VERSION ""

NS_ :

BS_:

BU_: ICC_ICE DVR EPC BBCM PCL PLG EAMP CMSM SBOX AVAS FLZCU RXCU_HCU CGW TBOX BNCM CWC FRZCU

BO_ 1238 ICC_TMS_32: 32 ICC_ICE
 SG_ ICC_CFSSwitch : 17|2@0+ (1,0) [0|3] "" Vector__XXX
 SG_ ICC_CFSLevelSet : 20|3@0+ (1,0) [0|7] "" Vector__XXX
 SG_ ICC_CFSPosSet : 23|2@0+ (1,0) [0|3] "" Vector__XXX
 SG_ ICC_PM25Switch : 25|2@0+ (1,0) [0|3] "" Vector__XXX
 SG_ ICC_AQSSwitch : 27|2@0+ (1,0) [0|3] "" Vector__XXX
 SG_ ICC_SecSetTemp_C : 36|5@0+ (0.5,15.5) [15.5|30.5] "℃" Vector__XXX
 SG_ ICC_SecFaceKeySts : 39|2@0+ (1,0) [0|3] "" Vector__XXX
 SG_ ICC_SecFootKeySts : 41|2@0+ (1,0) [0|3] "" Vector__XXX
 SG_ ICC_SecBlowSpeedLevelKeySts : 45|4@0+ (1,0) [0|15] "" Vector__XXX
 SG_ ICC_SecAutoSwitch : 47|2@0+ (1,0) [0|3] "" Vector__XXX
 SG_ ICC_SecCLMSwitch : 49|2@0+ (1,0) [0|3] "" Vector__XXX
 SG_ ICC_ThrSetTemp_C : 54|5@0+ (0.5,15.5) [15.5|30.5] "℃" Vector__XXX
 SG_ ICC_ThrFaceKeySts : 57|2@0+ (1,0) [0|3] "" Vector__XXX
 SG_ ICC_ThrFootKeySts : 59|2@0+ (1,0) [0|3] "" Vector__XXX
 SG_ ICC_ThrBlowSpeedLevelKeySts : 63|4@0+ (1,0) [0|15] "" Vector__XXX
 SG_ ICC_ThrAutoSwitch : 81|2@0+ (1,0) [0|3] "" Vector__XXX
 SG_ ICC_ThrCLMSwitch : 83|2@0+ (1,0) [0|3] "" Vector__XXX
 SG_ ICC_ThrACRequestKeySts : 85|2@0+ (1,0) [0|3] "" Vector__XXX
 SG_ ICC_DFMSwitch : 87|2@0+ (1,0) [0|3] "" Vector__XXX

BO_ 1289 ICC_34: 32 ICC_ICE
 SG_ ICC_TirePressureDisplayUnit : 23|2@0+ (1,0) [0|3] ""  TBOX
 SG_ ICC_TireTemperatureDisplayUnit : 21|2@0+ (1,0) [0|3] ""  TBOX
 SG_ ICC_ToggleUnits : 19|2@0+ (1,0) [0|3] ""  TBOX
 SG_ ICC_BtConFlag : 28|3@0+ (1,0) [0|7] ""  SBOX,TBOX
 SG_ ICC_GPSSwitchSet : 25|2@0+ (1,0) [0|3] ""  TBOX

BO_ 1167 ICC_35: 32 ICC_ICE
 SG_ ICC_KeyDriveModememory : 17|2@0+ (1,0) [0|3] ""  FLZCU,RXCU_HCU
 SG_ ICC_DriveModeSet : 22|5@0+ (1,0) [0|31] ""  FLZCU,RXCU_HCU
 SG_ ICC_DRIFTModeSetReq : 25|2@0+ (1,0) [0|3] ""  FLZCU,RXCU_HCU
 SG_ ICC_EXPERTEIPBESPSet : 27|2@0+ (1,0) [0|3] ""  FLZCU,RXCU_HCU
 SG_ ICC_EXPERTEcoSet : 29|2@0+ (1,0) [0|3] ""  FLZCU,RXCU_HCU
 SG_ ICC_EXPERTNormSet : 31|2@0+ (1,0) [0|3] ""  FLZCU,RXCU_HCU
 SG_ ICC_EXPERTSportSet : 33|2@0+ (1,0) [0|3] ""  FLZCU,RXCU_HCU
 SG_ ICC_CrossaxisSet : 35|2@0+ (1,0) [0|3] ""  FLZCU,RXCU_HCU
 SG_ ICC_EXPERTRWDSet : 37|2@0+ (1,0) [0|3] ""  FLZCU,RXCU_HCU
 SG_ ICC_EXPERTAWDSet : 39|2@0+ (1,0) [0|3] ""  FLZCU,RXCU_HCU
 SG_ ICC_EXPERTAutoSet : 41|2@0+ (1,0) [0|3] ""  FLZCU,RXCU_HCU
 SG_ ICC_CLIMBSet : 43|2@0+ (1,0) [0|3] ""  FLZCU,RXCU_HCU
 SG_ ICC_DriveModeExitSet : 45|2@0+ (1,0) [0|3] ""  FLZCU,RXCU_HCU
 SG_ ICC_CCOSwtReq : 49|2@0+ (1,0) [0|3] "" Vector__XXX
 SG_ ICC_TABSwtReq : 51|2@0+ (1,0) [0|3] "" Vector__XXX
 SG_ ICC_Confidencelevel : 62|7@0+ (1,-1) [0|100] "%"  FLZCU,RXCU_HCU
 SG_ ICC_V2L_IntlDisChg : 81|2@0+ (1,0) [0|3] ""  FLZCU,RXCU_HCU
 SG_ ICC_ExhibitionModeSwitch : 83|2@0+ (1,0) [0|3] ""  FLZCU,RXCU_HCU
 SG_ ICC_TrailerMode : 85|2@0+ (1,0) [0|3] ""  FLZCU,RXCU_HCU
 SG_ ICC_V2L_DisChgMem : 87|2@0+ (1,0) [0|3] ""  FLZCU,RXCU_HCU
 SG_ ICC_DrivePowerDispSet : 89|2@0+ (1,0) [0|3] ""  FLZCU,RXCU_HCU
 SG_ ICC_WLTC_to_CLTC_Mode : 91|2@0+ (1,0) [0|3] ""  FLZCU,RXCU_HCU
 SG_ ICC_StopChrgnSwitch : 93|2@0+ (1,0) [0|3] ""  FLZCU,RXCU_HCU
 SG_ ICC_StopChrgnMode : 95|2@0+ (1,0) [0|3] ""  FLZCU,RXCU_HCU
 SG_ ICC_RegenerateLevelCtrl : 98|3@0+ (1,0) [0|7] ""  FLZCU,RXCU_HCU
 SG_ ICC_SinglePedalMem : 100|2@0+ (1,0) [0|3] ""  FLZCU,RXCU_HCU
 SG_ ICC_FuelDetnSwt : 102|2@0+ (1,0) [0|3] ""  FLZCU,RXCU_HCU
 SG_ ICC_FuelDetnState : 105|2@0+ (1,0) [0|3] ""  FLZCU,RXCU_HCU
 SG_ ICC_FuelDetnOpDefeated : 107|2@0+ (1,0) [0|3] ""  FLZCU,RXCU_HCU
 SG_ ICC_HVDownRepairMode : 109|2@0+ (1,0) [0|3] ""  FLZCU,RXCU_HCU
 SG_ ICC_UTURNSnowSet : 111|2@0+ (1,0) [0|3] ""  FLZCU,RXCU_HCU
 SG_ ICC_UTURNSandSet : 113|2@0+ (1,0) [0|3] ""  FLZCU,RXCU_HCU
 SG_ ICC_UTURNMudSet : 115|2@0+ (1,0) [0|3] ""  FLZCU,RXCU_HCU
 SG_ ICC_UTURNGrassSet : 117|2@0+ (1,0) [0|3] ""  FLZCU,RXCU_HCU
 SG_ ICC_RestoreDefaults_48Fh : 119|2@0+ (1,0) [0|3] "" Vector__XXX
 SG_ ICC_LTCDispSet2 : 124|2@0+ (1,0) [0|3] ""  FLZCU,RXCU_HCU
 SG_ ICC_SetSocManage : 127|3@0+ (1,0) [0|7] ""  FLZCU,RXCU_HCU

BO_ 1326 ICC_BD_36: 8 ICC_ICE
 SG_ ICC_DWDOnOff_Req : 17|2@0+ (1,0) [0|3] "" Vector__XXX
 SG_ ICC_ContainerLightSet : 19|2@0+ (1,0) [0|3] ""  FLZCU

BO_ 1331 ICC_IC_37: 32 ICC_ICE
 SG_ ICC_RLSeatEasyEntryExitSet : 17|2@0+ (1,0) [0|3] ""  BBCM,PCL
 SG_ ICC_RRSeatEasyEntryExitSet : 19|2@0+ (1,0) [0|3] ""  BBCM,PCL
 SG_ ICC_RLMemoryRecoveryCmd : 21|2@0+ (1,0) [0|3] ""  BBCM,PCL
 SG_ ICC_RRMemoryRecoveryCmd : 23|2@0+ (1,0) [0|3] ""  BBCM,PCL
 SG_ ICC_RLSitPosnlocation : 25|2@0+ (1,0) [0|3] ""  BBCM,PCL
 SG_ ICC_RRSitPosnlocation : 27|2@0+ (1,0) [0|3] ""  BBCM,PCL
 SG_ ICC_CMSMDisplaySwitch : 29|2@0+ (1,0) [0|3] ""  CMSM
 SG_ ICC_CMSMDisplayAdjustmode : 31|2@0+ (1,0) [0|3] ""  CMSM
 SG_ ICC_CMSMSetstandardSwitch : 33|2@0+ (1,0) [0|3] ""  CMSM
 SG_ ICC_LeftPedalControl : 35|2@0+ (1,0) [0|3] ""  EPC
 SG_ ICC_RightPedalControl : 37|2@0+ (1,0) [0|3] ""  EPC
 SG_ ICC_EPCEnable : 39|2@0+ (1,0) [0|3] ""  EPC
 SG_ ICC_AMPKTVvoiceVolumeSet : 45|6@0+ (1,0) [0|63] ""  EAMP
 SG_ ICC_AMPA2BENCSoundReq : 47|2@0+ (1,0) [0|3] ""  EAMP
 SG_ ICC_AMPENCVolumeSet : 53|6@0+ (1,0) [0|63] ""  EAMP
 SG_ ICC_AMPA2BChimeSoundReq : 55|2@0+ (1,0) [0|3] ""  EAMP
 SG_ Set_AMPSoundFocus_2 : 63|4@0+ (1,0) [0|15] ""  EAMP
 SG_ ICC_AMPA2BKTVvoiceSoundReq : 58|3@0+ (1,0) [0|7] ""  EAMP
 SG_ ICC_MedStatusSet : 81|2@0+ (1,0) [0|3] ""  FLZCU
 SG_ Set_AMPLoudness : 83|2@0+ (1,0) [0|3] "" Vector__XXX
 SG_ ICC_MedAreaSet : 87|4@0+ (1,0) [0|15] ""  BBCM,PCL,FLZCU
 SG_ ICC_LeftElectricPedalsSet : 89|2@0+ (1,0) [0|3] ""  EPC
 SG_ ICC_RightElectricPedalsSet : 91|2@0+ (1,0) [0|3] ""  EPC
 SG_ ICC_NapAreaSet2 : 95|3@0+ (1,0) [0|7] ""  BBCM,PCL,FLZCU
 SG_ ICC_DisplayAdjustrAngReq : 103|8@0+ (1,0) [0|255] "°"  CMSM
 SG_ Set_AMPKeyVolume : 119|6@0+ (1,0) [0|63] ""  EAMP
 SG_ ICC_CMSMTouchSts : 123|2@0+ (1,0) [0|3] ""  CMSM
 SG_ Set_AMPExSoundmode : 113|3@0+ (1,0) [0|7] "" Vector__XXX
 SG_ Set_AMPA2BENCSound : 126|3@0+ (1,0) [0|7] "" Vector__XXX

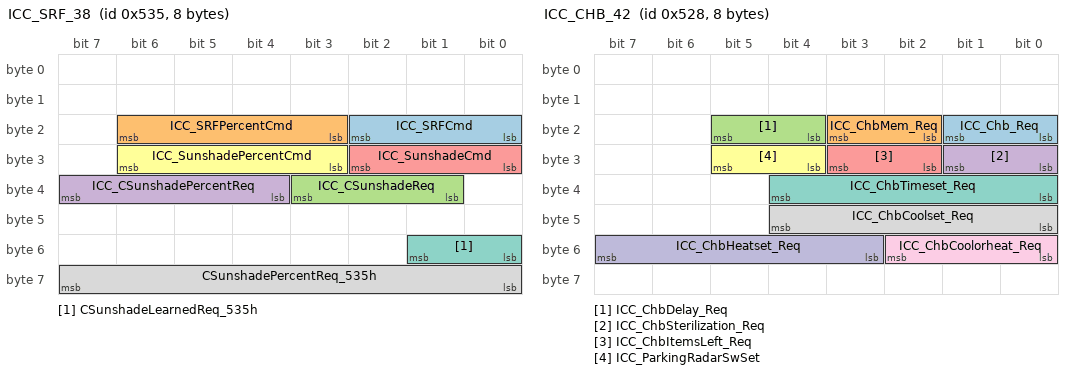
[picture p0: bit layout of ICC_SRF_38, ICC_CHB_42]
BO_ 1333 ICC_SRF_38: 8 ICC_ICE
 SG_ ICC_SRFCmd : 18|3@0+ (1,0) [0|7] ""  FLZCU
 SG_ ICC_SRFPercentCmd : 22|4@0+ (1,0) [0|15] ""  FLZCU
 SG_ ICC_CSunshadeReq : 35|3@0+ (1,0) [0|7] ""  FLZCU
 SG_ ICC_CSunshadePercentReq : 39|4@0+ (1,0) [0|15] ""  FLZCU
 SG_ ICC_SunshadeCmd : 26|3@0+ (1,0) [0|7] ""  FLZCU
 SG_ ICC_SunshadePercentCmd : 30|4@0+ (1,0) [0|15] ""  FLZCU
 SG_ CSunshadeLearnedReq_535h : 49|2@0+ (1,0) [0|3] "" Vector__XXX
 SG_ CSunshadePercentReq_535h : 63|8@0+ (1,0) [0|255] "%" Vector__XXX

BO_ 1335 ICC_CH_39: 32 ICC_ICE
 SG_ ICC_SET_EPS_SteerReturnRmdSts : 17|2@0+ (1,0) [0|3] ""  CGW
 SG_ ICC_SET_MFSShake : 19|2@0+ (1,0) [0|3] ""  CGW
 SG_ ICC_DMS_1_DistractionLevel : 22|3@0+ (1,0) [0|7] ""  CGW
 SG_ ICC_SET_EPS_AsociWithDrvModSts : 25|2@0+ (1,0) [0|3] ""  CGW
 SG_ ICC_OverLoadWarnShieldSet : 27|2@0+ (1,0) [0|3] ""  CGW
 SG_ ICC_BSWReq : 29|2@0+ (1,0) [0|3] ""  CGW
 SG_ ICC_horizontalReq : 31|2@0+ (1,0) [0|3] ""  CGW
 SG_ ICC_RolloverSetCmd : 33|2@0+ (1,0) [0|3] ""  CGW
 SG_ ICC_TrekThroughReq_537h : 35|2@0+ (1,0) [0|3] ""  CGW
 SG_ ICC_InflateReq_537h : 37|2@0+ (1,0) [0|3] ""  CGW
 SG_ ICC_UndergroundModeReq_537h : 39|2@0+ (1,0) [0|3] ""  CGW

BO_ 1337 ICC_TMS_40: 16 ICC_ICE
 SG_ ICC_SET_BT_ReduceWindSpeed : 17|2@0+ (1,0) [0|3] ""  CGW
 SG_ ICC_SET_IPM_FirstBlowing : 19|2@0+ (1,0) [0|3] ""  CGW
 SG_ ICC_SET_IPM_BlowerDelay : 21|2@0+ (1,0) [0|3] ""  CGW
 SG_ ICC_SET_CirculationInTunnels : 23|2@0+ (1,0) [0|3] ""  CGW
 SG_ ICC_UVCLuminanceReq : 25|2@0+ (1,0) [0|3] ""  CGW
 SG_ ICC_UVCControlReq : 27|2@0+ (1,0) [0|3] ""  CGW
 SG_ ICC_CrossCountryCoolingReq : 29|2@0+ (1,0) [0|3] ""  CGW
 SG_ ICC_KeepWarmReq : 31|2@0+ (1,0) [0|3] ""  CGW
 SG_ ICC_keepwarmSetTemperatureReq : 39|8@0+ (1,0) [0|255] ""  CGW
 SG_ ICC_ParkingAirConditioning : 41|2@0+ (1,0) [0|3] ""  CGW
 SG_ ICC_CoolantFill_Req : 43|2@0+ (1,0) [0|3] ""  CGW
 SG_ ICC_FraganceLightoffReq : 45|2@0+ (1,0) [0|3] ""  CGW
 SG_ ICC_FraganceMemoffReq : 47|2@0+ (1,0) [0|3] ""  CGW
 SG_ ICC_CFSCycleLevel : 53|3@0+ (1,0) [0|7] ""  CGW
 SG_ ICC_TimingLevel : 50|3@0+ (1,0) [0|7] ""  CGW
 SG_ ICC_ModeAdjustDisplaySts : 63|4@0+ (1,0) [0|15] ""  CGW
 SG_ ICC_AirPurgeReminderReq : 55|2@0+ (1,0) [0|3] ""  CGW
 SG_ ICC_BiochemicalFuncReq : 59|2@0+ (1,0) [0|3] ""  CGW
 SG_ ICC_TimedVentilationReq : 57|2@0+ (1,0) [0|3] ""  CGW
 SG_ ICC_PetmodeSetTemperature_L_C : 87|5@0+ (0.5,15.5) [15.5|30.5] "℃"  CGW
 SG_ ICC_PetModeSetTemperature_R_C : 82|5@0+ (0.5,15.5) [15.5|30.5] "℃"  CGW
 SG_ ICC_PetModeSetCLMOn : 93|2@0+ (1,0) [0|3] ""  CGW
 SG_ ICC_PetModeSetAutoKeySts : 91|2@0+ (1,0) [0|3] ""  CGW
 SG_ ICC_PetModeSetCirculationSts : 89|2@0+ (1,0) [0|3] ""  CGW
 SG_ ICC_ISSFctCmd_539h : 97|2@0+ (1,0) [0|3] ""  CGW

BO_ 1318 ICC_TDL_41: 8 ICC_ICE
 SG_ ICC_SET_TDL_Rhythm_Switch : 1|2@0+ (1,0) [0|3] ""  FLZCU
 SG_ ICC_SET_TDL_Switch : 3|2@0+ (1,0) [0|3] ""  FLZCU
 SG_ ICC_SET_TDL_ColourModeAdj : 6|3@0+ (1,0) [0|7] ""  FLZCU
 SG_ ICC_VoiceWake : 13|3@0+ (1,0) [0|7] ""  FLZCU
 SG_ ICC_TDLAssociatedDriverModeSw : 15|2@0+ (1,0) [0|3] ""  FLZCU
 SG_ ICC_TDL_RhythmReq : 10|3@0+ (1,0) [0|7] ""  FLZCU
 SG_ ICC_SET_ApiluminanceAdj : 19|4@0+ (1,0) [0|15] ""  FLZCU
 SG_ ICC_SET_MusicLoudness_120HZ : 23|4@0+ (1,0) [0|15] ""  FLZCU
 SG_ ICC_SET_MusicLoudness_250HZ : 27|4@0+ (1,0) [0|15] ""  FLZCU
 SG_ ICC_SET_MusicLoudness_500HZ : 31|4@0+ (1,0) [0|15] ""  FLZCU
 SG_ ICC_SET_MusicLoudness_1000HZ : 35|4@0+ (1,0) [0|15] ""  FLZCU
 SG_ ICC_SET_MusicLoudness_1500HZ : 39|4@0+ (1,0) [0|15] ""  FLZCU
 SG_ ICC_SET_MusicLoudness_2000HZ : 43|4@0+ (1,0) [0|15] ""  FLZCU
 SG_ ICC_SET_MusicLoudness_6000HZ : 47|4@0+ (1,0) [0|15] ""  FLZCU
 SG_ ICC_TDL_FlowLightSw : 51|2@0+ (1,0) [0|3] ""  FLZCU
 SG_ ICC_TDL_FlowLightModeAdj : 54|3@0+ (1,0) [0|7] ""  FLZCU
 SG_ ICC_SET_256ColourAdj : 48|9@0+ (1,0) [0|256] ""  FLZCU

BO_ 1320 ICC_CHB_42: 8 ICC_ICE
 SG_ ICC_Chb_Req : 17|2@0+ (1,0) [0|3] "" Vector__XXX
 SG_ ICC_ChbMem_Req : 19|2@0+ (1,0) [0|3] "" Vector__XXX
 SG_ ICC_ChbDelay_Req : 21|2@0+ (1,0) [0|3] "" Vector__XXX
 SG_ ICC_ChbSterilization_Req : 25|2@0+ (1,0) [0|3] "" Vector__XXX
 SG_ ICC_ChbItemsLeft_Req : 27|2@0+ (1,0) [0|3] "" Vector__XXX
 SG_ ICC_ParkingRadarSwSet : 29|2@0+ (1,0) [0|3] "" Vector__XXX
 SG_ ICC_ChbTimeset_Req : 36|5@0+ (1,0) [0|31] "h" Vector__XXX
 SG_ ICC_ChbCoolset_Req : 44|5@0+ (1,0) [0|31] "" Vector__XXX
 SG_ ICC_ChbCoolorheat_Req : 50|3@0+ (1,0) [0|7] "" Vector__XXX
 SG_ ICC_ChbHeatset_Req : 55|5@0+ (1,0) [0|31] "" Vector__XXX

BO_ 1360 ICC_LC_42: 64 ICC_ICE
 SG_ ICC_LISD_DisplaySwitch : 1|2@0+ (1,0) [0|3] ""  FLZCU
 SG_ ICC_LISD_ParkingShowCMD : 3|2@0+ (1,0) [0|3] ""  FLZCU
 SG_ ICC_RISD_DisplaySwitch : 7|2@0+ (1,0) [0|3] ""  FLZCU
 SG_ ICC_RISD_ParkingShowCMD : 9|2@0+ (1,0) [0|3] ""  FLZCU
 SG_ ICC_LogoParkingReq : 13|2@0+ (1,0) [0|3] ""  FLZCU
 SG_ ICC_LogoChargingReq : 15|2@0+ (1,0) [0|3] ""  FLZCU
 SG_ ICC_DRLSw : 17|2@0+ (1,0) [0|3] ""  FLZCU
 SG_ ICC_LISD_ParkingShowMod : 27|4@0+ (1,0) [0|15] ""  FLZCU
 SG_ ICC_RISD_ParkingShowMod : 31|4@0+ (1,0) [0|15] ""  FLZCU
 SG_ ICC_PenetrationLampSetF : 37|2@0+ (1,0) [0|3] ""  FLZCU
 SG_ ICC_MusicLampShowSW : 35|2@0+ (1,0) [0|3] ""  FLZCU
 SG_ ICC_LogoColorReq : 33|9@0+ (1,0) [0|511] ""  FLZCU
 SG_ ICC_XDriveMode : 40|5@0+ (1,0) [0|31] ""  FLZCU,RXCU_HCU
 SG_ ICC_DowWaringSw : 57|2@0+ (1,0) [0|3] ""  FLZCU
 SG_ ICC_CarSearhSetSwitchSts : 59|2@0+ (1,0) [0|3] ""  FLZCU

BO_ 1362 ICC_LISD_43: 64 ICC_ICE
 SG_ ICC_LISD_FrameCounter : 1|2@0+ (1,0) [0|3] "" Vector__XXX
 SG_ ICC_LISD_RollingCounter : 3|2@0+ (1,0) [0|3] "" Vector__XXX
 SG_ ICC_LISD_Pixel1_OnOff : 8|1@0+ (1,0) [0|1] "" Vector__XXX
 SG_ ICC_LISD_Pixel2_OnOff : 9|1@0+ (1,0) [0|1] "" Vector__XXX
 SG_ ICC_LISD_Pixel3_OnOff : 10|1@0+ (1,0) [0|1] "" Vector__XXX
 SG_ ICC_LISD_Pixel4_OnOff : 11|1@0+ (1,0) [0|1] "" Vector__XXX
 SG_ ICC_LISD_Pixel5_OnOff : 12|1@0+ (1,0) [0|1] "" Vector__XXX
 SG_ ICC_LISD_Pixel6_OnOff : 13|1@0+ (1,0) [0|1] "" Vector__XXX
 SG_ ICC_LISD_Pixel7_OnOff : 14|1@0+ (1,0) [0|1] "" Vector__XXX
 SG_ ICC_LISD_Pixel8_OnOff : 15|1@0+ (1,0) [0|1] "" Vector__XXX
 SG_ ICC_LISD_Pixel9_OnOff : 16|1@0+ (1,0) [0|1] "" Vector__XXX
 SG_ ICC_LISD_Pixel10_OnOff : 17|1@0+ (1,0) [0|1] "" Vector__XXX
 SG_ ICC_LISD_Pixel11_OnOff : 18|1@0+ (1,0) [0|1] "" Vector__XXX
 SG_ ICC_LISD_Pixel12_OnOff : 19|1@0+ (1,0) [0|1] "" Vector__XXX
 SG_ ICC_LISD_Pixel13_OnOff : 20|1@0+ (1,0) [0|1] "" Vector__XXX
 SG_ ICC_LISD_Pixel14_OnOff : 21|1@0+ (1,0) [0|1] "" Vector__XXX
 SG_ ICC_LISD_Pixel15_OnOff : 22|1@0+ (1,0) [0|1] "" Vector__XXX
 SG_ ICC_LISD_Pixel16_OnOff : 23|1@0+ (1,0) [0|1] "" Vector__XXX
 SG_ ICC_LISD_Pixel17_OnOff : 24|1@0+ (1,0) [0|1] "" Vector__XXX
 SG_ ICC_LISD_Pixel18_OnOff : 25|1@0+ (1,0) [0|1] "" Vector__XXX
 SG_ ICC_LISD_Pixel19_OnOff : 26|1@0+ (1,0) [0|1] "" Vector__XXX
 SG_ ICC_LISD_Pixel20_OnOff : 27|1@0+ (1,0) [0|1] "" Vector__XXX
 SG_ ICC_LISD_Pixel21_OnOff : 28|1@0+ (1,0) [0|1] "" Vector__XXX
 SG_ ICC_LISD_Pixel22_OnOff : 29|1@0+ (1,0) [0|1] "" Vector__XXX
 SG_ ICC_LISD_Pixel23_OnOff : 30|1@0+ (1,0) [0|1] "" Vector__XXX
 SG_ ICC_LISD_Pixel24_OnOff : 31|1@0+ (1,0) [0|1] "" Vector__XXX
 SG_ ICC_LISD_Pixel25_OnOff : 32|1@0+ (1,0) [0|1] "" Vector__XXX
 SG_ ICC_LISD_Pixel26_OnOff : 33|1@0+ (1,0) [0|1] "" Vector__XXX
 SG_ ICC_LISD_Pixel27_OnOff : 34|1@0+ (1,0) [0|1] "" Vector__XXX
 SG_ ICC_LISD_Pixel28_OnOff : 35|1@0+ (1,0) [0|1] "" Vector__XXX
 SG_ ICC_LISD_Pixel29_OnOff : 36|1@0+ (1,0) [0|1] "" Vector__XXX
 SG_ ICC_LISD_Pixel30_OnOff : 37|1@0+ (1,0) [0|1] "" Vector__XXX
 SG_ ICC_LISD_Pixel31_OnOff : 38|1@0+ (1,0) [0|1] "" Vector__XXX
 SG_ ICC_LISD_Pixel32_OnOff : 39|1@0+ (1,0) [0|1] "" Vector__XXX
 SG_ ICC_LISD_Pixel33_OnOff : 40|1@0+ (1,0) [0|1] "" Vector__XXX
 SG_ ICC_LISD_Pixel34_OnOff : 41|1@0+ (1,0) [0|1] "" Vector__XXX
 SG_ ICC_LISD_Pixel35_OnOff : 42|1@0+ (1,0) [0|1] "" Vector__XXX
 SG_ ICC_LISD_Pixel36_OnOff : 43|1@0+ (1,0) [0|1] "" Vector__XXX
 SG_ ICC_LISD_Pixel37_OnOff : 44|1@0+ (1,0) [0|1] "" Vector__XXX
 SG_ ICC_LISD_Pixel38_OnOff : 45|1@0+ (1,0) [0|1] "" Vector__XXX
 SG_ ICC_LISD_Pixel39_OnOff : 46|1@0+ (1,0) [0|1] "" Vector__XXX
 SG_ ICC_LISD_Pixel40_OnOff : 47|1@0+ (1,0) [0|1] "" Vector__XXX
 SG_ ICC_LISD_Pixel41_OnOff : 48|1@0+ (1,0) [0|1] "" Vector__XXX
 SG_ ICC_LISD_Pixel42_OnOff : 49|1@0+ (1,0) [0|1] "" Vector__XXX
 SG_ ICC_LISD_Pixel43_OnOff : 50|1@0+ (1,0) [0|1] "" Vector__XXX
 SG_ ICC_LISD_Pixel44_OnOff : 51|1@0+ (1,0) [0|1] "" Vector__XXX
 SG_ ICC_LISD_Pixel45_OnOff : 52|1@0+ (1,0) [0|1] "" Vector__XXX
 SG_ ICC_LISD_Pixel46_OnOff : 53|1@0+ (1,0) [0|1] "" Vector__XXX
 SG_ ICC_LISD_Pixel47_OnOff : 54|1@0+ (1,0) [0|1] "" Vector__XXX
 SG_ ICC_LISD_Pixel48_OnOff : 55|1@0+ (1,0) [0|1] "" Vector__XXX
 SG_ ICC_LISD_Pixel49_OnOff : 56|1@0+ (1,0) [0|1] "" Vector__XXX
 SG_ ICC_LISD_Pixel50_OnOff : 57|1@0+ (1,0) [0|1] "" Vector__XXX
 SG_ ICC_LISD_Pixel51_OnOff : 58|1@0+ (1,0) [0|1] "" Vector__XXX
 SG_ ICC_LISD_Pixel52_OnOff : 59|1@0+ (1,0) [0|1] "" Vector__XXX
 SG_ ICC_LISD_Pixel53_OnOff : 60|1@0+ (1,0) [0|1] "" Vector__XXX
 SG_ ICC_LISD_Pixel54_OnOff : 61|1@0+ (1,0) [0|1] "" Vector__XXX
 SG_ ICC_LISD_Pixel55_OnOff : 62|1@0+ (1,0) [0|1] "" Vector__XXX
 SG_ ICC_LISD_Pixel56_OnOff : 63|1@0+ (1,0) [0|1] "" Vector__XXX
 SG_ ICC_LISD_Pixel57_OnOff : 64|1@0+ (1,0) [0|1] "" Vector__XXX
 SG_ ICC_LISD_Pixel58_OnOff : 65|1@0+ (1,0) [0|1] "" Vector__XXX
 SG_ ICC_LISD_Pixel59_OnOff : 66|1@0+ (1,0) [0|1] "" Vector__XXX
 SG_ ICC_LISD_Pixel60_OnOff : 67|1@0+ (1,0) [0|1] "" Vector__XXX
 SG_ ICC_LISD_Pixel61_OnOff : 68|1@0+ (1,0) [0|1] "" Vector__XXX
 SG_ ICC_LISD_Pixel62_OnOff : 69|1@0+ (1,0) [0|1] "" Vector__XXX
 SG_ ICC_LISD_Pixel63_OnOff : 70|1@0+ (1,0) [0|1] "" Vector__XXX
 SG_ ICC_LISD_Pixel64_OnOff : 71|1@0+ (1,0) [0|1] "" Vector__XXX
 SG_ ICC_LISD_Pixel65_OnOff : 72|1@0+ (1,0) [0|1] "" Vector__XXX
 SG_ ICC_LISD_Pixel66_OnOff : 73|1@0+ (1,0) [0|1] "" Vector__XXX
 SG_ ICC_LISD_Pixel67_OnOff : 74|1@0+ (1,0) [0|1] "" Vector__XXX
 SG_ ICC_LISD_Pixel68_OnOff : 75|1@0+ (1,0) [0|1] "" Vector__XXX
 SG_ ICC_LISD_Pixel69_OnOff : 76|1@0+ (1,0) [0|1] "" Vector__XXX
 SG_ ICC_LISD_Pixel70_OnOff : 77|1@0+ (1,0) [0|1] "" Vector__XXX
 SG_ ICC_LISD_Pixel71_OnOff : 78|1@0+ (1,0) [0|1] "" Vector__XXX
 SG_ ICC_LISD_Pixel72_OnOff : 79|1@0+ (1,0) [0|1] "" Vector__XXX
 SG_ ICC_LISD_Pixel73_OnOff : 80|1@0+ (1,0) [0|1] "" Vector__XXX
 SG_ ICC_LISD_Pixel74_OnOff : 81|1@0+ (1,0) [0|1] "" Vector__XXX
 SG_ ICC_LISD_Pixel75_OnOff : 82|1@0+ (1,0) [0|1] "" Vector__XXX
 SG_ ICC_LISD_Pixel76_OnOff : 83|1@0+ (1,0) [0|1] "" Vector__XXX
 SG_ ICC_LISD_Pixel77_OnOff : 84|1@0+ (1,0) [0|1] "" Vector__XXX
 SG_ ICC_LISD_Pixel78_OnOff : 85|1@0+ (1,0) [0|1] "" Vector__XXX
 SG_ ICC_LISD_Pixel79_OnOff : 86|1@0+ (1,0) [0|1] "" Vector__XXX
 SG_ ICC_LISD_Pixel80_OnOff : 87|1@0+ (1,0) [0|1] "" Vector__XXX
 SG_ ICC_LISD_Pixel81_OnOff : 88|1@0+ (1,0) [0|1] "" Vector__XXX
 SG_ ICC_LISD_Pixel82_OnOff : 89|1@0+ (1,0) [0|1] "" Vector__XXX
 SG_ ICC_LISD_Pixel83_OnOff : 90|1@0+ (1,0) [0|1] "" Vector__XXX
 SG_ ICC_LISD_Pixel84_OnOff : 91|1@0+ (1,0) [0|1] "" Vector__XXX
 SG_ ICC_LISD_Pixel85_OnOff : 92|1@0+ (1,0) [0|1] "" Vector__XXX
 SG_ ICC_LISD_Pixel86_OnOff : 93|1@0+ (1,0) [0|1] "" Vector__XXX
 SG_ ICC_LISD_Pixel87_OnOff : 94|1@0+ (1,0) [0|1] "" Vector__XXX
 SG_ ICC_LISD_Pixel88_OnOff : 95|1@0+ (1,0) [0|1] "" Vector__XXX
 SG_ ICC_LISD_Pixel89_OnOff : 96|1@0+ (1,0) [0|1] "" Vector__XXX
 SG_ ICC_LISD_Pixel90_OnOff : 97|1@0+ (1,0) [0|1] "" Vector__XXX
 SG_ ICC_LISD_Pixel91_OnOff : 98|1@0+ (1,0) [0|1] "" Vector__XXX
 SG_ ICC_LISD_Pixel92_OnOff : 99|1@0+ (1,0) [0|1] "" Vector__XXX
 SG_ ICC_LISD_Pixel93_OnOff : 100|1@0+ (1,0) [0|1] "" Vector__XXX
 SG_ ICC_LISD_Pixel94_OnOff : 101|1@0+ (1,0) [0|1] "" Vector__XXX
 SG_ ICC_LISD_Pixel95_OnOff : 102|1@0+ (1,0) [0|1] "" Vector__XXX
 SG_ ICC_LISD_Pixel96_OnOff : 103|1@0+ (1,0) [0|1] "" Vector__XXX
 SG_ ICC_LISD_Pixel97_OnOff : 104|1@0+ (1,0) [0|1] "" Vector__XXX
 SG_ ICC_LISD_Pixel98_OnOff : 105|1@0+ (1,0) [0|1] "" Vector__XXX
 SG_ ICC_LISD_Pixel99_OnOff : 106|1@0+ (1,0) [0|1] "" Vector__XXX
 SG_ ICC_LISD_Pixel100_OnOff : 107|1@0+ (1,0) [0|1] "" Vector__XXX
 SG_ ICC_LISD_Pixel101_OnOff : 108|1@0+ (1,0) [0|1] "" Vector__XXX
 SG_ ICC_LISD_Pixel102_OnOff : 109|1@0+ (1,0) [0|1] "" Vector__XXX
 SG_ ICC_LISD_Pixel103_OnOff : 110|1@0+ (1,0) [0|1] "" Vector__XXX
 SG_ ICC_LISD_Pixel104_OnOff : 111|1@0+ (1,0) [0|1] "" Vector__XXX
 SG_ ICC_LISD_Pixel105_OnOff : 112|1@0+ (1,0) [0|1] "" Vector__XXX
 SG_ ICC_LISD_Pixel106_OnOff : 113|1@0+ (1,0) [0|1] "" Vector__XXX
 SG_ ICC_LISD_Pixel107_OnOff : 114|1@0+ (1,0) [0|1] "" Vector__XXX
 SG_ ICC_LISD_Pixel108_OnOff : 115|1@0+ (1,0) [0|1] "" Vector__XXX
 SG_ ICC_LISD_Pixel109_OnOff : 116|1@0+ (1,0) [0|1] "" Vector__XXX
 SG_ ICC_LISD_Pixel110_OnOff : 117|1@0+ (1,0) [0|1] "" Vector__XXX
 SG_ ICC_LISD_Pixel111_OnOff : 118|1@0+ (1,0) [0|1] "" Vector__XXX
 SG_ ICC_LISD_Pixel112_OnOff : 119|1@0+ (1,0) [0|1] "" Vector__XXX
 SG_ ICC_LISD_Pixel113_OnOff : 120|1@0+ (1,0) [0|1] "" Vector__XXX
 SG_ ICC_LISD_Pixel114_OnOff : 121|1@0+ (1,0) [0|1] "" Vector__XXX
 SG_ ICC_LISD_Pixel115_OnOff : 122|1@0+ (1,0) [0|1] "" Vector__XXX
 SG_ ICC_LISD_Pixel116_OnOff : 123|1@0+ (1,0) [0|1] "" Vector__XXX
 SG_ ICC_LISD_Pixel117_OnOff : 124|1@0+ (1,0) [0|1] "" Vector__XXX
 SG_ ICC_LISD_Pixel118_OnOff : 125|1@0+ (1,0) [0|1] "" Vector__XXX
 SG_ ICC_LISD_Pixel119_OnOff : 126|1@0+ (1,0) [0|1] "" Vector__XXX
 SG_ ICC_LISD_Pixel120_OnOff : 127|1@0+ (1,0) [0|1] "" Vector__XXX
 SG_ ICC_LISD_Pixel121_OnOff : 128|1@0+ (1,0) [0|1] "" Vector__XXX
 SG_ ICC_LISD_Pixel122_OnOff : 129|1@0+ (1,0) [0|1] "" Vector__XXX
 SG_ ICC_LISD_Pixel123_OnOff : 130|1@0+ (1,0) [0|1] "" Vector__XXX
 SG_ ICC_LISD_Pixel124_OnOff : 131|1@0+ (1,0) [0|1] "" Vector__XXX
 SG_ ICC_LISD_Pixel125_OnOff : 132|1@0+ (1,0) [0|1] "" Vector__XXX
 SG_ ICC_LISD_Pixel126_OnOff : 133|1@0+ (1,0) [0|1] "" Vector__XXX
 SG_ ICC_LISD_Pixel127_OnOff : 134|1@0+ (1,0) [0|1] "" Vector__XXX
 SG_ ICC_LISD_Pixel128_OnOff : 135|1@0+ (1,0) [0|1] "" Vector__XXX
 SG_ ICC_LISD_Pixel129_OnOff : 136|1@0+ (1,0) [0|1] "" Vector__XXX
 SG_ ICC_LISD_Pixel130_OnOff : 137|1@0+ (1,0) [0|1] "" Vector__XXX
 SG_ ICC_LISD_Pixel131_OnOff : 138|1@0+ (1,0) [0|1] "" Vector__XXX
 SG_ ICC_LISD_Pixel132_OnOff : 139|1@0+ (1,0) [0|1] "" Vector__XXX
 SG_ ICC_LISD_Pixel133_OnOff : 140|1@0+ (1,0) [0|1] "" Vector__XXX
 SG_ ICC_LISD_Pixel134_OnOff : 141|1@0+ (1,0) [0|1] "" Vector__XXX
 SG_ ICC_LISD_Pixel135_OnOff : 142|1@0+ (1,0) [0|1] "" Vector__XXX
 SG_ ICC_LISD_Pixel136_OnOff : 143|1@0+ (1,0) [0|1] "" Vector__XXX
 SG_ ICC_LISD_Pixel137_OnOff : 144|1@0+ (1,0) [0|1] "" Vector__XXX
 SG_ ICC_LISD_Pixel138_OnOff : 145|1@0+ (1,0) [0|1] "" Vector__XXX
 SG_ ICC_LISD_Pixel139_OnOff : 146|1@0+ (1,0) [0|1] "" Vector__XXX
 SG_ ICC_LISD_Pixel140_OnOff : 147|1@0+ (1,0) [0|1] "" Vector__XXX
 SG_ ICC_LISD_Pixel141_OnOff : 148|1@0+ (1,0) [0|1] "" Vector__XXX
 SG_ ICC_LISD_Pixel142_OnOff : 149|1@0+ (1,0) [0|1] "" Vector__XXX
 SG_ ICC_LISD_Pixel143_OnOff : 150|1@0+ (1,0) [0|1] "" Vector__XXX
 SG_ ICC_LISD_Pixel144_OnOff : 151|1@0+ (1,0) [0|1] "" Vector__XXX
 SG_ ICC_LISD_Pixel145_OnOff : 152|1@0+ (1,0) [0|1] "" Vector__XXX
 SG_ ICC_LISD_Pixel146_OnOff : 153|1@0+ (1,0) [0|1] "" Vector__XXX
 SG_ ICC_LISD_Pixel147_OnOff : 154|1@0+ (1,0) [0|1] "" Vector__XXX
 SG_ ICC_LISD_Pixel148_OnOff : 155|1@0+ (1,0) [0|1] "" Vector__XXX
 SG_ ICC_LISD_Pixel149_OnOff : 156|1@0+ (1,0) [0|1] "" Vector__XXX
 SG_ ICC_LISD_Pixel150_OnOff : 157|1@0+ (1,0) [0|1] "" Vector__XXX
 SG_ ICC_LISD_Pixel151_OnOff : 158|1@0+ (1,0) [0|1] "" Vector__XXX
 SG_ ICC_LISD_Pixel152_OnOff : 159|1@0+ (1,0) [0|1] "" Vector__XXX
 SG_ ICC_LISD_Pixel153_OnOff : 160|1@0+ (1,0) [0|1] "" Vector__XXX
 SG_ ICC_LISD_Pixel154_OnOff : 161|1@0+ (1,0) [0|1] "" Vector__XXX
 SG_ ICC_LISD_Pixel155_OnOff : 162|1@0+ (1,0) [0|1] "" Vector__XXX
 SG_ ICC_LISD_Pixel156_OnOff : 163|1@0+ (1,0) [0|1] "" Vector__XXX
 SG_ ICC_LISD_Pixel157_OnOff : 164|1@0+ (1,0) [0|1] "" Vector__XXX
 SG_ ICC_LISD_Pixel158_OnOff : 165|1@0+ (1,0) [0|1] "" Vector__XXX
 SG_ ICC_LISD_Pixel159_OnOff : 166|1@0+ (1,0) [0|1] "" Vector__XXX
 SG_ ICC_LISD_Pixel160_OnOff : 167|1@0+ (1,0) [0|1] "" Vector__XXX
 SG_ ICC_LISD_Pixel161_OnOff : 168|1@0+ (1,0) [0|1] "" Vector__XXX
 SG_ ICC_LISD_Pixel162_OnOff : 169|1@0+ (1,0) [0|1] "" Vector__XXX
 SG_ ICC_LISD_Pixel163_OnOff : 170|1@0+ (1,0) [0|1] "" Vector__XXX
 SG_ ICC_LISD_Pixel164_OnOff : 171|1@0+ (1,0) [0|1] "" Vector__XXX
 SG_ ICC_LISD_Pixel165_OnOff : 172|1@0+ (1,0) [0|1] "" Vector__XXX
 SG_ ICC_LISD_Pixel166_OnOff : 173|1@0+ (1,0) [0|1] "" Vector__XXX
 SG_ ICC_LISD_Pixel167_OnOff : 174|1@0+ (1,0) [0|1] "" Vector__XXX
 SG_ ICC_LISD_Pixel168_OnOff : 175|1@0+ (1,0) [0|1] "" Vector__XXX
 SG_ ICC_LISD_Pixel169_OnOff : 176|1@0+ (1,0) [0|1] "" Vector__XXX
 SG_ ICC_LISD_Pixel170_OnOff : 177|1@0+ (1,0) [0|1] "" Vector__XXX
 SG_ ICC_LISD_Pixel171_OnOff : 178|1@0+ (1,0) [0|1] "" Vector__XXX
 SG_ ICC_LISD_Pixel172_OnOff : 179|1@0+ (1,0) [0|1] "" Vector__XXX
 SG_ ICC_LISD_Pixel173_OnOff : 180|1@0+ (1,0) [0|1] "" Vector__XXX
 SG_ ICC_LISD_Pixel174_OnOff : 181|1@0+ (1,0) [0|1] "" Vector__XXX
 SG_ ICC_LISD_Pixel175_OnOff : 182|1@0+ (1,0) [0|1] "" Vector__XXX
 SG_ ICC_LISD_Pixel176_OnOff : 183|1@0+ (1,0) [0|1] "" Vector__XXX
 SG_ ICC_LISD_Pixel177_OnOff : 184|1@0+ (1,0) [0|1] "" Vector__XXX
 SG_ ICC_LISD_Pixel178_OnOff : 185|1@0+ (1,0) [0|1] "" Vector__XXX
 SG_ ICC_LISD_Pixel179_OnOff : 186|1@0+ (1,0) [0|1] "" Vector__XXX
 SG_ ICC_LISD_Pixel180_OnOff : 187|1@0+ (1,0) [0|1] "" Vector__XXX
 SG_ ICC_LISD_Pixel181_OnOff : 188|1@0+ (1,0) [0|1] "" Vector__XXX
 SG_ ICC_LISD_Pixel182_OnOff : 189|1@0+ (1,0) [0|1] "" Vector__XXX
 SG_ ICC_LISD_Pixel183_OnOff : 190|1@0+ (1,0) [0|1] "" Vector__XXX
 SG_ ICC_LISD_Pixel184_OnOff : 191|1@0+ (1,0) [0|1] "" Vector__XXX
 SG_ ICC_LISD_Pixel185_OnOff : 192|1@0+ (1,0) [0|1] "" Vector__XXX
 SG_ ICC_LISD_Pixel186_OnOff : 193|1@0+ (1,0) [0|1] "" Vector__XXX
 SG_ ICC_LISD_Pixel187_OnOff : 194|1@0+ (1,0) [0|1] "" Vector__XXX
 SG_ ICC_LISD_Pixel188_OnOff : 195|1@0+ (1,0) [0|1] "" Vector__XXX
 SG_ ICC_LISD_Pixel189_OnOff : 196|1@0+ (1,0) [0|1] "" Vector__XXX
 SG_ ICC_LISD_Pixel190_OnOff : 197|1@0+ (1,0) [0|1] "" Vector__XXX
 SG_ ICC_LISD_Pixel191_OnOff : 198|1@0+ (1,0) [0|1] "" Vector__XXX
 SG_ ICC_LISD_Pixel192_OnOff : 199|1@0+ (1,0) [0|1] "" Vector__XXX
 SG_ ICC_LISD_Pixel193_OnOff : 200|1@0+ (1,0) [0|1] "" Vector__XXX
 SG_ ICC_LISD_Pixel194_OnOff : 201|1@0+ (1,0) [0|1] "" Vector__XXX
 SG_ ICC_LISD_Pixel195_OnOff : 202|1@0+ (1,0) [0|1] "" Vector__XXX
 SG_ ICC_LISD_Pixel196_OnOff : 203|1@0+ (1,0) [0|1] "" Vector__XXX
 SG_ ICC_LISD_Pixel197_OnOff : 204|1@0+ (1,0) [0|1] "" Vector__XXX
 SG_ ICC_LISD_Pixel198_OnOff : 205|1@0+ (1,0) [0|1] "" Vector__XXX
 SG_ ICC_LISD_Pixel199_OnOff : 206|1@0+ (1,0) [0|1] "" Vector__XXX
 SG_ ICC_LISD_Pixel200_OnOff : 207|1@0+ (1,0) [0|1] "" Vector__XXX
 SG_ ICC_LISD_Pixel201_OnOff : 208|1@0+ (1,0) [0|1] "" Vector__XXX
 SG_ ICC_LISD_Pixel202_OnOff : 209|1@0+ (1,0) [0|1] "" Vector__XXX
 SG_ ICC_LISD_Pixel203_OnOff : 210|1@0+ (1,0) [0|1] "" Vector__XXX
 SG_ ICC_LISD_Pixel204_OnOff : 211|1@0+ (1,0) [0|1] "" Vector__XXX
 SG_ ICC_LISD_Pixel205_OnOff : 212|1@0+ (1,0) [0|1] "" Vector__XXX
 SG_ ICC_LISD_Pixel206_OnOff : 213|1@0+ (1,0) [0|1] "" Vector__XXX
 SG_ ICC_LISD_Pixel207_OnOff : 214|1@0+ (1,0) [0|1] "" Vector__XXX
 SG_ ICC_LISD_Pixel208_OnOff : 215|1@0+ (1,0) [0|1] "" Vector__XXX
 SG_ ICC_LISD_Pixel209_OnOff : 216|1@0+ (1,0) [0|1] "" Vector__XXX
 SG_ ICC_LISD_Pixel210_OnOff : 217|1@0+ (1,0) [0|1] "" Vector__XXX
 SG_ ICC_LISD_Pixel211_OnOff : 218|1@0+ (1,0) [0|1] "" Vector__XXX
 SG_ ICC_LISD_Pixel212_OnOff : 219|1@0+ (1,0) [0|1] "" Vector__XXX
 SG_ ICC_LISD_Pixel213_OnOff : 220|1@0+ (1,0) [0|1] "" Vector__XXX
 SG_ ICC_LISD_Pixel214_OnOff : 221|1@0+ (1,0) [0|1] "" Vector__XXX
 SG_ ICC_LISD_Pixel215_OnOff : 222|1@0+ (1,0) [0|1] "" Vector__XXX
 SG_ ICC_LISD_Pixel216_OnOff : 223|1@0+ (1,0) [0|1] "" Vector__XXX
 SG_ ICC_LISD_Pixel217_OnOff : 224|1@0+ (1,0) [0|1] "" Vector__XXX
 SG_ ICC_LISD_Pixel218_OnOff : 225|1@0+ (1,0) [0|1] "" Vector__XXX
 SG_ ICC_LISD_Pixel219_OnOff : 226|1@0+ (1,0) [0|1] "" Vector__XXX
 SG_ ICC_LISD_Pixel220_OnOff : 227|1@0+ (1,0) [0|1] "" Vector__XXX
 SG_ ICC_LISD_Pixel221_OnOff : 228|1@0+ (1,0) [0|1] "" Vector__XXX
 SG_ ICC_LISD_Pixel222_OnOff : 229|1@0+ (1,0) [0|1] "" Vector__XXX
 SG_ ICC_LISD_Pixel223_OnOff : 230|1@0+ (1,0) [0|1] "" Vector__XXX
 SG_ ICC_LISD_Pixel224_OnOff : 231|1@0+ (1,0) [0|1] "" Vector__XXX
 SG_ ICC_LISD_Pixel225_OnOff : 232|1@0+ (1,0) [0|1] "" Vector__XXX
 SG_ ICC_LISD_Pixel226_OnOff : 233|1@0+ (1,0) [0|1] "" Vector__XXX
 SG_ ICC_LISD_Pixel227_OnOff : 234|1@0+ (1,0) [0|1] "" Vector__XXX
 SG_ ICC_LISD_Pixel228_OnOff : 235|1@0+ (1,0) [0|1] "" Vector__XXX
 SG_ ICC_LISD_Pixel229_OnOff : 236|1@0+ (1,0) [0|1] "" Vector__XXX
 SG_ ICC_LISD_Pixel230_OnOff : 237|1@0+ (1,0) [0|1] "" Vector__XXX
 SG_ ICC_LISD_Pixel231_OnOff : 238|1@0+ (1,0) [0|1] "" Vector__XXX
 SG_ ICC_LISD_Pixel232_OnOff : 239|1@0+ (1,0) [0|1] "" Vector__XXX
 SG_ ICC_LISD_Pixel233_OnOff : 240|1@0+ (1,0) [0|1] "" Vector__XXX
 SG_ ICC_LISD_Pixel234_OnOff : 241|1@0+ (1,0) [0|1] "" Vector__XXX
 SG_ ICC_LISD_Pixel235_OnOff : 242|1@0+ (1,0) [0|1] "" Vector__XXX
 SG_ ICC_LISD_Pixel236_OnOff : 243|1@0+ (1,0) [0|1] "" Vector__XXX
 SG_ ICC_LISD_Pixel237_OnOff : 244|1@0+ (1,0) [0|1] "" Vector__XXX
 SG_ ICC_LISD_Pixel238_OnOff : 245|1@0+ (1,0) [0|1] "" Vector__XXX
 SG_ ICC_LISD_Pixel239_OnOff : 246|1@0+ (1,0) [0|1] "" Vector__XXX
 SG_ ICC_LISD_Pixel240_OnOff : 247|1@0+ (1,0) [0|1] "" Vector__XXX
 SG_ ICC_LISD_Pixel241_OnOff : 248|1@0+ (1,0) [0|1] "" Vector__XXX
 SG_ ICC_LISD_Pixel242_OnOff : 249|1@0+ (1,0) [0|1] "" Vector__XXX
 SG_ ICC_LISD_Pixel243_OnOff : 250|1@0+ (1,0) [0|1] "" Vector__XXX
 SG_ ICC_LISD_Pixel244_OnOff : 251|1@0+ (1,0) [0|1] "" Vector__XXX
 SG_ ICC_LISD_Pixel245_OnOff : 252|1@0+ (1,0) [0|1] "" Vector__XXX
 SG_ ICC_LISD_Pixel246_OnOff : 253|1@0+ (1,0) [0|1] "" Vector__XXX
 SG_ ICC_LISD_Pixel247_OnOff : 254|1@0+ (1,0) [0|1] "" Vector__XXX
 SG_ ICC_LISD_Pixel248_OnOff : 255|1@0+ (1,0) [0|1] "" Vector__XXX
 SG_ ICC_LISD_Pixel249_OnOff : 256|1@0+ (1,0) [0|1] "" Vector__XXX
 SG_ ICC_LISD_Pixel250_OnOff : 257|1@0+ (1,0) [0|1] "" Vector__XXX
 SG_ ICC_LISD_Pixel251_OnOff : 258|1@0+ (1,0) [0|1] "" Vector__XXX
 SG_ ICC_LISD_Pixel252_OnOff : 259|1@0+ (1,0) [0|1] "" Vector__XXX
 SG_ ICC_LISD_Pixel253_OnOff : 260|1@0+ (1,0) [0|1] "" Vector__XXX
 SG_ ICC_LISD_Pixel254_OnOff : 261|1@0+ (1,0) [0|1] "" Vector__XXX
 SG_ ICC_LISD_Pixel255_OnOff : 262|1@0+ (1,0) [0|1] "" Vector__XXX
 SG_ ICC_LISD_Pixel256_OnOff : 263|1@0+ (1,0) [0|1] "" Vector__XXX
 SG_ ICC_LISD_Pixel257_OnOff : 264|1@0+ (1,0) [0|1] "" Vector__XXX
 SG_ ICC_LISD_Pixel258_OnOff : 265|1@0+ (1,0) [0|1] "" Vector__XXX
 SG_ ICC_LISD_Pixel259_OnOff : 266|1@0+ (1,0) [0|1] "" Vector__XXX
 SG_ ICC_LISD_Pixel260_OnOff : 267|1@0+ (1,0) [0|1] "" Vector__XXX
 SG_ ICC_LISD_Pixel261_OnOff : 268|1@0+ (1,0) [0|1] "" Vector__XXX
 SG_ ICC_LISD_Pixel262_OnOff : 269|1@0+ (1,0) [0|1] "" Vector__XXX
 SG_ ICC_LISD_Pixel263_OnOff : 270|1@0+ (1,0) [0|1] "" Vector__XXX
 SG_ ICC_LISD_Pixel264_OnOff : 271|1@0+ (1,0) [0|1] "" Vector__XXX
 SG_ ICC_LISD_Pixel265_OnOff : 272|1@0+ (1,0) [0|1] "" Vector__XXX
 SG_ ICC_LISD_Pixel266_OnOff : 273|1@0+ (1,0) [0|1] "" Vector__XXX
 SG_ ICC_LISD_Pixel267_OnOff : 274|1@0+ (1,0) [0|1] "" Vector__XXX
 SG_ ICC_LISD_Pixel268_OnOff : 275|1@0+ (1,0) [0|1] "" Vector__XXX
 SG_ ICC_LISD_Pixel269_OnOff : 276|1@0+ (1,0) [0|1] "" Vector__XXX
 SG_ ICC_LISD_Pixel270_OnOff : 277|1@0+ (1,0) [0|1] "" Vector__XXX
 SG_ ICC_LISD_Pixel271_OnOff : 278|1@0+ (1,0) [0|1] "" Vector__XXX
 SG_ ICC_LISD_Pixel272_OnOff : 279|1@0+ (1,0) [0|1] "" Vector__XXX
 SG_ ICC_LISD_Pixel273_OnOff : 280|1@0+ (1,0) [0|1] "" Vector__XXX
 SG_ ICC_LISD_Pixel274_OnOff : 281|1@0+ (1,0) [0|1] "" Vector__XXX
 SG_ ICC_LISD_Pixel275_OnOff : 282|1@0+ (1,0) [0|1] "" Vector__XXX
 SG_ ICC_LISD_Pixel276_OnOff : 283|1@0+ (1,0) [0|1] "" Vector__XXX
 SG_ ICC_LISD_Pixel277_OnOff : 284|1@0+ (1,0) [0|1] "" Vector__XXX
 SG_ ICC_LISD_Pixel278_OnOff : 285|1@0+ (1,0) [0|1] "" Vector__XXX
 SG_ ICC_LISD_Pixel279_OnOff : 286|1@0+ (1,0) [0|1] "" Vector__XXX
 SG_ ICC_LISD_Pixel280_OnOff : 287|1@0+ (1,0) [0|1] "" Vector__XXX
 SG_ ICC_LISD_Pixel281_OnOff : 288|1@0+ (1,0) [0|1] "" Vector__XXX
 SG_ ICC_LISD_Pixel282_OnOff : 289|1@0+ (1,0) [0|1] "" Vector__XXX
 SG_ ICC_LISD_Pixel283_OnOff : 290|1@0+ (1,0) [0|1] "" Vector__XXX
 SG_ ICC_LISD_Pixel284_OnOff : 291|1@0+ (1,0) [0|1] "" Vector__XXX
 SG_ ICC_LISD_Pixel285_OnOff : 292|1@0+ (1,0) [0|1] "" Vector__XXX
 SG_ ICC_LISD_Pixel286_OnOff : 293|1@0+ (1,0) [0|1] "" Vector__XXX
 SG_ ICC_LISD_Pixel287_OnOff : 294|1@0+ (1,0) [0|1] "" Vector__XXX
 SG_ ICC_LISD_Pixel288_OnOff : 295|1@0+ (1,0) [0|1] "" Vector__XXX
 SG_ ICC_LISD_Pixel289_OnOff : 296|1@0+ (1,0) [0|1] "" Vector__XXX
 SG_ ICC_LISD_Pixel290_OnOff : 297|1@0+ (1,0) [0|1] "" Vector__XXX
 SG_ ICC_LISD_Pixel291_OnOff : 298|1@0+ (1,0) [0|1] "" Vector__XXX
 SG_ ICC_LISD_Pixel292_OnOff : 299|1@0+ (1,0) [0|1] "" Vector__XXX
 SG_ ICC_LISD_Pixel293_OnOff : 300|1@0+ (1,0) [0|1] "" Vector__XXX
 SG_ ICC_LISD_Pixel294_OnOff : 301|1@0+ (1,0) [0|1] "" Vector__XXX
 SG_ ICC_LISD_Pixel295_OnOff : 302|1@0+ (1,0) [0|1] "" Vector__XXX
 SG_ ICC_LISD_Pixel296_OnOff : 303|1@0+ (1,0) [0|1] "" Vector__XXX
 SG_ ICC_LISD_Pixel297_OnOff : 304|1@0+ (1,0) [0|1] "" Vector__XXX
 SG_ ICC_LISD_Pixel298_OnOff : 305|1@0+ (1,0) [0|1] "" Vector__XXX
 SG_ ICC_LISD_Pixel299_OnOff : 306|1@0+ (1,0) [0|1] "" Vector__XXX
 SG_ ICC_LISD_Pixel300_OnOff : 307|1@0+ (1,0) [0|1] "" Vector__XXX
 SG_ ICC_LISD_Pixel301_OnOff : 308|1@0+ (1,0) [0|1] "" Vector__XXX
 SG_ ICC_LISD_Pixel302_OnOff : 309|1@0+ (1,0) [0|1] "" Vector__XXX
 SG_ ICC_LISD_Pixel303_OnOff : 310|1@0+ (1,0) [0|1] "" Vector__XXX
 SG_ ICC_LISD_Pixel304_OnOff : 311|1@0+ (1,0) [0|1] "" Vector__XXX
 SG_ ICC_LISD_Pixel305_OnOff : 312|1@0+ (1,0) [0|1] "" Vector__XXX
 SG_ ICC_LISD_Pixel306_OnOff : 313|1@0+ (1,0) [0|1] "" Vector__XXX
 SG_ ICC_LISD_Pixel307_OnOff : 314|1@0+ (1,0) [0|1] "" Vector__XXX
 SG_ ICC_LISD_Pixel308_OnOff : 315|1@0+ (1,0) [0|1] "" Vector__XXX
 SG_ ICC_LISD_Pixel309_OnOff : 316|1@0+ (1,0) [0|1] "" Vector__XXX
 SG_ ICC_LISD_Pixel310_OnOff : 317|1@0+ (1,0) [0|1] "" Vector__XXX
 SG_ ICC_LISD_Pixel311_OnOff : 318|1@0+ (1,0) [0|1] "" Vector__XXX
 SG_ ICC_LISD_Pixel312_OnOff : 319|1@0+ (1,0) [0|1] "" Vector__XXX
 SG_ ICC_LISD_Pixel313_OnOff : 320|1@0+ (1,0) [0|1] "" Vector__XXX
 SG_ ICC_LISD_Pixel314_OnOff : 321|1@0+ (1,0) [0|1] "" Vector__XXX
 SG_ ICC_LISD_Pixel315_OnOff : 322|1@0+ (1,0) [0|1] "" Vector__XXX
 SG_ ICC_LISD_Pixel316_OnOff : 323|1@0+ (1,0) [0|1] "" Vector__XXX
 SG_ ICC_LISD_Pixel317_OnOff : 324|1@0+ (1,0) [0|1] "" Vector__XXX
 SG_ ICC_LISD_Pixel318_OnOff : 325|1@0+ (1,0) [0|1] "" Vector__XXX
 SG_ ICC_LISD_Pixel319_OnOff : 326|1@0+ (1,0) [0|1] "" Vector__XXX
 SG_ ICC_LISD_Pixel320_OnOff : 327|1@0+ (1,0) [0|1] "" Vector__XXX
 SG_ ICC_LISD_Pixel321_OnOff : 328|1@0+ (1,0) [0|1] "" Vector__XXX
 SG_ ICC_LISD_Pixel322_OnOff : 329|1@0+ (1,0) [0|1] "" Vector__XXX
 SG_ ICC_LISD_Pixel323_OnOff : 330|1@0+ (1,0) [0|1] "" Vector__XXX
 SG_ ICC_LISD_Pixel324_OnOff : 331|1@0+ (1,0) [0|1] "" Vector__XXX
 SG_ ICC_LISD_Pixel325_OnOff : 332|1@0+ (1,0) [0|1] "" Vector__XXX
 SG_ ICC_LISD_Pixel326_OnOff : 333|1@0+ (1,0) [0|1] "" Vector__XXX
 SG_ ICC_LISD_Pixel327_OnOff : 334|1@0+ (1,0) [0|1] "" Vector__XXX
 SG_ ICC_LISD_Pixel328_OnOff : 335|1@0+ (1,0) [0|1] "" Vector__XXX
 SG_ ICC_LISD_Pixel329_OnOff : 336|1@0+ (1,0) [0|1] "" Vector__XXX
 SG_ ICC_LISD_Pixel330_OnOff : 337|1@0+ (1,0) [0|1] "" Vector__XXX
 SG_ ICC_LISD_Pixel331_OnOff : 338|1@0+ (1,0) [0|1] "" Vector__XXX
 SG_ ICC_LISD_Pixel332_OnOff : 339|1@0+ (1,0) [0|1] "" Vector__XXX
 SG_ ICC_LISD_Pixel333_OnOff : 340|1@0+ (1,0) [0|1] "" Vector__XXX
 SG_ ICC_LISD_Pixel334_OnOff : 341|1@0+ (1,0) [0|1] "" Vector__XXX
 SG_ ICC_LISD_Pixel335_OnOff : 342|1@0+ (1,0) [0|1] "" Vector__XXX
 SG_ ICC_LISD_Pixel336_OnOff : 343|1@0+ (1,0) [0|1] "" Vector__XXX
 SG_ ICC_LISD_Pixel337_OnOff : 344|1@0+ (1,0) [0|1] "" Vector__XXX
 SG_ ICC_LISD_Pixel338_OnOff : 345|1@0+ (1,0) [0|1] "" Vector__XXX
 SG_ ICC_LISD_Pixel339_OnOff : 346|1@0+ (1,0) [0|1] "" Vector__XXX
 SG_ ICC_LISD_Pixel340_OnOff : 347|1@0+ (1,0) [0|1] "" Vector__XXX
 SG_ ICC_LISD_Pixel341_OnOff : 348|1@0+ (1,0) [0|1] "" Vector__XXX
 SG_ ICC_LISD_Pixel342_OnOff : 349|1@0+ (1,0) [0|1] "" Vector__XXX
 SG_ ICC_LISD_Pixel343_OnOff : 350|1@0+ (1,0) [0|1] "" Vector__XXX
 SG_ ICC_LISD_Pixel344_OnOff : 351|1@0+ (1,0) [0|1] "" Vector__XXX
 SG_ ICC_LISD_Pixel345_OnOff : 352|1@0+ (1,0) [0|1] "" Vector__XXX
 SG_ ICC_LISD_Pixel346_OnOff : 353|1@0+ (1,0) [0|1] "" Vector__XXX
 SG_ ICC_LISD_Pixel347_OnOff : 354|1@0+ (1,0) [0|1] "" Vector__XXX
 SG_ ICC_LISD_Pixel348_OnOff : 355|1@0+ (1,0) [0|1] "" Vector__XXX
 SG_ ICC_LISD_Pixel349_OnOff : 356|1@0+ (1,0) [0|1] "" Vector__XXX
 SG_ ICC_LISD_Pixel350_OnOff : 357|1@0+ (1,0) [0|1] "" Vector__XXX
 SG_ ICC_LISD_Pixel351_OnOff : 358|1@0+ (1,0) [0|1] "" Vector__XXX
 SG_ ICC_LISD_Pixel352_OnOff : 359|1@0+ (1,0) [0|1] "" Vector__XXX
 SG_ ICC_LISD_Pixel353_OnOff : 360|1@0+ (1,0) [0|1] "" Vector__XXX
 SG_ ICC_LISD_Pixel354_OnOff : 361|1@0+ (1,0) [0|1] "" Vector__XXX
 SG_ ICC_LISD_Pixel355_OnOff : 362|1@0+ (1,0) [0|1] "" Vector__XXX
 SG_ ICC_LISD_Pixel356_OnOff : 363|1@0+ (1,0) [0|1] "" Vector__XXX
 SG_ ICC_LISD_Pixel357_OnOff : 364|1@0+ (1,0) [0|1] "" Vector__XXX
 SG_ ICC_LISD_Pixel358_OnOff : 365|1@0+ (1,0) [0|1] "" Vector__XXX
 SG_ ICC_LISD_Pixel359_OnOff : 366|1@0+ (1,0) [0|1] "" Vector__XXX
 SG_ ICC_LISD_Pixel360_OnOff : 367|1@0+ (1,0) [0|1] "" Vector__XXX
 SG_ ICC_LISD_Pixel361_OnOff : 368|1@0+ (1,0) [0|1] "" Vector__XXX
 SG_ ICC_LISD_Pixel362_OnOff : 369|1@0+ (1,0) [0|1] "" Vector__XXX
 SG_ ICC_LISD_Pixel363_OnOff : 370|1@0+ (1,0) [0|1] "" Vector__XXX
 SG_ ICC_LISD_Pixel364_OnOff : 371|1@0+ (1,0) [0|1] "" Vector__XXX
 SG_ ICC_LISD_Pixel365_OnOff : 372|1@0+ (1,0) [0|1] "" Vector__XXX
 SG_ ICC_LISD_Pixel366_OnOff : 373|1@0+ (1,0) [0|1] "" Vector__XXX
 SG_ ICC_LISD_Pixel367_OnOff : 374|1@0+ (1,0) [0|1] "" Vector__XXX
 SG_ ICC_LISD_Pixel368_OnOff : 375|1@0+ (1,0) [0|1] "" Vector__XXX
 SG_ ICC_LISD_Pixel369_OnOff : 376|1@0+ (1,0) [0|1] "" Vector__XXX
 SG_ ICC_LISD_Pixel370_OnOff : 377|1@0+ (1,0) [0|1] "" Vector__XXX
 SG_ ICC_LISD_Pixel371_OnOff : 378|1@0+ (1,0) [0|1] "" Vector__XXX
 SG_ ICC_LISD_Pixel372_OnOff : 379|1@0+ (1,0) [0|1] "" Vector__XXX
 SG_ ICC_LISD_Pixel373_OnOff : 380|1@0+ (1,0) [0|1] "" Vector__XXX
 SG_ ICC_LISD_Pixel374_OnOff : 381|1@0+ (1,0) [0|1] "" Vector__XXX
 SG_ ICC_LISD_Pixel375_OnOff : 382|1@0+ (1,0) [0|1] "" Vector__XXX
 SG_ ICC_LISD_Pixel376_OnOff : 383|1@0+ (1,0) [0|1] "" Vector__XXX
 SG_ ICC_LISD_Pixel377_OnOff : 384|1@0+ (1,0) [0|1] "" Vector__XXX
 SG_ ICC_LISD_Pixel378_OnOff : 385|1@0+ (1,0) [0|1] "" Vector__XXX
 SG_ ICC_LISD_Pixel379_OnOff : 386|1@0+ (1,0) [0|1] "" Vector__XXX
 SG_ ICC_LISD_Pixel380_OnOff : 387|1@0+ (1,0) [0|1] "" Vector__XXX
 SG_ ICC_LISD_Pixel381_OnOff : 388|1@0+ (1,0) [0|1] "" Vector__XXX
 SG_ ICC_LISD_Pixel382_OnOff : 389|1@0+ (1,0) [0|1] "" Vector__XXX
 SG_ ICC_LISD_Pixel383_OnOff : 390|1@0+ (1,0) [0|1] "" Vector__XXX
 SG_ ICC_LISD_Pixel384_OnOff : 391|1@0+ (1,0) [0|1] "" Vector__XXX
 SG_ ICC_LISD_Pixel385_OnOff : 392|1@0+ (1,0) [0|1] "" Vector__XXX
 SG_ ICC_LISD_Pixel386_OnOff : 393|1@0+ (1,0) [0|1] "" Vector__XXX
 SG_ ICC_LISD_Pixel387_OnOff : 394|1@0+ (1,0) [0|1] "" Vector__XXX
 SG_ ICC_LISD_Pixel388_OnOff : 395|1@0+ (1,0) [0|1] "" Vector__XXX
 SG_ ICC_LISD_Pixel389_OnOff : 396|1@0+ (1,0) [0|1] "" Vector__XXX
 SG_ ICC_LISD_Pixel390_OnOff : 397|1@0+ (1,0) [0|1] "" Vector__XXX
 SG_ ICC_LISD_Pixel391_OnOff : 398|1@0+ (1,0) [0|1] "" Vector__XXX
 SG_ ICC_LISD_Pixel392_OnOff : 399|1@0+ (1,0) [0|1] "" Vector__XXX
 SG_ ICC_LISD_Pixel393_OnOff : 400|1@0+ (1,0) [0|1] "" Vector__XXX
 SG_ ICC_LISD_Pixel394_OnOff : 401|1@0+ (1,0) [0|1] "" Vector__XXX
 SG_ ICC_LISD_Pixel395_OnOff : 402|1@0+ (1,0) [0|1] "" Vector__XXX
 SG_ ICC_LISD_Pixel396_OnOff : 403|1@0+ (1,0) [0|1] "" Vector__XXX
 SG_ ICC_LISD_Pixel397_OnOff : 404|1@0+ (1,0) [0|1] "" Vector__XXX
 SG_ ICC_LISD_Pixel398_OnOff : 405|1@0+ (1,0) [0|1] "" Vector__XXX
 SG_ ICC_LISD_Pixel399_OnOff : 406|1@0+ (1,0) [0|1] "" Vector__XXX
 SG_ ICC_LISD_Pixel400_OnOff : 407|1@0+ (1,0) [0|1] "" Vector__XXX
 SG_ ICC_LISD_Pixel401_OnOff : 408|1@0+ (1,0) [0|1] "" Vector__XXX
 SG_ ICC_LISD_Pixel402_OnOff : 409|1@0+ (1,0) [0|1] "" Vector__XXX
 SG_ ICC_LISD_Pixel403_OnOff : 410|1@0+ (1,0) [0|1] "" Vector__XXX
 SG_ ICC_LISD_Pixel404_OnOff : 411|1@0+ (1,0) [0|1] "" Vector__XXX
 SG_ ICC_LISD_Pixel405_OnOff : 412|1@0+ (1,0) [0|1] "" Vector__XXX
 SG_ ICC_LISD_Pixel406_OnOff : 413|1@0+ (1,0) [0|1] "" Vector__XXX
 SG_ ICC_LISD_Pixel407_OnOff : 414|1@0+ (1,0) [0|1] "" Vector__XXX
 SG_ ICC_LISD_Pixel408_OnOff : 415|1@0+ (1,0) [0|1] "" Vector__XXX
 SG_ ICC_LISD_Pixel409_OnOff : 416|1@0+ (1,0) [0|1] "" Vector__XXX
 SG_ ICC_LISD_Pixel410_OnOff : 417|1@0+ (1,0) [0|1] "" Vector__XXX
 SG_ ICC_LISD_Pixel411_OnOff : 418|1@0+ (1,0) [0|1] "" Vector__XXX
 SG_ ICC_LISD_Pixel412_OnOff : 419|1@0+ (1,0) [0|1] "" Vector__XXX
 SG_ ICC_LISD_Pixel413_OnOff : 420|1@0+ (1,0) [0|1] "" Vector__XXX
 SG_ ICC_LISD_Pixel414_OnOff : 421|1@0+ (1,0) [0|1] "" Vector__XXX
 SG_ ICC_LISD_Pixel415_OnOff : 422|1@0+ (1,0) [0|1] "" Vector__XXX
 SG_ ICC_LISD_Pixel416_OnOff : 423|1@0+ (1,0) [0|1] "" Vector__XXX
 SG_ ICC_LISD_Pixel417_OnOff : 424|1@0+ (1,0) [0|1] "" Vector__XXX
 SG_ ICC_LISD_Pixel418_OnOff : 425|1@0+ (1,0) [0|1] "" Vector__XXX
 SG_ ICC_LISD_Pixel419_OnOff : 426|1@0+ (1,0) [0|1] "" Vector__XXX
 SG_ ICC_LISD_Pixel420_OnOff : 427|1@0+ (1,0) [0|1] "" Vector__XXX
 SG_ ICC_LISD_Pixel421_OnOff : 428|1@0+ (1,0) [0|1] "" Vector__XXX
 SG_ ICC_LISD_Pixel422_OnOff : 429|1@0+ (1,0) [0|1] "" Vector__XXX
 SG_ ICC_LISD_Pixel423_OnOff : 430|1@0+ (1,0) [0|1] "" Vector__XXX
 SG_ ICC_LISD_Pixel424_OnOff : 431|1@0+ (1,0) [0|1] "" Vector__XXX
 SG_ ICC_LISD_Pixel425_OnOff : 432|1@0+ (1,0) [0|1] "" Vector__XXX
 SG_ ICC_LISD_Pixel426_OnOff : 433|1@0+ (1,0) [0|1] "" Vector__XXX
 SG_ ICC_LISD_Pixel427_OnOff : 434|1@0+ (1,0) [0|1] "" Vector__XXX
 SG_ ICC_LISD_Pixel428_OnOff : 435|1@0+ (1,0) [0|1] "" Vector__XXX
 SG_ ICC_LISD_Pixel429_OnOff : 436|1@0+ (1,0) [0|1] "" Vector__XXX
 SG_ ICC_LISD_Pixel430_OnOff : 437|1@0+ (1,0) [0|1] "" Vector__XXX
 SG_ ICC_LISD_Pixel431_OnOff : 438|1@0+ (1,0) [0|1] "" Vector__XXX
 SG_ ICC_LISD_Pixel432_OnOff : 439|1@0+ (1,0) [0|1] "" Vector__XXX
 SG_ ICC_LISD_Pixel433_OnOff : 440|1@0+ (1,0) [0|1] "" Vector__XXX
 SG_ ICC_LISD_Pixel434_OnOff : 441|1@0+ (1,0) [0|1] "" Vector__XXX
 SG_ ICC_LISD_Pixel435_OnOff : 442|1@0+ (1,0) [0|1] "" Vector__XXX
 SG_ ICC_LISD_Pixel436_OnOff : 443|1@0+ (1,0) [0|1] "" Vector__XXX
 SG_ ICC_LISD_Pixel437_OnOff : 444|1@0+ (1,0) [0|1] "" Vector__XXX
 SG_ ICC_LISD_Pixel438_OnOff : 445|1@0+ (1,0) [0|1] "" Vector__XXX
 SG_ ICC_LISD_Pixel439_OnOff : 446|1@0+ (1,0) [0|1] "" Vector__XXX
 SG_ ICC_LISD_Pixel440_OnOff : 447|1@0+ (1,0) [0|1] "" Vector__XXX
 SG_ ICC_LISD_Pixel441_OnOff : 448|1@0+ (1,0) [0|1] "" Vector__XXX
 SG_ ICC_LISD_Pixel442_OnOff : 449|1@0+ (1,0) [0|1] "" Vector__XXX
 SG_ ICC_LISD_Pixel443_OnOff : 450|1@0+ (1,0) [0|1] "" Vector__XXX
 SG_ ICC_LISD_Pixel444_OnOff : 451|1@0+ (1,0) [0|1] "" Vector__XXX
 SG_ ICC_LISD_Pixel445_OnOff : 452|1@0+ (1,0) [0|1] "" Vector__XXX
 SG_ ICC_LISD_Pixel446_OnOff : 453|1@0+ (1,0) [0|1] "" Vector__XXX
 SG_ ICC_LISD_Pixel447_OnOff : 454|1@0+ (1,0) [0|1] "" Vector__XXX
 SG_ ICC_LISD_Pixel448_OnOff : 455|1@0+ (1,0) [0|1] "" Vector__XXX
 SG_ ICC_LISD_Pixel449_OnOff : 456|1@0+ (1,0) [0|1] "" Vector__XXX
 SG_ ICC_LISD_Pixel450_OnOff : 457|1@0+ (1,0) [0|1] "" Vector__XXX
 SG_ ICC_LISD_Pixel451_OnOff : 458|1@0+ (1,0) [0|1] "" Vector__XXX
 SG_ ICC_LISD_Pixel452_OnOff : 459|1@0+ (1,0) [0|1] "" Vector__XXX
 SG_ ICC_LISD_Pixel453_OnOff : 460|1@0+ (1,0) [0|1] "" Vector__XXX
 SG_ ICC_LISD_Pixel454_OnOff : 461|1@0+ (1,0) [0|1] "" Vector__XXX
 SG_ ICC_LISD_Pixel455_OnOff : 462|1@0+ (1,0) [0|1] "" Vector__XXX
 SG_ ICC_LISD_Pixel456_OnOff : 463|1@0+ (1,0) [0|1] "" Vector__XXX
 SG_ ICC_LISD_Pixel457_OnOff : 464|1@0+ (1,0) [0|1] "" Vector__XXX
 SG_ ICC_LISD_Pixel458_OnOff : 465|1@0+ (1,0) [0|1] "" Vector__XXX
 SG_ ICC_LISD_Pixel459_OnOff : 466|1@0+ (1,0) [0|1] "" Vector__XXX
 SG_ ICC_LISD_Pixel460_OnOff : 467|1@0+ (1,0) [0|1] "" Vector__XXX
 SG_ ICC_LISD_Pixel461_OnOff : 468|1@0+ (1,0) [0|1] "" Vector__XXX
 SG_ ICC_LISD_Pixel462_OnOff : 469|1@0+ (1,0) [0|1] "" Vector__XXX
 SG_ ICC_LISD_Pixel463_OnOff : 470|1@0+ (1,0) [0|1] "" Vector__XXX
 SG_ ICC_LISD_Pixel464_OnOff : 471|1@0+ (1,0) [0|1] "" Vector__XXX
 SG_ ICC_LISD_Pixel465_OnOff : 472|1@0+ (1,0) [0|1] "" Vector__XXX
 SG_ ICC_LISD_Pixel466_OnOff : 473|1@0+ (1,0) [0|1] "" Vector__XXX
 SG_ ICC_LISD_Pixel467_OnOff : 474|1@0+ (1,0) [0|1] "" Vector__XXX
 SG_ ICC_LISD_Pixel468_OnOff : 475|1@0+ (1,0) [0|1] "" Vector__XXX
 SG_ ICC_LISD_Pixel469_OnOff : 476|1@0+ (1,0) [0|1] "" Vector__XXX
 SG_ ICC_LISD_Pixel470_OnOff : 477|1@0+ (1,0) [0|1] "" Vector__XXX
 SG_ ICC_LISD_Pixel471_OnOff : 478|1@0+ (1,0) [0|1] "" Vector__XXX
 SG_ ICC_LISD_Pixel472_OnOff : 479|1@0+ (1,0) [0|1] "" Vector__XXX
 SG_ ICC_LISD_Pixel473_OnOff : 480|1@0+ (1,0) [0|1] "" Vector__XXX
 SG_ ICC_LISD_Pixel474_OnOff : 481|1@0+ (1,0) [0|1] "" Vector__XXX
 SG_ ICC_LISD_Pixel475_OnOff : 482|1@0+ (1,0) [0|1] "" Vector__XXX
 SG_ ICC_LISD_Pixel476_OnOff : 483|1@0+ (1,0) [0|1] "" Vector__XXX
 SG_ ICC_LISD_Pixel477_OnOff : 484|1@0+ (1,0) [0|1] "" Vector__XXX
 SG_ ICC_LISD_Pixel478_OnOff : 485|1@0+ (1,0) [0|1] "" Vector__XXX
 SG_ ICC_LISD_Pixel479_OnOff : 486|1@0+ (1,0) [0|1] "" Vector__XXX
 SG_ ICC_LISD_Pixel480_OnOff : 487|1@0+ (1,0) [0|1] "" Vector__XXX
 SG_ ICC_LISD_Pixel481_OnOff : 488|1@0+ (1,0) [0|1] "" Vector__XXX
 SG_ ICC_LISD_Pixel482_OnOff : 489|1@0+ (1,0) [0|1] "" Vector__XXX
 SG_ ICC_LISD_Pixel483_OnOff : 490|1@0+ (1,0) [0|1] "" Vector__XXX
 SG_ ICC_LISD_Pixel484_OnOff : 491|1@0+ (1,0) [0|1] "" Vector__XXX
 SG_ ICC_LISD_Pixel485_OnOff : 492|1@0+ (1,0) [0|1] "" Vector__XXX
 SG_ ICC_LISD_Pixel486_OnOff : 493|1@0+ (1,0) [0|1] "" Vector__XXX
 SG_ ICC_LISD_Pixel487_OnOff : 494|1@0+ (1,0) [0|1] "" Vector__XXX
 SG_ ICC_LISD_Pixel488_OnOff : 495|1@0+ (1,0) [0|1] "" Vector__XXX
 SG_ ICC_LISD_Pixel489_OnOff : 496|1@0+ (1,0) [0|1] "" Vector__XXX
 SG_ ICC_LISD_Pixel490_OnOff : 497|1@0+ (1,0) [0|1] "" Vector__XXX
 SG_ ICC_LISD_Pixel491_OnOff : 498|1@0+ (1,0) [0|1] "" Vector__XXX
 SG_ ICC_LISD_Pixel492_OnOff : 499|1@0+ (1,0) [0|1] "" Vector__XXX
 SG_ ICC_LISD_Pixel493_OnOff : 500|1@0+ (1,0) [0|1] "" Vector__XXX
 SG_ ICC_LISD_Pixel494_OnOff : 501|1@0+ (1,0) [0|1] "" Vector__XXX
 SG_ ICC_LISD_Pixel495_OnOff : 502|1@0+ (1,0) [0|1] "" Vector__XXX
 SG_ ICC_LISD_Pixel496_OnOff : 503|1@0+ (1,0) [0|1] "" Vector__XXX
 SG_ ICC_LISD_Pixel497_OnOff : 504|1@0+ (1,0) [0|1] "" Vector__XXX
 SG_ ICC_LISD_Pixel498_OnOff : 505|1@0+ (1,0) [0|1] "" Vector__XXX
 SG_ ICC_LISD_Pixel499_OnOff : 506|1@0+ (1,0) [0|1] "" Vector__XXX
 SG_ ICC_LISD_Pixel500_OnOff : 507|1@0+ (1,0) [0|1] "" Vector__XXX
 SG_ ICC_LISD_Pixel501_OnOff : 508|1@0+ (1,0) [0|1] "" Vector__XXX
 SG_ ICC_LISD_Pixel502_OnOff : 509|1@0+ (1,0) [0|1] "" Vector__XXX
 SG_ ICC_LISD_Pixel503_OnOff : 510|1@0+ (1,0) [0|1] "" Vector__XXX
 SG_ ICC_LISD_Pixel504_OnOff : 511|1@0+ (1,0) [0|1] "" Vector__XXX

CM_ SG_ 1238 ICC_CFSSwitch "香氛系统开关设置";
CM_ SG_ 1238 ICC_CFSLevelSet "中控屏香氛浓度
0x0:Not_Active
0x1:Level1 淡香
0x2:Level2 清香
0x3:Level3 浓香
0x4~0x7:Reserve";
CM_ SG_ 1238 ICC_CFSPosSet "中控屏香氛类型（位置）";
CM_ SG_ 1238 ICC_PM25Switch "中控屏空气净化开关";
CM_ SG_ 1238 ICC_AQSSwitch "中控屏AQS开关";
CM_ SG_ 1238 ICC_SecSetTemp_C "二排空调温度";
CM_ SG_ 1238 ICC_SecFaceKeySts "Face Key Status
二排吹面按键开关";
CM_ SG_ 1238 ICC_SecFootKeySts "Foot Key Status
二排吹脚按键开关";
CM_ SG_ 1238 ICC_SecBlowSpeedLevelKeySts "Foot Key Status
二排吹脚按键开关";
CM_ SG_ 1238 ICC_SecAutoSwitch "二排空调AUTO开关";
CM_ SG_ 1238 ICC_SecCLMSwitch "二排空调开关";
CM_ SG_ 1238 ICC_ThrSetTemp_C "三排空调温度";
CM_ SG_ 1238 ICC_ThrFaceKeySts "Face Key Status
三排吹面按键开关";
CM_ SG_ 1238 ICC_ThrFootKeySts "Foot Key Status
三排吹脚按键开关";
CM_ SG_ 1238 ICC_ThrBlowSpeedLevelKeySts "Foot Key Status
三排吹脚按键开关";
CM_ SG_ 1238 ICC_ThrAutoSwitch "三排空调AUTO开关";
CM_ SG_ 1238 ICC_ThrCLMSwitch "三排空调开关";
CM_ SG_ 1238 ICC_ThrACRequestKeySts "Set AC Request Status
三排DVD设置AC请求开启";
CM_ SG_ 1238 ICC_DFMSwitch "单席功能开关";
CM_ SG_ 1289 ICC_TirePressureDisplayUnit "胎压显示单位";
CM_ SG_ 1289 ICC_TireTemperatureDisplayUnit "胎温显示单位";
CM_ SG_ 1289 ICC_ToggleUnits "英制单位切换";
CM_ SG_ 1289 ICC_BtConFlag "蓝牙连接状态反馈";
CM_ SG_ 1289 ICC_GPSSwitchSet "GPS定位开关设置";
CM_ SG_ 1167 ICC_KeyDriveModememory "驾驶模式记忆开关";
CM_ SG_ 1167 ICC_DriveModeSet "大屏越野模式设置
0x1：经济
0x2：标准
0x3：运动
0x4：雪/草地
0x5: 泥地
0x6: 越野
0x7: 沙地
0x8: 岩石
0x9: 专家
0xA: 智能
0xB: 涉水
0xC: 极限掉头
0xD: 漂移
0xE: 拖挂
0xF: 越野竞速";
CM_ SG_ 1167 ICC_DRIFTModeSetReq "通过大屏设置漂移模式灵敏度
0x0：不动作
0x1：入门
0x2：大师
0x3：专家";
CM_ SG_ 1167 ICC_EXPERTEIPBESPSet "关闭牵引力控制系统&车身稳定控制系统（TCS&VDC OFF）
全开（TCS、VDC等与ESP有关功能全部开启）
全关（TCS、VDC及RMI放侧翻、DTC发动机拖滞力矩管理）";
CM_ SG_ 1167 ICC_EXPERTEcoSet "专家模式动力设置柔和模式开关";
CM_ SG_ 1167 ICC_EXPERTNormSet "专家模式动力设置标准模式开关";
CM_ SG_ 1167 ICC_EXPERTSportSet "专家模式动力设置激进模式开关";
CM_ SG_ 1167 ICC_CrossaxisSet "专家模式交叉轴模式设置";
CM_ SG_ 1167 ICC_EXPERTRWDSet "专家模式驱动形式后驱设置";
CM_ SG_ 1167 ICC_EXPERTAWDSet "专家模式驱动形式四驱设置";
CM_ SG_ 1167 ICC_EXPERTAutoSet "专家模式驱动形式Auto设置";
CM_ SG_ 1167 ICC_CLIMBSet "防溜设置开关";
CM_ SG_ 1167 ICC_DriveModeExitSet "越野模式退出开关";
CM_ SG_ 1167 ICC_CCOSwtReq "ICC越野蠕行（CCO）软开关
0x0:Not Active 使能位
0x1:ON 开启
0x2:OFF 关闭";
CM_ SG_ 1167 ICC_TABSwtReq "ICC坦克转向（TAB）软开关
0x0:Not Active 使能位
0x1:ON 开启
0x2:OFF 关闭";
CM_ SG_ 1167 ICC_Confidencelevel "x模式的前端地形感知置信度（可靠度）";
CM_ SG_ 1167 ICC_V2L_IntlDisChg "放电记忆开关";
CM_ SG_ 1167 ICC_ExhibitionModeSwitch "展车模式开关";
CM_ SG_ 1167 ICC_TrailerMode "被拖模式开关";
CM_ SG_ 1167 ICC_V2L_DisChgMem "放电记忆开关";
CM_ SG_ 1167 ICC_DrivePowerDispSet "驱动系统功率显示方式开关";
CM_ SG_ 1167 ICC_WLTC_to_CLTC_Mode "驱动系统功率显示方式开关";
CM_ SG_ 1167 ICC_StopChrgnSwitch "驻车发电开关";
CM_ SG_ 1167 ICC_StopChrgnMode "驻车发电模式开关
0x1:静谧补电
0x2:快速补电";
CM_ SG_ 1167 ICC_RegenerateLevelCtrl "能量回馈设置开关
0x0:无效值
0x1:弱
0x2:强
0x3:中
0x4:单踏板";
CM_ SG_ 1167 ICC_SinglePedalMem "单踏板记忆开关";
CM_ SG_ 1167 ICC_FuelDetnSwt "燃油检测开关";
CM_ SG_ 1167 ICC_FuelDetnState "燃油检测模式状态";
CM_ SG_ 1167 ICC_FuelDetnOpDefeated "燃油检测开启失败提示";
CM_ SG_ 1167 ICC_HVDownRepairMode "断高压维修模式开关";
CM_ SG_ 1167 ICC_UTURNSnowSet "极限调头雪地场景开关";
CM_ SG_ 1167 ICC_UTURNSandSet "极限调头泥地场景开关";
CM_ SG_ 1167 ICC_UTURNMudSet "极限调头沙地场景开关";
CM_ SG_ 1167 ICC_UTURNGrassSet "极限调头草地场景开关";
CM_ SG_ 1167 ICC_RestoreDefaults_48Fh "系统恢复默认值（预留）";
CM_ SG_ 1167 ICC_LTCDispSet2 "续航里程选择开关显示";
CM_ SG_ 1326 ICC_DWDOnOff_Req "涉水雷达开关设置";
CM_ SG_ 1326 ICC_ContainerLightSet "货箱灯开关(D01P）";
CM_ SG_ 1331 ICC_RLSeatEasyEntryExitSet "二排左侧便捷进入\离车";
CM_ SG_ 1331 ICC_RRSeatEasyEntryExitSet "二排右侧便捷进入\离车";
CM_ SG_ 1331 ICC_RLMemoryRecoveryCmd "ICC二排左侧记忆保存/恢复指令";
CM_ SG_ 1331 ICC_RRMemoryRecoveryCmd "ICC二排右侧记忆保存/恢复指令";
CM_ SG_ 1331 ICC_RLSitPosnlocation "二排左侧座椅记忆设置";
CM_ SG_ 1331 ICC_RRSitPosnlocation "二排右侧座椅记忆设置";
CM_ SG_ 1331 ICC_CMSMDisplaySwitch "吸顶屏开关";
CM_ SG_ 1331 ICC_CMSMDisplayAdjustmode "吸顶屏模式调节
0x1:正常角度
0x2:观影角度";
CM_ SG_ 1331 ICC_CMSMSetstandardSwitch "吸顶屏标定开关0x1:标定打开 0x2:标定关闭";
CM_ SG_ 1331 ICC_LeftPedalControl "左边电踏请求（左边电踏软开关展开缩回请求）";
CM_ SG_ 1331 ICC_RightPedalControl "右边电踏请求（右边电踏软开关展开缩回请求）";
CM_ SG_ 1331 ICC_EPCEnable "电踏电动功能模式
0：无效值；
1：电动踏板启用（软开关启用）
2：电动踏板禁用（软开关禁用）";
CM_ SG_ 1331 ICC_AMPKTVvoiceVolumeSet "Amplifier KTV voice volume status
KTV人声音量设定";
CM_ SG_ 1331 ICC_AMPA2BENCSoundReq "Head unit ENC sound request to amplifier
ENC音源需求状态";
CM_ SG_ 1331 ICC_AMPENCVolumeSet "Amplifier ENC volume status
ENC声音量设定";
CM_ SG_ 1331 ICC_AMPA2BChimeSoundReq "Head unit Chime sound request to amplifier
Chime音源需求状态";
CM_ SG_ 1331 Set_AMPSoundFocus_2 "Amplifier sound focus status";
CM_ SG_ 1331 ICC_AMPA2BKTVvoiceSoundReq "Head unit KTV voice/IESS sound request to amplifier
KTV人声/模拟声浪音源需求状态";
CM_ SG_ 1331 ICC_MedStatusSet "冥想模式开关";
CM_ SG_ 1331 Set_AMPLoudness "Amplifier Loudness setting / 响度设定";
CM_ SG_ 1331 ICC_MedAreaSet "冥想模式开启区域设置";
CM_ SG_ 1331 ICC_LeftElectricPedalsSet "左电踏收回和展开软开关（前提自动打开）
0x1:踏板3D软开关开启
0x2:踏板3D软开关关闭";
CM_ SG_ 1331 ICC_RightElectricPedalsSet "右电踏收回和展开软开关（前提自动打开）
0x1:踏板3D软开关开启
0x2:踏板3D软开关关闭";
CM_ SG_ 1331 ICC_NapAreaSet2 "小憩模式开启区域设置2";
CM_ SG_ 1331 ICC_DisplayAdjustrAngReq "微信小程序遥控器控制吸顶屏角度90-110";
CM_ SG_ 1331 Set_AMPKeyVolume "Amplifier Keytone volume setting /设定按键音通道音量设定";
CM_ SG_ 1331 ICC_CMSMTouchSts "吸顶屏触摸信号0x1:有触摸 0x2:无触摸";
CM_ SG_ 1331 Set_AMPExSoundmode "Amplifier Exsound mode setting / 设定高级音效模式";
CM_ SG_ 1331 Set_AMPA2BENCSound "扬声器位置";
CM_ SG_ 1333 ICC_SRFCmd "天窗开关设置
全开
全关
翘起";
CM_ SG_ 1333 ICC_SRFPercentCmd "手滑动开启天窗百分比";
CM_ SG_ 1333 ICC_CSunshadeReq "天幕遮阳帘开关设置";
CM_ SG_ 1333 ICC_CSunshadePercentReq "手滑动开启天幕遮阳帘百分比";
CM_ SG_ 1333 ICC_SunshadeCmd "遮阳帘开关设置
全开
全关
一半";
CM_ SG_ 1333 ICC_SunshadePercentCmd "手滑动开启遮阳帘百分比";
CM_ SG_ 1333 CSunshadeLearnedReq_535h "遮阳帘学习请求";
CM_ SG_ 1333 CSunshadePercentReq_535h "遮阳帘开度";
CM_ SG_ 1335 ICC_SET_EPS_SteerReturnRmdSts "方向盘回正开关";
CM_ SG_ 1335 ICC_SET_MFSShake "方向盘震动开关";
CM_ SG_ 1335 ICC_DMS_1_DistractionLevel "方向盘震动等级调节";
CM_ SG_ 1335 ICC_SET_EPS_AsociWithDrvModSts "EPS与驾驶模式关联开关";
CM_ SG_ 1335 ICC_OverLoadWarnShieldSet "重量报警屏蔽软开关";
CM_ SG_ 1335 ICC_BSWReq "智能擦盘开启信号";
CM_ SG_ 1335 ICC_horizontalReq "露营找平软开关";
CM_ SG_ 1335 ICC_RolloverSetCmd "翻滚设置开关";
CM_ SG_ 1335 ICC_TrekThroughReq_537h "越野穿越开关";
CM_ SG_ 1335 ICC_InflateReq_537h "一键充气开关";
CM_ SG_ 1335 ICC_UndergroundModeReq_537h "地库模式开关";
CM_ SG_ 1337 ICC_SET_BT_ReduceWindSpeed "大屏设置蓝牙通话降低风速";
CM_ SG_ 1337 ICC_SET_IPM_FirstBlowing "夏日热风规避_大屏设置空调启动时第一口风";
CM_ SG_ 1337 ICC_SET_IPM_BlowerDelay "大屏设置车辆熄火空调鼓风机延时";
CM_ SG_ 1337 ICC_SET_CirculationInTunnels "大屏设置隧道内循环";
CM_ SG_ 1337 ICC_UVCLuminanceReq "大屏设置紫外线杀菌灯强度请求";
CM_ SG_ 1337 ICC_UVCControlReq "大屏设置紫外线杀菌灯";
CM_ SG_ 1337 ICC_CrossCountryCoolingReq "越野散热开关";
CM_ SG_ 1337 ICC_KeepWarmReq "恒温模式状态开关请求";
CM_ SG_ 1337 ICC_keepwarmSetTemperatureReq "恒温模式温度设置请求";
CM_ SG_ 1337 ICC_ParkingAirConditioning "驻车空调使能开关
ventilate通风";
CM_ SG_ 1337 ICC_CoolantFill_Req "冷却液加注开关请求";
CM_ SG_ 1337 ICC_FraganceLightoffReq "香氛氛围灯开关状态";
CM_ SG_ 1337 ICC_FraganceMemoffReq "香氛记忆开关状态";
CM_ SG_ 1337 ICC_CFSCycleLevel "香氛循环等级";
CM_ SG_ 1337 ICC_TimingLevel "香氛定时等级";
CM_ SG_ 1337 ICC_ModeAdjustDisplaySts "空调模式";
CM_ SG_ 1337 ICC_AirPurgeReminderReq "空气净化提醒开关请求";
CM_ SG_ 1337 ICC_BiochemicalFuncReq "大屏生化功能开关";
CM_ SG_ 1337 ICC_TimedVentilationReq "大屏定时换气功能开关";
CM_ SG_ 1337 ICC_PetmodeSetTemperature_L_C "宠物模式前左空调温度设置";
CM_ SG_ 1337 ICC_PetModeSetTemperature_R_C "宠物模式前右空调温度设置";
CM_ SG_ 1337 ICC_PetModeSetCLMOn "宠物模式空调开关设置";
CM_ SG_ 1337 ICC_PetModeSetAutoKeySts "宠物模式空调自动模式设置";
CM_ SG_ 1337 ICC_PetModeSetCirculationSts "宠物模式空调内外循环切换设置";
CM_ SG_ 1337 ICC_ISSFctCmd_539h "启停开关信号";
CM_ SG_ 1318 ICC_SET_TDL_Rhythm_Switch "氛围灯律动开关";
CM_ SG_ 1318 ICC_SET_TDL_Switch "氛围灯开关";
CM_ SG_ 1318 ICC_SET_TDL_ColourModeAdj "氛围灯颜色模式调节

Monochrome_单色
panchromatic为全色
FLZCU_TDL";
CM_ SG_ 1318 ICC_VoiceWake "语音唤醒";
CM_ SG_ 1318 ICC_TDLAssociatedDriverModeSw "氛围灯关联驾驶模式开关";
CM_ SG_ 1318 ICC_TDL_RhythmReq "音乐律动模式调节";
CM_ SG_ 1318 ICC_SET_ApiluminanceAdj "氛围灯亮度调节
氛围灯亮度_Level1最暗_Level8最亮FLZCU_TDL";
CM_ SG_ 1318 ICC_SET_MusicLoudness_120HZ "均衡器设置";
CM_ SG_ 1318 ICC_SET_MusicLoudness_250HZ "均衡器设置";
CM_ SG_ 1318 ICC_SET_MusicLoudness_500HZ "均衡器设置";
CM_ SG_ 1318 ICC_SET_MusicLoudness_1000HZ "均衡器设置";
CM_ SG_ 1318 ICC_SET_MusicLoudness_1500HZ "均衡器设置";
CM_ SG_ 1318 ICC_SET_MusicLoudness_2000HZ "均衡器设置";
CM_ SG_ 1318 ICC_SET_MusicLoudness_6000HZ "均衡器设置";
CM_ SG_ 1318 ICC_TDL_FlowLightSw "流水灯开关";
CM_ SG_ 1318 ICC_TDL_FlowLightModeAdj "流水灯模式调节";
CM_ SG_ 1318 ICC_SET_256ColourAdj "多元颜色设置（256色）";
CM_ SG_ 1320 ICC_Chb_Req "冰箱开关请求";
CM_ SG_ 1320 ICC_ChbMem_Req "记忆开关请求";
CM_ SG_ 1320 ICC_ChbDelay_Req "延时开关请求";
CM_ SG_ 1320 ICC_ChbSterilization_Req "杀菌开关请求";
CM_ SG_ 1320 ICC_ChbItemsLeft_Req "物品遗留开关请求";
CM_ SG_ 1320 ICC_ParkingRadarSwSet "驻车雷达开关请求";
CM_ SG_ 1320 ICC_ChbTimeset_Req "延时时间设置请求";
CM_ SG_ 1320 ICC_ChbCoolset_Req "制冷温度设置
0x1~0xD:-6℃~6℃（捷途使用）
0xE~0x19:-18℃~-7℃（股份使用，捷途预留）";
CM_ SG_ 1320 ICC_ChbCoolorheat_Req "制冷制热开关请求";
CM_ SG_ 1320 ICC_ChbHeatset_Req "制热温度调节设置请求";
CM_ SG_ 1360 ICC_LISD_DisplaySwitch "自定义图片实时显示功能开关";
CM_ SG_ 1360 ICC_LISD_ParkingShowCMD "驻车动画开关（反馈已有）";
CM_ SG_ 1360 ICC_RISD_DisplaySwitch "自定义图片实时显示功能开关";
CM_ SG_ 1360 ICC_RISD_ParkingShowCMD "驻车动画开关（反馈已有）";
CM_ SG_ 1360 ICC_LogoParkingReq "前LOGO驻车点亮开关请求";
CM_ SG_ 1360 ICC_LogoChargingReq "前LOGO充电灯效开关请求";
CM_ SG_ 1360 ICC_DRLSw "日间行车灯软开关";
CM_ SG_ 1360 ICC_LISD_ParkingShowMod "LISD驻车动画模式";
CM_ SG_ 1360 ICC_RISD_ParkingShowMod "RISD驻车动画模式";
CM_ SG_ 1360 ICC_PenetrationLampSetF "前贯穿灯软开关(D01P使用)";
CM_ SG_ 1360 ICC_MusicLampShowSW "0x0: 灯光秀总开关关闭
0x1: 灯光秀总开关开启";
CM_ SG_ 1360 ICC_LogoColorReq "Logo灯颜色设置，1-256分别对应256种颜色";
CM_ SG_ 1360 ICC_XDriveMode "ICC通过视频流发给VCU进行驾驶模式设置
0x0:Not Active
0x1:无法判断 unidentifiable
0x2:普通1 Normal
0x3:雪地1 SNOW
0x4:泥地1 MUD
0x5:岩石1 ROCK
0x6:沙地1 SAND
0x7:水面1 WATER SURFACE
0x8：普通2 Normal
0x9:雪地2 SNOW
0xA:泥地2 MUD
0xB: 岩石2 ROCK
0xC:沙地2 SAND
0xD:水面2 WATER SURFACE
0xE:普通3 Normal
0xF:雪地3 SNOW
0x10:泥地3 MUD
0x11:岩石3 ROCK
0x12:沙地3 SAND";
CM_ SG_ 1360 ICC_DowWaringSw "盲区检测氛围灯联动闪烁开关";
CM_ SG_ 1360 ICC_CarSearhSetSwitchSts "寻车设置";
CM_ SG_ 1362 ICC_LISD_RollingCounter "顺序计数器，确保图片数据按预期顺序发送、接收。";
CM_ SG_ 1362 ICC_LISD_Pixel1_OnOff "对应像素点的亮灭";
CM_ SG_ 1362 ICC_LISD_Pixel2_OnOff "对应像素点的亮灭";
CM_ SG_ 1362 ICC_LISD_Pixel3_OnOff "对应像素点的亮灭";
CM_ SG_ 1362 ICC_LISD_Pixel4_OnOff "对应像素点的亮灭";
CM_ SG_ 1362 ICC_LISD_Pixel5_OnOff "对应像素点的亮灭";
CM_ SG_ 1362 ICC_LISD_Pixel6_OnOff "对应像素点的亮灭";
CM_ SG_ 1362 ICC_LISD_Pixel7_OnOff "对应像素点的亮灭";
CM_ SG_ 1362 ICC_LISD_Pixel8_OnOff "对应像素点的亮灭";
CM_ SG_ 1362 ICC_LISD_Pixel9_OnOff "对应像素点的亮灭";
CM_ SG_ 1362 ICC_LISD_Pixel10_OnOff "对应像素点的亮灭";
CM_ SG_ 1362 ICC_LISD_Pixel11_OnOff "对应像素点的亮灭";
CM_ SG_ 1362 ICC_LISD_Pixel12_OnOff "对应像素点的亮灭";
CM_ SG_ 1362 ICC_LISD_Pixel13_OnOff "对应像素点的亮灭";
CM_ SG_ 1362 ICC_LISD_Pixel14_OnOff "对应像素点的亮灭";
CM_ SG_ 1362 ICC_LISD_Pixel15_OnOff "对应像素点的亮灭";
CM_ SG_ 1362 ICC_LISD_Pixel16_OnOff "对应像素点的亮灭";
CM_ SG_ 1362 ICC_LISD_Pixel17_OnOff "对应像素点的亮灭";
CM_ SG_ 1362 ICC_LISD_Pixel18_OnOff "对应像素点的亮灭";
CM_ SG_ 1362 ICC_LISD_Pixel19_OnOff "对应像素点的亮灭";
CM_ SG_ 1362 ICC_LISD_Pixel20_OnOff "对应像素点的亮灭";
CM_ SG_ 1362 ICC_LISD_Pixel21_OnOff "对应像素点的亮灭";
CM_ SG_ 1362 ICC_LISD_Pixel22_OnOff "对应像素点的亮灭";
CM_ SG_ 1362 ICC_LISD_Pixel23_OnOff "对应像素点的亮灭";
CM_ SG_ 1362 ICC_LISD_Pixel24_OnOff "对应像素点的亮灭";
CM_ SG_ 1362 ICC_LISD_Pixel25_OnOff "对应像素点的亮灭";
CM_ SG_ 1362 ICC_LISD_Pixel26_OnOff "对应像素点的亮灭";
CM_ SG_ 1362 ICC_LISD_Pixel27_OnOff "对应像素点的亮灭";
CM_ SG_ 1362 ICC_LISD_Pixel28_OnOff "对应像素点的亮灭";
CM_ SG_ 1362 ICC_LISD_Pixel29_OnOff "对应像素点的亮灭";
CM_ SG_ 1362 ICC_LISD_Pixel30_OnOff "对应像素点的亮灭";
CM_ SG_ 1362 ICC_LISD_Pixel31_OnOff "对应像素点的亮灭";
CM_ SG_ 1362 ICC_LISD_Pixel32_OnOff "对应像素点的亮灭";
CM_ SG_ 1362 ICC_LISD_Pixel33_OnOff "对应像素点的亮灭";
CM_ SG_ 1362 ICC_LISD_Pixel34_OnOff "对应像素点的亮灭";
CM_ SG_ 1362 ICC_LISD_Pixel35_OnOff "对应像素点的亮灭";
CM_ SG_ 1362 ICC_LISD_Pixel36_OnOff "对应像素点的亮灭";
CM_ SG_ 1362 ICC_LISD_Pixel37_OnOff "对应像素点的亮灭";
CM_ SG_ 1362 ICC_LISD_Pixel38_OnOff "对应像素点的亮灭";
CM_ SG_ 1362 ICC_LISD_Pixel39_OnOff "对应像素点的亮灭";
CM_ SG_ 1362 ICC_LISD_Pixel40_OnOff "对应像素点的亮灭";
CM_ SG_ 1362 ICC_LISD_Pixel41_OnOff "对应像素点的亮灭";
CM_ SG_ 1362 ICC_LISD_Pixel42_OnOff "对应像素点的亮灭";
CM_ SG_ 1362 ICC_LISD_Pixel43_OnOff "对应像素点的亮灭";
CM_ SG_ 1362 ICC_LISD_Pixel44_OnOff "对应像素点的亮灭";
CM_ SG_ 1362 ICC_LISD_Pixel45_OnOff "对应像素点的亮灭";
CM_ SG_ 1362 ICC_LISD_Pixel46_OnOff "对应像素点的亮灭";
CM_ SG_ 1362 ICC_LISD_Pixel47_OnOff "对应像素点的亮灭";
CM_ SG_ 1362 ICC_LISD_Pixel48_OnOff "对应像素点的亮灭";
CM_ SG_ 1362 ICC_LISD_Pixel49_OnOff "对应像素点的亮灭";
CM_ SG_ 1362 ICC_LISD_Pixel50_OnOff "对应像素点的亮灭";
CM_ SG_ 1362 ICC_LISD_Pixel51_OnOff "对应像素点的亮灭";
CM_ SG_ 1362 ICC_LISD_Pixel52_OnOff "对应像素点的亮灭";
CM_ SG_ 1362 ICC_LISD_Pixel53_OnOff "对应像素点的亮灭";
CM_ SG_ 1362 ICC_LISD_Pixel54_OnOff "对应像素点的亮灭";
CM_ SG_ 1362 ICC_LISD_Pixel55_OnOff "对应像素点的亮灭";
CM_ SG_ 1362 ICC_LISD_Pixel56_OnOff "对应像素点的亮灭";
CM_ SG_ 1362 ICC_LISD_Pixel57_OnOff "对应像素点的亮灭";
CM_ SG_ 1362 ICC_LISD_Pixel58_OnOff "对应像素点的亮灭";
CM_ SG_ 1362 ICC_LISD_Pixel59_OnOff "对应像素点的亮灭";
CM_ SG_ 1362 ICC_LISD_Pixel60_OnOff "对应像素点的亮灭";
CM_ SG_ 1362 ICC_LISD_Pixel61_OnOff "对应像素点的亮灭";
CM_ SG_ 1362 ICC_LISD_Pixel62_OnOff "对应像素点的亮灭";
CM_ SG_ 1362 ICC_LISD_Pixel63_OnOff "对应像素点的亮灭";
CM_ SG_ 1362 ICC_LISD_Pixel64_OnOff "对应像素点的亮灭";
CM_ SG_ 1362 ICC_LISD_Pixel65_OnOff "对应像素点的亮灭";
CM_ SG_ 1362 ICC_LISD_Pixel66_OnOff "对应像素点的亮灭";
CM_ SG_ 1362 ICC_LISD_Pixel67_OnOff "对应像素点的亮灭";
CM_ SG_ 1362 ICC_LISD_Pixel68_OnOff "对应像素点的亮灭";
CM_ SG_ 1362 ICC_LISD_Pixel69_OnOff "对应像素点的亮灭";
CM_ SG_ 1362 ICC_LISD_Pixel70_OnOff "对应像素点的亮灭";
CM_ SG_ 1362 ICC_LISD_Pixel71_OnOff "对应像素点的亮灭";
CM_ SG_ 1362 ICC_LISD_Pixel72_OnOff "对应像素点的亮灭";
CM_ SG_ 1362 ICC_LISD_Pixel73_OnOff "对应像素点的亮灭";
CM_ SG_ 1362 ICC_LISD_Pixel74_OnOff "对应像素点的亮灭";
CM_ SG_ 1362 ICC_LISD_Pixel75_OnOff "对应像素点的亮灭";
CM_ SG_ 1362 ICC_LISD_Pixel76_OnOff "对应像素点的亮灭";
CM_ SG_ 1362 ICC_LISD_Pixel77_OnOff "对应像素点的亮灭";
CM_ SG_ 1362 ICC_LISD_Pixel78_OnOff "对应像素点的亮灭";
CM_ SG_ 1362 ICC_LISD_Pixel79_OnOff "对应像素点的亮灭";
CM_ SG_ 1362 ICC_LISD_Pixel80_OnOff "对应像素点的亮灭";
CM_ SG_ 1362 ICC_LISD_Pixel81_OnOff "对应像素点的亮灭";
CM_ SG_ 1362 ICC_LISD_Pixel82_OnOff "对应像素点的亮灭";
CM_ SG_ 1362 ICC_LISD_Pixel83_OnOff "对应像素点的亮灭";
CM_ SG_ 1362 ICC_LISD_Pixel84_OnOff "对应像素点的亮灭";
CM_ SG_ 1362 ICC_LISD_Pixel85_OnOff "对应像素点的亮灭";
CM_ SG_ 1362 ICC_LISD_Pixel86_OnOff "对应像素点的亮灭";
CM_ SG_ 1362 ICC_LISD_Pixel87_OnOff "对应像素点的亮灭";
CM_ SG_ 1362 ICC_LISD_Pixel88_OnOff "对应像素点的亮灭";
CM_ SG_ 1362 ICC_LISD_Pixel89_OnOff "对应像素点的亮灭";
CM_ SG_ 1362 ICC_LISD_Pixel90_OnOff "对应像素点的亮灭";
CM_ SG_ 1362 ICC_LISD_Pixel91_OnOff "对应像素点的亮灭";
CM_ SG_ 1362 ICC_LISD_Pixel92_OnOff "对应像素点的亮灭";
CM_ SG_ 1362 ICC_LISD_Pixel93_OnOff "对应像素点的亮灭";
CM_ SG_ 1362 ICC_LISD_Pixel94_OnOff "对应像素点的亮灭";
CM_ SG_ 1362 ICC_LISD_Pixel95_OnOff "对应像素点的亮灭";
CM_ SG_ 1362 ICC_LISD_Pixel96_OnOff "对应像素点的亮灭";
CM_ SG_ 1362 ICC_LISD_Pixel97_OnOff "对应像素点的亮灭";
CM_ SG_ 1362 ICC_LISD_Pixel98_OnOff "对应像素点的亮灭";
CM_ SG_ 1362 ICC_LISD_Pixel99_OnOff "对应像素点的亮灭";
CM_ SG_ 1362 ICC_LISD_Pixel100_OnOff "对应像素点的亮灭";
CM_ SG_ 1362 ICC_LISD_Pixel101_OnOff "对应像素点的亮灭";
CM_ SG_ 1362 ICC_LISD_Pixel102_OnOff "对应像素点的亮灭";
CM_ SG_ 1362 ICC_LISD_Pixel103_OnOff "对应像素点的亮灭";
CM_ SG_ 1362 ICC_LISD_Pixel104_OnOff "对应像素点的亮灭";
CM_ SG_ 1362 ICC_LISD_Pixel105_OnOff "对应像素点的亮灭";
CM_ SG_ 1362 ICC_LISD_Pixel106_OnOff "对应像素点的亮灭";
CM_ SG_ 1362 ICC_LISD_Pixel107_OnOff "对应像素点的亮灭";
CM_ SG_ 1362 ICC_LISD_Pixel108_OnOff "对应像素点的亮灭";
CM_ SG_ 1362 ICC_LISD_Pixel109_OnOff "对应像素点的亮灭";
CM_ SG_ 1362 ICC_LISD_Pixel110_OnOff "对应像素点的亮灭";
CM_ SG_ 1362 ICC_LISD_Pixel111_OnOff "对应像素点的亮灭";
CM_ SG_ 1362 ICC_LISD_Pixel112_OnOff "对应像素点的亮灭";
CM_ SG_ 1362 ICC_LISD_Pixel113_OnOff "对应像素点的亮灭";
CM_ SG_ 1362 ICC_LISD_Pixel114_OnOff "对应像素点的亮灭";
CM_ SG_ 1362 ICC_LISD_Pixel115_OnOff "对应像素点的亮灭";
CM_ SG_ 1362 ICC_LISD_Pixel116_OnOff "对应像素点的亮灭";
CM_ SG_ 1362 ICC_LISD_Pixel117_OnOff "对应像素点的亮灭";
CM_ SG_ 1362 ICC_LISD_Pixel118_OnOff "对应像素点的亮灭";
CM_ SG_ 1362 ICC_LISD_Pixel119_OnOff "对应像素点的亮灭";
CM_ SG_ 1362 ICC_LISD_Pixel120_OnOff "对应像素点的亮灭";
CM_ SG_ 1362 ICC_LISD_Pixel121_OnOff "对应像素点的亮灭";
CM_ SG_ 1362 ICC_LISD_Pixel122_OnOff "对应像素点的亮灭";
CM_ SG_ 1362 ICC_LISD_Pixel123_OnOff "对应像素点的亮灭";
CM_ SG_ 1362 ICC_LISD_Pixel124_OnOff "对应像素点的亮灭";
CM_ SG_ 1362 ICC_LISD_Pixel125_OnOff "对应像素点的亮灭";
CM_ SG_ 1362 ICC_LISD_Pixel126_OnOff "对应像素点的亮灭";
CM_ SG_ 1362 ICC_LISD_Pixel127_OnOff "对应像素点的亮灭";
CM_ SG_ 1362 ICC_LISD_Pixel128_OnOff "对应像素点的亮灭";
CM_ SG_ 1362 ICC_LISD_Pixel129_OnOff "对应像素点的亮灭";
CM_ SG_ 1362 ICC_LISD_Pixel130_OnOff "对应像素点的亮灭";
CM_ SG_ 1362 ICC_LISD_Pixel131_OnOff "对应像素点的亮灭";
CM_ SG_ 1362 ICC_LISD_Pixel132_OnOff "对应像素点的亮灭";
CM_ SG_ 1362 ICC_LISD_Pixel133_OnOff "对应像素点的亮灭";
CM_ SG_ 1362 ICC_LISD_Pixel134_OnOff "对应像素点的亮灭";
CM_ SG_ 1362 ICC_LISD_Pixel135_OnOff "对应像素点的亮灭";
CM_ SG_ 1362 ICC_LISD_Pixel136_OnOff "对应像素点的亮灭";
CM_ SG_ 1362 ICC_LISD_Pixel137_OnOff "对应像素点的亮灭";
CM_ SG_ 1362 ICC_LISD_Pixel138_OnOff "对应像素点的亮灭";
CM_ SG_ 1362 ICC_LISD_Pixel139_OnOff "对应像素点的亮灭";
CM_ SG_ 1362 ICC_LISD_Pixel140_OnOff "对应像素点的亮灭";
CM_ SG_ 1362 ICC_LISD_Pixel141_OnOff "对应像素点的亮灭";
CM_ SG_ 1362 ICC_LISD_Pixel142_OnOff "对应像素点的亮灭";
CM_ SG_ 1362 ICC_LISD_Pixel143_OnOff "对应像素点的亮灭";
CM_ SG_ 1362 ICC_LISD_Pixel144_OnOff "对应像素点的亮灭";
CM_ SG_ 1362 ICC_LISD_Pixel145_OnOff "对应像素点的亮灭";
CM_ SG_ 1362 ICC_LISD_Pixel146_OnOff "对应像素点的亮灭";
CM_ SG_ 1362 ICC_LISD_Pixel147_OnOff "对应像素点的亮灭";
CM_ SG_ 1362 ICC_LISD_Pixel148_OnOff "对应像素点的亮灭";
CM_ SG_ 1362 ICC_LISD_Pixel149_OnOff "对应像素点的亮灭";
CM_ SG_ 1362 ICC_LISD_Pixel150_OnOff "对应像素点的亮灭";
CM_ SG_ 1362 ICC_LISD_Pixel151_OnOff "对应像素点的亮灭";
CM_ SG_ 1362 ICC_LISD_Pixel152_OnOff "对应像素点的亮灭";
CM_ SG_ 1362 ICC_LISD_Pixel153_OnOff "对应像素点的亮灭";
CM_ SG_ 1362 ICC_LISD_Pixel154_OnOff "对应像素点的亮灭";
CM_ SG_ 1362 ICC_LISD_Pixel155_OnOff "对应像素点的亮灭";
CM_ SG_ 1362 ICC_LISD_Pixel156_OnOff "对应像素点的亮灭";
CM_ SG_ 1362 ICC_LISD_Pixel157_OnOff "对应像素点的亮灭";
CM_ SG_ 1362 ICC_LISD_Pixel158_OnOff "对应像素点的亮灭";
CM_ SG_ 1362 ICC_LISD_Pixel159_OnOff "对应像素点的亮灭";
CM_ SG_ 1362 ICC_LISD_Pixel160_OnOff "对应像素点的亮灭";
CM_ SG_ 1362 ICC_LISD_Pixel161_OnOff "对应像素点的亮灭";
CM_ SG_ 1362 ICC_LISD_Pixel162_OnOff "对应像素点的亮灭";
CM_ SG_ 1362 ICC_LISD_Pixel163_OnOff "对应像素点的亮灭";
CM_ SG_ 1362 ICC_LISD_Pixel164_OnOff "对应像素点的亮灭";
CM_ SG_ 1362 ICC_LISD_Pixel165_OnOff "对应像素点的亮灭";
CM_ SG_ 1362 ICC_LISD_Pixel166_OnOff "对应像素点的亮灭";
CM_ SG_ 1362 ICC_LISD_Pixel167_OnOff "对应像素点的亮灭";
CM_ SG_ 1362 ICC_LISD_Pixel168_OnOff "对应像素点的亮灭";
CM_ SG_ 1362 ICC_LISD_Pixel169_OnOff "对应像素点的亮灭";
CM_ SG_ 1362 ICC_LISD_Pixel170_OnOff "对应像素点的亮灭";
CM_ SG_ 1362 ICC_LISD_Pixel171_OnOff "对应像素点的亮灭";
CM_ SG_ 1362 ICC_LISD_Pixel172_OnOff "对应像素点的亮灭";
CM_ SG_ 1362 ICC_LISD_Pixel173_OnOff "对应像素点的亮灭";
CM_ SG_ 1362 ICC_LISD_Pixel174_OnOff "对应像素点的亮灭";
CM_ SG_ 1362 ICC_LISD_Pixel175_OnOff "对应像素点的亮灭";
CM_ SG_ 1362 ICC_LISD_Pixel176_OnOff "对应像素点的亮灭";
CM_ SG_ 1362 ICC_LISD_Pixel177_OnOff "对应像素点的亮灭";
CM_ SG_ 1362 ICC_LISD_Pixel178_OnOff "对应像素点的亮灭";
CM_ SG_ 1362 ICC_LISD_Pixel179_OnOff "对应像素点的亮灭";
CM_ SG_ 1362 ICC_LISD_Pixel180_OnOff "对应像素点的亮灭";
CM_ SG_ 1362 ICC_LISD_Pixel181_OnOff "对应像素点的亮灭";
CM_ SG_ 1362 ICC_LISD_Pixel182_OnOff "对应像素点的亮灭";
CM_ SG_ 1362 ICC_LISD_Pixel183_OnOff "对应像素点的亮灭";
CM_ SG_ 1362 ICC_LISD_Pixel184_OnOff "对应像素点的亮灭";
CM_ SG_ 1362 ICC_LISD_Pixel185_OnOff "对应像素点的亮灭";
CM_ SG_ 1362 ICC_LISD_Pixel186_OnOff "对应像素点的亮灭";
CM_ SG_ 1362 ICC_LISD_Pixel187_OnOff "对应像素点的亮灭";
CM_ SG_ 1362 ICC_LISD_Pixel188_OnOff "对应像素点的亮灭";
CM_ SG_ 1362 ICC_LISD_Pixel189_OnOff "对应像素点的亮灭";
CM_ SG_ 1362 ICC_LISD_Pixel190_OnOff "对应像素点的亮灭";
CM_ SG_ 1362 ICC_LISD_Pixel191_OnOff "对应像素点的亮灭";
CM_ SG_ 1362 ICC_LISD_Pixel192_OnOff "对应像素点的亮灭";
CM_ SG_ 1362 ICC_LISD_Pixel193_OnOff "对应像素点的亮灭";
CM_ SG_ 1362 ICC_LISD_Pixel194_OnOff "对应像素点的亮灭";
CM_ SG_ 1362 ICC_LISD_Pixel195_OnOff "对应像素点的亮灭";
CM_ SG_ 1362 ICC_LISD_Pixel196_OnOff "对应像素点的亮灭";
CM_ SG_ 1362 ICC_LISD_Pixel197_OnOff "对应像素点的亮灭";
CM_ SG_ 1362 ICC_LISD_Pixel198_OnOff "对应像素点的亮灭";
CM_ SG_ 1362 ICC_LISD_Pixel199_OnOff "对应像素点的亮灭";
CM_ SG_ 1362 ICC_LISD_Pixel200_OnOff "对应像素点的亮灭";
CM_ SG_ 1362 ICC_LISD_Pixel201_OnOff "对应像素点的亮灭";
CM_ SG_ 1362 ICC_LISD_Pixel202_OnOff "对应像素点的亮灭";
CM_ SG_ 1362 ICC_LISD_Pixel203_OnOff "对应像素点的亮灭";
CM_ SG_ 1362 ICC_LISD_Pixel204_OnOff "对应像素点的亮灭";
CM_ SG_ 1362 ICC_LISD_Pixel205_OnOff "对应像素点的亮灭";
CM_ SG_ 1362 ICC_LISD_Pixel206_OnOff "对应像素点的亮灭";
CM_ SG_ 1362 ICC_LISD_Pixel207_OnOff "对应像素点的亮灭";
CM_ SG_ 1362 ICC_LISD_Pixel208_OnOff "对应像素点的亮灭";
CM_ SG_ 1362 ICC_LISD_Pixel209_OnOff "对应像素点的亮灭";
CM_ SG_ 1362 ICC_LISD_Pixel210_OnOff "对应像素点的亮灭";
CM_ SG_ 1362 ICC_LISD_Pixel211_OnOff "对应像素点的亮灭";
CM_ SG_ 1362 ICC_LISD_Pixel212_OnOff "对应像素点的亮灭";
CM_ SG_ 1362 ICC_LISD_Pixel213_OnOff "对应像素点的亮灭";
CM_ SG_ 1362 ICC_LISD_Pixel214_OnOff "对应像素点的亮灭";
CM_ SG_ 1362 ICC_LISD_Pixel215_OnOff "对应像素点的亮灭";
CM_ SG_ 1362 ICC_LISD_Pixel216_OnOff "对应像素点的亮灭";
CM_ SG_ 1362 ICC_LISD_Pixel217_OnOff "对应像素点的亮灭";
CM_ SG_ 1362 ICC_LISD_Pixel218_OnOff "对应像素点的亮灭";
CM_ SG_ 1362 ICC_LISD_Pixel219_OnOff "对应像素点的亮灭";
CM_ SG_ 1362 ICC_LISD_Pixel220_OnOff "对应像素点的亮灭";
CM_ SG_ 1362 ICC_LISD_Pixel221_OnOff "对应像素点的亮灭";
CM_ SG_ 1362 ICC_LISD_Pixel222_OnOff "对应像素点的亮灭";
CM_ SG_ 1362 ICC_LISD_Pixel223_OnOff "对应像素点的亮灭";
CM_ SG_ 1362 ICC_LISD_Pixel224_OnOff "对应像素点的亮灭";
CM_ SG_ 1362 ICC_LISD_Pixel225_OnOff "对应像素点的亮灭";
CM_ SG_ 1362 ICC_LISD_Pixel226_OnOff "对应像素点的亮灭";
CM_ SG_ 1362 ICC_LISD_Pixel227_OnOff "对应像素点的亮灭";
CM_ SG_ 1362 ICC_LISD_Pixel228_OnOff "对应像素点的亮灭";
CM_ SG_ 1362 ICC_LISD_Pixel229_OnOff "对应像素点的亮灭";
CM_ SG_ 1362 ICC_LISD_Pixel230_OnOff "对应像素点的亮灭";
CM_ SG_ 1362 ICC_LISD_Pixel231_OnOff "对应像素点的亮灭";
CM_ SG_ 1362 ICC_LISD_Pixel232_OnOff "对应像素点的亮灭";
CM_ SG_ 1362 ICC_LISD_Pixel233_OnOff "对应像素点的亮灭";
CM_ SG_ 1362 ICC_LISD_Pixel234_OnOff "对应像素点的亮灭";
CM_ SG_ 1362 ICC_LISD_Pixel235_OnOff "对应像素点的亮灭";
CM_ SG_ 1362 ICC_LISD_Pixel236_OnOff "对应像素点的亮灭";
CM_ SG_ 1362 ICC_LISD_Pixel237_OnOff "对应像素点的亮灭";
CM_ SG_ 1362 ICC_LISD_Pixel238_OnOff "对应像素点的亮灭";
CM_ SG_ 1362 ICC_LISD_Pixel239_OnOff "对应像素点的亮灭";
CM_ SG_ 1362 ICC_LISD_Pixel240_OnOff "对应像素点的亮灭";
CM_ SG_ 1362 ICC_LISD_Pixel241_OnOff "对应像素点的亮灭";
CM_ SG_ 1362 ICC_LISD_Pixel242_OnOff "对应像素点的亮灭";
CM_ SG_ 1362 ICC_LISD_Pixel243_OnOff "对应像素点的亮灭";
CM_ SG_ 1362 ICC_LISD_Pixel244_OnOff "对应像素点的亮灭";
CM_ SG_ 1362 ICC_LISD_Pixel245_OnOff "对应像素点的亮灭";
CM_ SG_ 1362 ICC_LISD_Pixel246_OnOff "对应像素点的亮灭";
CM_ SG_ 1362 ICC_LISD_Pixel247_OnOff "对应像素点的亮灭";
CM_ SG_ 1362 ICC_LISD_Pixel248_OnOff "对应像素点的亮灭";
CM_ SG_ 1362 ICC_LISD_Pixel249_OnOff "对应像素点的亮灭";
CM_ SG_ 1362 ICC_LISD_Pixel250_OnOff "对应像素点的亮灭";
CM_ SG_ 1362 ICC_LISD_Pixel251_OnOff "对应像素点的亮灭";
CM_ SG_ 1362 ICC_LISD_Pixel252_OnOff "对应像素点的亮灭";
CM_ SG_ 1362 ICC_LISD_Pixel253_OnOff "对应像素点的亮灭";
CM_ SG_ 1362 ICC_LISD_Pixel254_OnOff "对应像素点的亮灭";
CM_ SG_ 1362 ICC_LISD_Pixel255_OnOff "对应像素点的亮灭";
CM_ SG_ 1362 ICC_LISD_Pixel256_OnOff "对应像素点的亮灭";
CM_ SG_ 1362 ICC_LISD_Pixel257_OnOff "对应像素点的亮灭";
CM_ SG_ 1362 ICC_LISD_Pixel258_OnOff "对应像素点的亮灭";
CM_ SG_ 1362 ICC_LISD_Pixel259_OnOff "对应像素点的亮灭";
CM_ SG_ 1362 ICC_LISD_Pixel260_OnOff "对应像素点的亮灭";
CM_ SG_ 1362 ICC_LISD_Pixel261_OnOff "对应像素点的亮灭";
CM_ SG_ 1362 ICC_LISD_Pixel262_OnOff "对应像素点的亮灭";
CM_ SG_ 1362 ICC_LISD_Pixel263_OnOff "对应像素点的亮灭";
CM_ SG_ 1362 ICC_LISD_Pixel264_OnOff "对应像素点的亮灭";
CM_ SG_ 1362 ICC_LISD_Pixel265_OnOff "对应像素点的亮灭";
CM_ SG_ 1362 ICC_LISD_Pixel266_OnOff "对应像素点的亮灭";
CM_ SG_ 1362 ICC_LISD_Pixel267_OnOff "对应像素点的亮灭";
CM_ SG_ 1362 ICC_LISD_Pixel268_OnOff "对应像素点的亮灭";
CM_ SG_ 1362 ICC_LISD_Pixel269_OnOff "对应像素点的亮灭";
CM_ SG_ 1362 ICC_LISD_Pixel270_OnOff "对应像素点的亮灭";
CM_ SG_ 1362 ICC_LISD_Pixel271_OnOff "对应像素点的亮灭";
CM_ SG_ 1362 ICC_LISD_Pixel272_OnOff "对应像素点的亮灭";
CM_ SG_ 1362 ICC_LISD_Pixel273_OnOff "对应像素点的亮灭";
CM_ SG_ 1362 ICC_LISD_Pixel274_OnOff "对应像素点的亮灭";
CM_ SG_ 1362 ICC_LISD_Pixel275_OnOff "对应像素点的亮灭";
CM_ SG_ 1362 ICC_LISD_Pixel276_OnOff "对应像素点的亮灭";
CM_ SG_ 1362 ICC_LISD_Pixel277_OnOff "对应像素点的亮灭";
CM_ SG_ 1362 ICC_LISD_Pixel278_OnOff "对应像素点的亮灭";
CM_ SG_ 1362 ICC_LISD_Pixel279_OnOff "对应像素点的亮灭";
CM_ SG_ 1362 ICC_LISD_Pixel280_OnOff "对应像素点的亮灭";
CM_ SG_ 1362 ICC_LISD_Pixel281_OnOff "对应像素点的亮灭";
CM_ SG_ 1362 ICC_LISD_Pixel282_OnOff "对应像素点的亮灭";
CM_ SG_ 1362 ICC_LISD_Pixel283_OnOff "对应像素点的亮灭";
CM_ SG_ 1362 ICC_LISD_Pixel284_OnOff "对应像素点的亮灭";
CM_ SG_ 1362 ICC_LISD_Pixel285_OnOff "对应像素点的亮灭";
CM_ SG_ 1362 ICC_LISD_Pixel286_OnOff "对应像素点的亮灭";
CM_ SG_ 1362 ICC_LISD_Pixel287_OnOff "对应像素点的亮灭";
CM_ SG_ 1362 ICC_LISD_Pixel288_OnOff "对应像素点的亮灭";
CM_ SG_ 1362 ICC_LISD_Pixel289_OnOff "对应像素点的亮灭";
CM_ SG_ 1362 ICC_LISD_Pixel290_OnOff "对应像素点的亮灭";
CM_ SG_ 1362 ICC_LISD_Pixel291_OnOff "对应像素点的亮灭";
CM_ SG_ 1362 ICC_LISD_Pixel292_OnOff "对应像素点的亮灭";
CM_ SG_ 1362 ICC_LISD_Pixel293_OnOff "对应像素点的亮灭";
CM_ SG_ 1362 ICC_LISD_Pixel294_OnOff "对应像素点的亮灭";
CM_ SG_ 1362 ICC_LISD_Pixel295_OnOff "对应像素点的亮灭";
CM_ SG_ 1362 ICC_LISD_Pixel296_OnOff "对应像素点的亮灭";
CM_ SG_ 1362 ICC_LISD_Pixel297_OnOff "对应像素点的亮灭";
CM_ SG_ 1362 ICC_LISD_Pixel298_OnOff "对应像素点的亮灭";
CM_ SG_ 1362 ICC_LISD_Pixel299_OnOff "对应像素点的亮灭";
CM_ SG_ 1362 ICC_LISD_Pixel300_OnOff "对应像素点的亮灭";
CM_ SG_ 1362 ICC_LISD_Pixel301_OnOff "对应像素点的亮灭";
CM_ SG_ 1362 ICC_LISD_Pixel302_OnOff "对应像素点的亮灭";
CM_ SG_ 1362 ICC_LISD_Pixel303_OnOff "对应像素点的亮灭";
CM_ SG_ 1362 ICC_LISD_Pixel304_OnOff "对应像素点的亮灭";
CM_ SG_ 1362 ICC_LISD_Pixel305_OnOff "对应像素点的亮灭";
CM_ SG_ 1362 ICC_LISD_Pixel306_OnOff "对应像素点的亮灭";
CM_ SG_ 1362 ICC_LISD_Pixel307_OnOff "对应像素点的亮灭";
CM_ SG_ 1362 ICC_LISD_Pixel308_OnOff "对应像素点的亮灭";
CM_ SG_ 1362 ICC_LISD_Pixel309_OnOff "对应像素点的亮灭";
CM_ SG_ 1362 ICC_LISD_Pixel310_OnOff "对应像素点的亮灭";
CM_ SG_ 1362 ICC_LISD_Pixel311_OnOff "对应像素点的亮灭";
CM_ SG_ 1362 ICC_LISD_Pixel312_OnOff "对应像素点的亮灭";
CM_ SG_ 1362 ICC_LISD_Pixel313_OnOff "对应像素点的亮灭";
CM_ SG_ 1362 ICC_LISD_Pixel314_OnOff "对应像素点的亮灭";
CM_ SG_ 1362 ICC_LISD_Pixel315_OnOff "对应像素点的亮灭";
CM_ SG_ 1362 ICC_LISD_Pixel316_OnOff "对应像素点的亮灭";
CM_ SG_ 1362 ICC_LISD_Pixel317_OnOff "对应像素点的亮灭";
CM_ SG_ 1362 ICC_LISD_Pixel318_OnOff "对应像素点的亮灭";
CM_ SG_ 1362 ICC_LISD_Pixel319_OnOff "对应像素点的亮灭";
CM_ SG_ 1362 ICC_LISD_Pixel320_OnOff "对应像素点的亮灭";
CM_ SG_ 1362 ICC_LISD_Pixel321_OnOff "对应像素点的亮灭";
CM_ SG_ 1362 ICC_LISD_Pixel322_OnOff "对应像素点的亮灭";
CM_ SG_ 1362 ICC_LISD_Pixel323_OnOff "对应像素点的亮灭";
CM_ SG_ 1362 ICC_LISD_Pixel324_OnOff "对应像素点的亮灭";
CM_ SG_ 1362 ICC_LISD_Pixel325_OnOff "对应像素点的亮灭";
CM_ SG_ 1362 ICC_LISD_Pixel326_OnOff "对应像素点的亮灭";
CM_ SG_ 1362 ICC_LISD_Pixel327_OnOff "对应像素点的亮灭";
CM_ SG_ 1362 ICC_LISD_Pixel328_OnOff "对应像素点的亮灭";
CM_ SG_ 1362 ICC_LISD_Pixel329_OnOff "对应像素点的亮灭";
CM_ SG_ 1362 ICC_LISD_Pixel330_OnOff "对应像素点的亮灭";
CM_ SG_ 1362 ICC_LISD_Pixel331_OnOff "对应像素点的亮灭";
CM_ SG_ 1362 ICC_LISD_Pixel332_OnOff "对应像素点的亮灭";
CM_ SG_ 1362 ICC_LISD_Pixel333_OnOff "对应像素点的亮灭";
CM_ SG_ 1362 ICC_LISD_Pixel334_OnOff "对应像素点的亮灭";
CM_ SG_ 1362 ICC_LISD_Pixel335_OnOff "对应像素点的亮灭";
CM_ SG_ 1362 ICC_LISD_Pixel336_OnOff "对应像素点的亮灭";
CM_ SG_ 1362 ICC_LISD_Pixel337_OnOff "对应像素点的亮灭";
CM_ SG_ 1362 ICC_LISD_Pixel338_OnOff "对应像素点的亮灭";
CM_ SG_ 1362 ICC_LISD_Pixel339_OnOff "对应像素点的亮灭";
CM_ SG_ 1362 ICC_LISD_Pixel340_OnOff "对应像素点的亮灭";
CM_ SG_ 1362 ICC_LISD_Pixel341_OnOff "对应像素点的亮灭";
CM_ SG_ 1362 ICC_LISD_Pixel342_OnOff "对应像素点的亮灭";
CM_ SG_ 1362 ICC_LISD_Pixel343_OnOff "对应像素点的亮灭";
CM_ SG_ 1362 ICC_LISD_Pixel344_OnOff "对应像素点的亮灭";
CM_ SG_ 1362 ICC_LISD_Pixel345_OnOff "对应像素点的亮灭";
CM_ SG_ 1362 ICC_LISD_Pixel346_OnOff "对应像素点的亮灭";
CM_ SG_ 1362 ICC_LISD_Pixel347_OnOff "对应像素点的亮灭";
CM_ SG_ 1362 ICC_LISD_Pixel348_OnOff "对应像素点的亮灭";
CM_ SG_ 1362 ICC_LISD_Pixel349_OnOff "对应像素点的亮灭";
CM_ SG_ 1362 ICC_LISD_Pixel350_OnOff "对应像素点的亮灭";
CM_ SG_ 1362 ICC_LISD_Pixel351_OnOff "对应像素点的亮灭";
CM_ SG_ 1362 ICC_LISD_Pixel352_OnOff "对应像素点的亮灭";
CM_ SG_ 1362 ICC_LISD_Pixel353_OnOff "对应像素点的亮灭";
CM_ SG_ 1362 ICC_LISD_Pixel354_OnOff "对应像素点的亮灭";
CM_ SG_ 1362 ICC_LISD_Pixel355_OnOff "对应像素点的亮灭";
CM_ SG_ 1362 ICC_LISD_Pixel356_OnOff "对应像素点的亮灭";
CM_ SG_ 1362 ICC_LISD_Pixel357_OnOff "对应像素点的亮灭";
CM_ SG_ 1362 ICC_LISD_Pixel358_OnOff "对应像素点的亮灭";
CM_ SG_ 1362 ICC_LISD_Pixel359_OnOff "对应像素点的亮灭";
CM_ SG_ 1362 ICC_LISD_Pixel360_OnOff "对应像素点的亮灭";
CM_ SG_ 1362 ICC_LISD_Pixel361_OnOff "对应像素点的亮灭";
CM_ SG_ 1362 ICC_LISD_Pixel362_OnOff "对应像素点的亮灭";
CM_ SG_ 1362 ICC_LISD_Pixel363_OnOff "对应像素点的亮灭";
CM_ SG_ 1362 ICC_LISD_Pixel364_OnOff "对应像素点的亮灭";
CM_ SG_ 1362 ICC_LISD_Pixel365_OnOff "对应像素点的亮灭";
CM_ SG_ 1362 ICC_LISD_Pixel366_OnOff "对应像素点的亮灭";
CM_ SG_ 1362 ICC_LISD_Pixel367_OnOff "对应像素点的亮灭";
CM_ SG_ 1362 ICC_LISD_Pixel368_OnOff "对应像素点的亮灭";
CM_ SG_ 1362 ICC_LISD_Pixel369_OnOff "对应像素点的亮灭";
CM_ SG_ 1362 ICC_LISD_Pixel370_OnOff "对应像素点的亮灭";
CM_ SG_ 1362 ICC_LISD_Pixel371_OnOff "对应像素点的亮灭";
CM_ SG_ 1362 ICC_LISD_Pixel372_OnOff "对应像素点的亮灭";
CM_ SG_ 1362 ICC_LISD_Pixel373_OnOff "对应像素点的亮灭";
CM_ SG_ 1362 ICC_LISD_Pixel374_OnOff "对应像素点的亮灭";
CM_ SG_ 1362 ICC_LISD_Pixel375_OnOff "对应像素点的亮灭";
CM_ SG_ 1362 ICC_LISD_Pixel376_OnOff "对应像素点的亮灭";
CM_ SG_ 1362 ICC_LISD_Pixel377_OnOff "对应像素点的亮灭";
CM_ SG_ 1362 ICC_LISD_Pixel378_OnOff "对应像素点的亮灭";
CM_ SG_ 1362 ICC_LISD_Pixel379_OnOff "对应像素点的亮灭";
CM_ SG_ 1362 ICC_LISD_Pixel380_OnOff "对应像素点的亮灭";
CM_ SG_ 1362 ICC_LISD_Pixel381_OnOff "对应像素点的亮灭";
CM_ SG_ 1362 ICC_LISD_Pixel382_OnOff "对应像素点的亮灭";
CM_ SG_ 1362 ICC_LISD_Pixel383_OnOff "对应像素点的亮灭";
CM_ SG_ 1362 ICC_LISD_Pixel384_OnOff "对应像素点的亮灭";
CM_ SG_ 1362 ICC_LISD_Pixel385_OnOff "对应像素点的亮灭";
CM_ SG_ 1362 ICC_LISD_Pixel386_OnOff "对应像素点的亮灭";
CM_ SG_ 1362 ICC_LISD_Pixel387_OnOff "对应像素点的亮灭";
CM_ SG_ 1362 ICC_LISD_Pixel388_OnOff "对应像素点的亮灭";
CM_ SG_ 1362 ICC_LISD_Pixel389_OnOff "对应像素点的亮灭";
CM_ SG_ 1362 ICC_LISD_Pixel390_OnOff "对应像素点的亮灭";
CM_ SG_ 1362 ICC_LISD_Pixel391_OnOff "对应像素点的亮灭";
CM_ SG_ 1362 ICC_LISD_Pixel392_OnOff "对应像素点的亮灭";
CM_ SG_ 1362 ICC_LISD_Pixel393_OnOff "对应像素点的亮灭";
CM_ SG_ 1362 ICC_LISD_Pixel394_OnOff "对应像素点的亮灭";
CM_ SG_ 1362 ICC_LISD_Pixel395_OnOff "对应像素点的亮灭";
CM_ SG_ 1362 ICC_LISD_Pixel396_OnOff "对应像素点的亮灭";
CM_ SG_ 1362 ICC_LISD_Pixel397_OnOff "对应像素点的亮灭";
CM_ SG_ 1362 ICC_LISD_Pixel398_OnOff "对应像素点的亮灭";
CM_ SG_ 1362 ICC_LISD_Pixel399_OnOff "对应像素点的亮灭";
CM_ SG_ 1362 ICC_LISD_Pixel400_OnOff "对应像素点的亮灭";
CM_ SG_ 1362 ICC_LISD_Pixel401_OnOff "对应像素点的亮灭";
CM_ SG_ 1362 ICC_LISD_Pixel402_OnOff "对应像素点的亮灭";
CM_ SG_ 1362 ICC_LISD_Pixel403_OnOff "对应像素点的亮灭";
CM_ SG_ 1362 ICC_LISD_Pixel404_OnOff "对应像素点的亮灭";
CM_ SG_ 1362 ICC_LISD_Pixel405_OnOff "对应像素点的亮灭";
CM_ SG_ 1362 ICC_LISD_Pixel406_OnOff "对应像素点的亮灭";
CM_ SG_ 1362 ICC_LISD_Pixel407_OnOff "对应像素点的亮灭";
CM_ SG_ 1362 ICC_LISD_Pixel408_OnOff "对应像素点的亮灭";
CM_ SG_ 1362 ICC_LISD_Pixel409_OnOff "对应像素点的亮灭";
CM_ SG_ 1362 ICC_LISD_Pixel410_OnOff "对应像素点的亮灭";
CM_ SG_ 1362 ICC_LISD_Pixel411_OnOff "对应像素点的亮灭";
CM_ SG_ 1362 ICC_LISD_Pixel412_OnOff "对应像素点的亮灭";
CM_ SG_ 1362 ICC_LISD_Pixel413_OnOff "对应像素点的亮灭";
CM_ SG_ 1362 ICC_LISD_Pixel414_OnOff "对应像素点的亮灭";
CM_ SG_ 1362 ICC_LISD_Pixel415_OnOff "对应像素点的亮灭";
CM_ SG_ 1362 ICC_LISD_Pixel416_OnOff "对应像素点的亮灭";
CM_ SG_ 1362 ICC_LISD_Pixel417_OnOff "对应像素点的亮灭";
CM_ SG_ 1362 ICC_LISD_Pixel418_OnOff "对应像素点的亮灭";
CM_ SG_ 1362 ICC_LISD_Pixel419_OnOff "对应像素点的亮灭";
CM_ SG_ 1362 ICC_LISD_Pixel420_OnOff "对应像素点的亮灭";
CM_ SG_ 1362 ICC_LISD_Pixel421_OnOff "对应像素点的亮灭";
CM_ SG_ 1362 ICC_LISD_Pixel422_OnOff "对应像素点的亮灭";
CM_ SG_ 1362 ICC_LISD_Pixel423_OnOff "对应像素点的亮灭";
CM_ SG_ 1362 ICC_LISD_Pixel424_OnOff "对应像素点的亮灭";
CM_ SG_ 1362 ICC_LISD_Pixel425_OnOff "对应像素点的亮灭";
CM_ SG_ 1362 ICC_LISD_Pixel426_OnOff "对应像素点的亮灭";
CM_ SG_ 1362 ICC_LISD_Pixel427_OnOff "对应像素点的亮灭";
CM_ SG_ 1362 ICC_LISD_Pixel428_OnOff "对应像素点的亮灭";
CM_ SG_ 1362 ICC_LISD_Pixel429_OnOff "对应像素点的亮灭";
CM_ SG_ 1362 ICC_LISD_Pixel430_OnOff "对应像素点的亮灭";
CM_ SG_ 1362 ICC_LISD_Pixel431_OnOff "对应像素点的亮灭";
CM_ SG_ 1362 ICC_LISD_Pixel432_OnOff "对应像素点的亮灭";
CM_ SG_ 1362 ICC_LISD_Pixel433_OnOff "对应像素点的亮灭";
CM_ SG_ 1362 ICC_LISD_Pixel434_OnOff "对应像素点的亮灭";
CM_ SG_ 1362 ICC_LISD_Pixel435_OnOff "对应像素点的亮灭";
CM_ SG_ 1362 ICC_LISD_Pixel436_OnOff "对应像素点的亮灭";
CM_ SG_ 1362 ICC_LISD_Pixel437_OnOff "对应像素点的亮灭";
CM_ SG_ 1362 ICC_LISD_Pixel438_OnOff "对应像素点的亮灭";
CM_ SG_ 1362 ICC_LISD_Pixel439_OnOff "对应像素点的亮灭";
CM_ SG_ 1362 ICC_LISD_Pixel440_OnOff "对应像素点的亮灭";
CM_ SG_ 1362 ICC_LISD_Pixel441_OnOff "对应像素点的亮灭";
CM_ SG_ 1362 ICC_LISD_Pixel442_OnOff "对应像素点的亮灭";
CM_ SG_ 1362 ICC_LISD_Pixel443_OnOff "对应像素点的亮灭";
CM_ SG_ 1362 ICC_LISD_Pixel444_OnOff "对应像素点的亮灭";
CM_ SG_ 1362 ICC_LISD_Pixel445_OnOff "对应像素点的亮灭";
CM_ SG_ 1362 ICC_LISD_Pixel446_OnOff "对应像素点的亮灭";
CM_ SG_ 1362 ICC_LISD_Pixel447_OnOff "对应像素点的亮灭";
CM_ SG_ 1362 ICC_LISD_Pixel448_OnOff "对应像素点的亮灭";
CM_ SG_ 1362 ICC_LISD_Pixel449_OnOff "对应像素点的亮灭";
CM_ SG_ 1362 ICC_LISD_Pixel450_OnOff "对应像素点的亮灭";
CM_ SG_ 1362 ICC_LISD_Pixel451_OnOff "对应像素点的亮灭";
CM_ SG_ 1362 ICC_LISD_Pixel452_OnOff "对应像素点的亮灭";
CM_ SG_ 1362 ICC_LISD_Pixel453_OnOff "对应像素点的亮灭";
CM_ SG_ 1362 ICC_LISD_Pixel454_OnOff "对应像素点的亮灭";
CM_ SG_ 1362 ICC_LISD_Pixel455_OnOff "对应像素点的亮灭";
CM_ SG_ 1362 ICC_LISD_Pixel456_OnOff "对应像素点的亮灭";
CM_ SG_ 1362 ICC_LISD_Pixel457_OnOff "对应像素点的亮灭";
CM_ SG_ 1362 ICC_LISD_Pixel458_OnOff "对应像素点的亮灭";
CM_ SG_ 1362 ICC_LISD_Pixel459_OnOff "对应像素点的亮灭";
CM_ SG_ 1362 ICC_LISD_Pixel460_OnOff "对应像素点的亮灭";
CM_ SG_ 1362 ICC_LISD_Pixel461_OnOff "对应像素点的亮灭";
CM_ SG_ 1362 ICC_LISD_Pixel462_OnOff "对应像素点的亮灭";
CM_ SG_ 1362 ICC_LISD_Pixel463_OnOff "对应像素点的亮灭";
CM_ SG_ 1362 ICC_LISD_Pixel464_OnOff "对应像素点的亮灭";
CM_ SG_ 1362 ICC_LISD_Pixel465_OnOff "对应像素点的亮灭";
CM_ SG_ 1362 ICC_LISD_Pixel466_OnOff "对应像素点的亮灭";
CM_ SG_ 1362 ICC_LISD_Pixel467_OnOff "对应像素点的亮灭";
CM_ SG_ 1362 ICC_LISD_Pixel468_OnOff "对应像素点的亮灭";
CM_ SG_ 1362 ICC_LISD_Pixel469_OnOff "对应像素点的亮灭";
CM_ SG_ 1362 ICC_LISD_Pixel470_OnOff "对应像素点的亮灭";
CM_ SG_ 1362 ICC_LISD_Pixel471_OnOff "对应像素点的亮灭";
CM_ SG_ 1362 ICC_LISD_Pixel472_OnOff "对应像素点的亮灭";
CM_ SG_ 1362 ICC_LISD_Pixel473_OnOff "对应像素点的亮灭";
CM_ SG_ 1362 ICC_LISD_Pixel474_OnOff "对应像素点的亮灭";
CM_ SG_ 1362 ICC_LISD_Pixel475_OnOff "对应像素点的亮灭";
CM_ SG_ 1362 ICC_LISD_Pixel476_OnOff "对应像素点的亮灭";
CM_ SG_ 1362 ICC_LISD_Pixel477_OnOff "对应像素点的亮灭";
CM_ SG_ 1362 ICC_LISD_Pixel478_OnOff "对应像素点的亮灭";
CM_ SG_ 1362 ICC_LISD_Pixel479_OnOff "对应像素点的亮灭";
CM_ SG_ 1362 ICC_LISD_Pixel480_OnOff "对应像素点的亮灭";
CM_ SG_ 1362 ICC_LISD_Pixel481_OnOff "对应像素点的亮灭";
CM_ SG_ 1362 ICC_LISD_Pixel482_OnOff "对应像素点的亮灭";
CM_ SG_ 1362 ICC_LISD_Pixel483_OnOff "对应像素点的亮灭";
CM_ SG_ 1362 ICC_LISD_Pixel484_OnOff "对应像素点的亮灭";
CM_ SG_ 1362 ICC_LISD_Pixel485_OnOff "对应像素点的亮灭";
CM_ SG_ 1362 ICC_LISD_Pixel486_OnOff "对应像素点的亮灭";
CM_ SG_ 1362 ICC_LISD_Pixel487_OnOff "对应像素点的亮灭";
CM_ SG_ 1362 ICC_LISD_Pixel488_OnOff "对应像素点的亮灭";
CM_ SG_ 1362 ICC_LISD_Pixel489_OnOff "对应像素点的亮灭";
CM_ SG_ 1362 ICC_LISD_Pixel490_OnOff "对应像素点的亮灭";
CM_ SG_ 1362 ICC_LISD_Pixel491_OnOff "对应像素点的亮灭";
CM_ SG_ 1362 ICC_LISD_Pixel492_OnOff "对应像素点的亮灭";
CM_ SG_ 1362 ICC_LISD_Pixel493_OnOff "对应像素点的亮灭";
CM_ SG_ 1362 ICC_LISD_Pixel494_OnOff "对应像素点的亮灭";
CM_ SG_ 1362 ICC_LISD_Pixel495_OnOff "对应像素点的亮灭";
CM_ SG_ 1362 ICC_LISD_Pixel496_OnOff "对应像素点的亮灭";
CM_ SG_ 1362 ICC_LISD_Pixel497_OnOff "对应像素点的亮灭";
CM_ SG_ 1362 ICC_LISD_Pixel498_OnOff "对应像素点的亮灭";
CM_ SG_ 1362 ICC_LISD_Pixel499_OnOff "对应像素点的亮灭";
CM_ SG_ 1362 ICC_LISD_Pixel500_OnOff "对应像素点的亮灭";
CM_ SG_ 1362 ICC_LISD_Pixel501_OnOff "对应像素点的亮灭";
CM_ SG_ 1362 ICC_LISD_Pixel502_OnOff "对应像素点的亮灭";
CM_ SG_ 1362 ICC_LISD_Pixel503_OnOff "对应像素点的亮灭";
CM_ SG_ 1362 ICC_LISD_Pixel504_OnOff "对应像素点的亮灭";
BA_DEF_ BO_  "GenMsgCycleTimeFast" INT 0 50000;
BA_DEF_ BO_  "GenMsgNrOfRepetition" INT 0 999999;
BA_DEF_ BO_  "GenMsgDelayTime" INT 0 1000;
BA_DEF_ BO_  "VFrameFormat" ENUM  "StandardCAN","ExtendedCAN","reserved","reserved","reserved","reserved","reserved","reserved","reserved","reserved","reserved","reserved","reserved","reserved","StandardCAN_FD","ExtendedCAN_FD";
BA_DEF_ BO_  "GenMsgILSupport" ENUM  "No","Yes";
BA_DEF_ BO_  "NmMessage" ENUM  "No","Yes";
BA_DEF_ BO_  "DiagMessage" ENUM  "No","Yes";
BA_DEF_ BO_  "GenMsgSendType" ENUM  "Cyclic","Event","IfActive","CE","CA","NoMsgSendType";
BA_DEF_ BO_  "GenMsgCycleTime" INT 0 50000;
BA_DEF_ BO_  "CANFD_BRS" INT 0 1;
BA_DEF_ BO_  "NmAsrMessage" ENUM  "No","Yes";
BA_DEF_ BO_  "DiagState" ENUM  "No","Yes";
BA_DEF_ BO_  "DiagRequest" ENUM  "No","Yes";
BA_DEF_ BO_  "DiagResponse" ENUM  "No","Yes";
BA_DEF_ BO_  "MsgType" ENUM  "IL","NM","DIAG","APPL";
BA_DEF_ BO_  "Msg_ASIL" ENUM  "vector_leerstring","QM","A","B","C","D";
BA_DEF_ BO_  "GRC_History" STRING ;
BA_DEF_ SG_  "GenSigStartValue" FLOAT 0 100000000000;
BA_DEF_ SG_  "GenSigInactiveValue" INT 0 100000;
BA_DEF_ SG_  "GenSigInvalidValue" INT 0 100000;
BA_DEF_ SG_  "GenSigSendType" ENUM  "Cyclic","OnChange","OnWrite","IfActive","OnChangeWithRepetition","OnWriteWithRepetition","IfActiveWithRepetition","NoSigSendType","OnChangeAndIfActive","OnChangeAndIfActiveWithRepetition","CA","CE","Event";
BA_DEF_ SG_  "ASIL" ENUM  "vector_leerstring","QM","A","B","C","D";
BA_DEF_DEF_  "GenMsgCycleTimeFast" 0;
BA_DEF_DEF_  "GenMsgNrOfRepetition" 0;
BA_DEF_DEF_  "GenMsgDelayTime" 0;
BA_DEF_DEF_  "VFrameFormat" "StandardCAN";
BA_DEF_DEF_  "GenMsgILSupport" "No";
BA_DEF_DEF_  "NmMessage" "No";
BA_DEF_DEF_  "DiagMessage" "No";
BA_DEF_DEF_  "GenMsgSendType" "NoMsgSendType";
BA_DEF_DEF_  "GenMsgCycleTime" 0;
BA_DEF_DEF_  "CANFD_BRS" 0;
BA_DEF_DEF_  "NmAsrMessage" "No";
BA_DEF_DEF_  "DiagState" "No";
BA_DEF_DEF_  "DiagRequest" "No";
BA_DEF_DEF_  "DiagResponse" "No";
BA_DEF_DEF_  "MsgType" "";
BA_DEF_DEF_  "Msg_ASIL" "";
BA_DEF_DEF_  "GRC_History" "";
BA_DEF_DEF_  "GenSigStartValue" 0;
BA_DEF_DEF_  "GenSigInactiveValue" 0;
BA_DEF_DEF_  "GenSigInvalidValue" 0;
BA_DEF_DEF_  "GenSigSendType" "NoSigSendType";
BA_DEF_DEF_  "ASIL" "";
BA_ "GenMsgILSupport" BO_ 1238 1;
BA_ "MsgType" BO_ 1238 0;
BA_ "GenMsgDelayTime" BO_ 1238 5;
BA_ "GenMsgNrOfRepetition" BO_ 1238 3;
BA_ "GenMsgCycleTimeFast" BO_ 1238 50;
BA_ "GenMsgCycleTime" BO_ 1238 100;
BA_ "GenMsgSendType" BO_ 1238 3;
BA_ "CANFD_BRS" BO_ 1238 1;
BA_ "VFrameFormat" BO_ 1238 14;
BA_ "GenMsgILSupport" BO_ 1289 1;
BA_ "MsgType" BO_ 1289 0;
BA_ "GenMsgCycleTime" BO_ 1289 500;
BA_ "GenMsgSendType" BO_ 1289 0;
BA_ "CANFD_BRS" BO_ 1289 1;
BA_ "VFrameFormat" BO_ 1289 14;
BA_ "GRC_History" BO_ 1167 "[{'approvedBy':'贾少辉','author':'吴俊祥','changesComments':'1、新增ICC_RestoreDefaults_48Fh，用于恢复默认值-[智舱部 刘标 ]','date':'2026/1/8','ecu':'ICC_35（0x48F)','ecuName':'ICC,ICC_ICE','reviewedBy':'杨华','revision':'V1.4.1'},{'approvedBy':'贾少辉',";
BA_ "GenMsgILSupport" BO_ 1167 1;
BA_ "MsgType" BO_ 1167 0;
BA_ "GenMsgDelayTime" BO_ 1167 5;
BA_ "GenMsgNrOfRepetition" BO_ 1167 3;
BA_ "GenMsgCycleTimeFast" BO_ 1167 50;
BA_ "GenMsgSendType" BO_ 1167 1;
BA_ "CANFD_BRS" BO_ 1167 1;
BA_ "VFrameFormat" BO_ 1167 14;
BA_ "GenMsgILSupport" BO_ 1326 1;
BA_ "MsgType" BO_ 1326 0;
BA_ "GenMsgDelayTime" BO_ 1326 5;
BA_ "GenMsgNrOfRepetition" BO_ 1326 3;
BA_ "GenMsgCycleTimeFast" BO_ 1326 100;
BA_ "GenMsgSendType" BO_ 1326 1;
BA_ "CANFD_BRS" BO_ 1326 1;
BA_ "VFrameFormat" BO_ 1326 14;
BA_ "GRC_History" BO_ 1331 "[{'approvedBy':'贾少辉','author':'吴俊祥','changesComments':'1、同步T1J 华为增加Set_AMPLoudness、Set_AMPKeyVolume、Set_AMPExSoundmode、Set_AMPA2BENCSound信号','date':'2025/9/22','ecu':'ICC_IC_37(0x533）','ecuName':'ICC','reviewedBy':'杨华','revision':'V1";
BA_ "GenMsgILSupport" BO_ 1331 1;
BA_ "MsgType" BO_ 1331 0;
BA_ "GenMsgDelayTime" BO_ 1331 5;
BA_ "GenMsgNrOfRepetition" BO_ 1331 3;
BA_ "GenMsgCycleTimeFast" BO_ 1331 100;
BA_ "GenMsgSendType" BO_ 1331 1;
BA_ "CANFD_BRS" BO_ 1331 1;
BA_ "VFrameFormat" BO_ 1331 14;
BA_ "GRC_History" BO_ 1333 "[{'approvedBy':'贾少辉','author':'吴俊祥','changesComments':'电子电器丁阁文需求新增信号：FRZCU接收\n新增CSunshadeLearnedReq_535h、CSunshadePercentReq_535h 右域接收','date':'2025/12/24','ecu':'ICC_SRF_38(0x535)','ecuName':'ICC,ICC_ICE','reviewedBy':'杨华'";
BA_ "GenMsgILSupport" BO_ 1333 1;
BA_ "MsgType" BO_ 1333 0;
BA_ "GenMsgDelayTime" BO_ 1333 5;
BA_ "GenMsgNrOfRepetition" BO_ 1333 3;
BA_ "GenMsgCycleTimeFast" BO_ 1333 100;
BA_ "GenMsgSendType" BO_ 1333 1;
BA_ "CANFD_BRS" BO_ 1333 1;
BA_ "VFrameFormat" BO_ 1333 14;
BA_ "GRC_History" BO_ 1335 "[{'approvedBy':'贾少辉','author':'吴俊祥','changesComments':'同步D01\n程龙OA：JTPPSYB-QT-2025-72308\n1、删除DTATID：0x01E0和ICC_CH_39_0x537_E2E_P01_1，取消发送ICC_CH_39_CRC、ICC_CH_39_RollgCntr、ICC_CH_39_Resd1；','date':'2025/8/22','ecu':'ICC_CH_39(0x53";
BA_ "Msg_ASIL" BO_ 1335 2;
BA_ "GenMsgILSupport" BO_ 1335 1;
BA_ "MsgType" BO_ 1335 0;
BA_ "GenMsgDelayTime" BO_ 1335 5;
BA_ "GenMsgNrOfRepetition" BO_ 1335 3;
BA_ "GenMsgCycleTimeFast" BO_ 1335 20;
BA_ "GenMsgCycleTime" BO_ 1335 100;
BA_ "GenMsgSendType" BO_ 1335 3;
BA_ "CANFD_BRS" BO_ 1335 1;
BA_ "VFrameFormat" BO_ 1335 14;
BA_ "GRC_History" BO_ 1337 "[{'approvedBy':'贾少辉','author':'吴俊祥','changesComments':'T1J FL3 ICE新增EMS启停信号开关信号：\nICC_ISSFctCmd_539h新增——-[智舱部-姜新]','date':'2026/2/3','ecu':'ICC_TMS_40(0x539）','ecuName':'ICC_ICE','reviewedBy':'杨华','revision':'V1.5'}]";
BA_ "GenMsgILSupport" BO_ 1337 1;
BA_ "MsgType" BO_ 1337 0;
BA_ "GenMsgDelayTime" BO_ 1337 5;
BA_ "GenMsgNrOfRepetition" BO_ 1337 3;
BA_ "GenMsgCycleTimeFast" BO_ 1337 100;
BA_ "GenMsgSendType" BO_ 1337 1;
BA_ "CANFD_BRS" BO_ 1337 1;
BA_ "VFrameFormat" BO_ 1337 14;
BA_ "GRC_History" BO_ 1318 "[{'approvedBy':'贾少辉','author':'吴俊祥','changesComments':'氛围灯关联驾驶模式功能：\n新增ICC_TDLAssociatedDriverModeSw信号，用于TDL接收-[智舱部-刘标]','date':'2025/12/22','ecu':'ICC_TDL_41(0x526）','ecuName':'ICC,ICC_ICE','reviewedBy':'杨华','revision'";
BA_ "GenMsgILSupport" BO_ 1318 1;
BA_ "MsgType" BO_ 1318 0;
BA_ "GenMsgDelayTime" BO_ 1318 5;
BA_ "GenMsgNrOfRepetition" BO_ 1318 3;
BA_ "GenMsgCycleTimeFast" BO_ 1318 100;
BA_ "GenMsgCycleTime" BO_ 1318 100;
BA_ "GenMsgSendType" BO_ 1318 3;
BA_ "CANFD_BRS" BO_ 1318 1;
BA_ "VFrameFormat" BO_ 1318 14;
BA_ "GenMsgILSupport" BO_ 1320 1;
BA_ "MsgType" BO_ 1320 0;
BA_ "GenMsgDelayTime" BO_ 1320 5;
BA_ "GenMsgNrOfRepetition" BO_ 1320 3;
BA_ "GenMsgCycleTimeFast" BO_ 1320 100;
BA_ "GenMsgSendType" BO_ 1320 1;
BA_ "CANFD_BRS" BO_ 1320 1;
BA_ "VFrameFormat" BO_ 1320 14;
BA_ "GRC_History" BO_ 1360 "[{'approvedBy':'贾少辉','author':'吴俊祥','changesComments':'刘胤翠：\n删除信号ICC_RoofCampLampSetL、ICC_RoofCampLampSetR、ICC_TopLightSet、ICC_APillarYellowAmbientSet、ICC_APillarWhiteAmbientSet、ICC_APillarSpotLampSet','date':'2025/11/19','ecu':'ICC_LC";
BA_ "GenMsgILSupport" BO_ 1360 1;
BA_ "MsgType" BO_ 1360 0;
BA_ "GenMsgDelayTime" BO_ 1360 5;
BA_ "GenMsgNrOfRepetition" BO_ 1360 3;
BA_ "GenMsgCycleTimeFast" BO_ 1360 100;
BA_ "GenMsgCycleTime" BO_ 1360 100;
BA_ "GenMsgSendType" BO_ 1360 3;
BA_ "CANFD_BRS" BO_ 1360 1;
BA_ "VFrameFormat" BO_ 1360 14;
BA_ "GenMsgILSupport" BO_ 1362 1;
BA_ "MsgType" BO_ 1362 0;
BA_ "GenMsgDelayTime" BO_ 1362 5;
BA_ "GenMsgNrOfRepetition" BO_ 1362 3;
BA_ "GenMsgCycleTimeFast" BO_ 1362 100;
BA_ "GenMsgSendType" BO_ 1362 1;
BA_ "CANFD_BRS" BO_ 1362 1;
BA_ "VFrameFormat" BO_ 1362 14;
BA_ "GenSigSendType" SG_ 1238 ICC_CFSSwitch 5;
BA_ "GenSigSendType" SG_ 1238 ICC_CFSLevelSet 5;
BA_ "GenSigSendType" SG_ 1238 ICC_CFSPosSet 5;
BA_ "GenSigSendType" SG_ 1238 ICC_PM25Switch 5;
BA_ "GenSigSendType" SG_ 1238 ICC_AQSSwitch 5;
BA_ "GenSigStartValue" SG_ 1238 ICC_SecSetTemp_C 31;
BA_ "GenSigInvalidValue" SG_ 1238 ICC_SecSetTemp_C 31;
BA_ "GenSigSendType" SG_ 1238 ICC_SecSetTemp_C 5;
BA_ "GenSigSendType" SG_ 1238 ICC_SecFaceKeySts 5;
BA_ "GenSigSendType" SG_ 1238 ICC_SecFootKeySts 5;
BA_ "GenSigSendType" SG_ 1238 ICC_SecBlowSpeedLevelKeySts 5;
BA_ "GenSigSendType" SG_ 1238 ICC_SecAutoSwitch 5;
BA_ "GenSigSendType" SG_ 1238 ICC_SecCLMSwitch 5;
BA_ "GenSigStartValue" SG_ 1238 ICC_ThrSetTemp_C 31;
BA_ "GenSigInvalidValue" SG_ 1238 ICC_ThrSetTemp_C 31;
BA_ "GenSigSendType" SG_ 1238 ICC_ThrSetTemp_C 5;
BA_ "GenSigSendType" SG_ 1238 ICC_ThrFaceKeySts 5;
BA_ "GenSigSendType" SG_ 1238 ICC_ThrFootKeySts 5;
BA_ "GenSigSendType" SG_ 1238 ICC_ThrBlowSpeedLevelKeySts 5;
BA_ "GenSigSendType" SG_ 1238 ICC_ThrAutoSwitch 5;
BA_ "GenSigSendType" SG_ 1238 ICC_ThrCLMSwitch 5;
BA_ "GenSigSendType" SG_ 1238 ICC_ThrACRequestKeySts 5;
BA_ "GenSigSendType" SG_ 1238 ICC_DFMSwitch 5;
BA_ "GenSigSendType" SG_ 1289 ICC_TirePressureDisplayUnit 0;
BA_ "GenSigSendType" SG_ 1289 ICC_TireTemperatureDisplayUnit 0;
BA_ "GenSigSendType" SG_ 1289 ICC_ToggleUnits 0;
BA_ "GenSigSendType" SG_ 1289 ICC_BtConFlag 0;
BA_ "GenSigSendType" SG_ 1289 ICC_GPSSwitchSet 0;
BA_ "GenSigSendType" SG_ 1167 ICC_KeyDriveModememory 5;
BA_ "GenSigSendType" SG_ 1167 ICC_DriveModeSet 5;
BA_ "GenSigSendType" SG_ 1167 ICC_DRIFTModeSetReq 5;
BA_ "GenSigSendType" SG_ 1167 ICC_EXPERTEIPBESPSet 5;
BA_ "GenSigSendType" SG_ 1167 ICC_EXPERTEcoSet 5;
BA_ "GenSigSendType" SG_ 1167 ICC_EXPERTNormSet 5;
BA_ "GenSigSendType" SG_ 1167 ICC_EXPERTSportSet 5;
BA_ "GenSigSendType" SG_ 1167 ICC_CrossaxisSet 5;
BA_ "GenSigSendType" SG_ 1167 ICC_EXPERTRWDSet 5;
BA_ "GenSigSendType" SG_ 1167 ICC_EXPERTAWDSet 5;
BA_ "GenSigSendType" SG_ 1167 ICC_EXPERTAutoSet 5;
BA_ "GenSigSendType" SG_ 1167 ICC_CLIMBSet 5;
BA_ "GenSigSendType" SG_ 1167 ICC_DriveModeExitSet 5;
BA_ "GenSigSendType" SG_ 1167 ICC_CCOSwtReq 5;
BA_ "GenSigSendType" SG_ 1167 ICC_TABSwtReq 5;
BA_ "GenSigInvalidValue" SG_ 1167 ICC_Confidencelevel 127;
BA_ "GenSigSendType" SG_ 1167 ICC_Confidencelevel 5;
BA_ "GenSigSendType" SG_ 1167 ICC_V2L_IntlDisChg 5;
BA_ "GenSigSendType" SG_ 1167 ICC_ExhibitionModeSwitch 5;
BA_ "GenSigSendType" SG_ 1167 ICC_TrailerMode 5;
BA_ "GenSigSendType" SG_ 1167 ICC_V2L_DisChgMem 5;
BA_ "GenSigSendType" SG_ 1167 ICC_DrivePowerDispSet 5;
BA_ "GenSigSendType" SG_ 1167 ICC_WLTC_to_CLTC_Mode 5;
BA_ "GenSigSendType" SG_ 1167 ICC_StopChrgnSwitch 5;
BA_ "GenSigSendType" SG_ 1167 ICC_StopChrgnMode 5;
BA_ "GenSigSendType" SG_ 1167 ICC_RegenerateLevelCtrl 5;
BA_ "GenSigSendType" SG_ 1167 ICC_SinglePedalMem 5;
BA_ "GenSigSendType" SG_ 1167 ICC_FuelDetnSwt 5;
BA_ "GenSigSendType" SG_ 1167 ICC_FuelDetnState 5;
BA_ "GenSigSendType" SG_ 1167 ICC_FuelDetnOpDefeated 5;
BA_ "GenSigSendType" SG_ 1167 ICC_HVDownRepairMode 5;
BA_ "GenSigSendType" SG_ 1167 ICC_UTURNSnowSet 5;
BA_ "GenSigSendType" SG_ 1167 ICC_UTURNSandSet 5;
BA_ "GenSigSendType" SG_ 1167 ICC_UTURNMudSet 5;
BA_ "GenSigSendType" SG_ 1167 ICC_UTURNGrassSet 5;
BA_ "GenSigSendType" SG_ 1167 ICC_RestoreDefaults_48Fh 5;
BA_ "GenSigSendType" SG_ 1167 ICC_LTCDispSet2 5;
BA_ "GenSigSendType" SG_ 1167 ICC_SetSocManage 5;
BA_ "GenSigSendType" SG_ 1326 ICC_DWDOnOff_Req 5;
BA_ "GenSigSendType" SG_ 1326 ICC_ContainerLightSet 5;
BA_ "GenSigSendType" SG_ 1331 ICC_RLSeatEasyEntryExitSet 5;
BA_ "GenSigSendType" SG_ 1331 ICC_RRSeatEasyEntryExitSet 5;
BA_ "GenSigSendType" SG_ 1331 ICC_RLMemoryRecoveryCmd 5;
BA_ "GenSigSendType" SG_ 1331 ICC_RRMemoryRecoveryCmd 5;
BA_ "GenSigSendType" SG_ 1331 ICC_RLSitPosnlocation 5;
BA_ "GenSigSendType" SG_ 1331 ICC_RRSitPosnlocation 5;
BA_ "GenSigSendType" SG_ 1331 ICC_CMSMDisplaySwitch 5;
BA_ "GenSigSendType" SG_ 1331 ICC_CMSMDisplayAdjustmode 5;
BA_ "GenSigSendType" SG_ 1331 ICC_CMSMSetstandardSwitch 5;
BA_ "GenSigStartValue" SG_ 1331 ICC_LeftPedalControl 3;
BA_ "GenSigSendType" SG_ 1331 ICC_LeftPedalControl 5;
BA_ "GenSigStartValue" SG_ 1331 ICC_RightPedalControl 3;
BA_ "GenSigSendType" SG_ 1331 ICC_RightPedalControl 5;
BA_ "GenSigSendType" SG_ 1331 ICC_EPCEnable 5;
BA_ "GenSigSendType" SG_ 1331 ICC_AMPKTVvoiceVolumeSet 5;
BA_ "GenSigSendType" SG_ 1331 ICC_AMPA2BENCSoundReq 5;
BA_ "GenSigSendType" SG_ 1331 ICC_AMPENCVolumeSet 5;
BA_ "GenSigSendType" SG_ 1331 ICC_AMPA2BChimeSoundReq 5;
BA_ "GenSigSendType" SG_ 1331 Set_AMPSoundFocus_2 5;
BA_ "GenSigSendType" SG_ 1331 ICC_AMPA2BKTVvoiceSoundReq 5;
BA_ "GenSigSendType" SG_ 1331 ICC_MedStatusSet 5;
BA_ "GenSigSendType" SG_ 1331 Set_AMPLoudness 5;
BA_ "GenSigSendType" SG_ 1331 ICC_MedAreaSet 5;
BA_ "GenSigSendType" SG_ 1331 ICC_LeftElectricPedalsSet 5;
BA_ "GenSigSendType" SG_ 1331 ICC_RightElectricPedalsSet 5;
BA_ "GenSigSendType" SG_ 1331 ICC_NapAreaSet2 5;
BA_ "GenSigInvalidValue" SG_ 1331 ICC_DisplayAdjustrAngReq 255;
BA_ "GenSigSendType" SG_ 1331 ICC_DisplayAdjustrAngReq 5;
BA_ "GenSigSendType" SG_ 1331 Set_AMPKeyVolume 5;
BA_ "GenSigSendType" SG_ 1331 ICC_CMSMTouchSts 5;
BA_ "GenSigSendType" SG_ 1331 Set_AMPExSoundmode 5;
BA_ "GenSigSendType" SG_ 1331 Set_AMPA2BENCSound 5;
BA_ "GenSigSendType" SG_ 1333 ICC_SRFCmd 5;
BA_ "GenSigSendType" SG_ 1333 ICC_SRFPercentCmd 5;
BA_ "GenSigSendType" SG_ 1333 ICC_CSunshadeReq 5;
BA_ "GenSigSendType" SG_ 1333 ICC_CSunshadePercentReq 5;
BA_ "GenSigSendType" SG_ 1333 ICC_SunshadeCmd 5;
BA_ "GenSigSendType" SG_ 1333 ICC_SunshadePercentCmd 5;
BA_ "GenSigSendType" SG_ 1333 CSunshadeLearnedReq_535h 5;
BA_ "GenSigSendType" SG_ 1333 CSunshadePercentReq_535h 5;
BA_ "GenSigSendType" SG_ 1335 ICC_SET_EPS_SteerReturnRmdSts 5;
BA_ "GenSigSendType" SG_ 1335 ICC_SET_MFSShake 5;
BA_ "GenSigSendType" SG_ 1335 ICC_DMS_1_DistractionLevel 5;
BA_ "GenSigSendType" SG_ 1335 ICC_SET_EPS_AsociWithDrvModSts 5;
BA_ "GenSigSendType" SG_ 1335 ICC_OverLoadWarnShieldSet 5;
BA_ "GenSigSendType" SG_ 1335 ICC_BSWReq 5;
BA_ "GenSigSendType" SG_ 1335 ICC_horizontalReq 5;
BA_ "GenSigSendType" SG_ 1335 ICC_RolloverSetCmd 5;
BA_ "ASIL" SG_ 1335 ICC_RolloverSetCmd 2;
BA_ "GenSigSendType" SG_ 1335 ICC_TrekThroughReq_537h 5;
BA_ "GenSigSendType" SG_ 1335 ICC_InflateReq_537h 5;
BA_ "GenSigSendType" SG_ 1335 ICC_UndergroundModeReq_537h 5;
BA_ "GenSigSendType" SG_ 1337 ICC_SET_BT_ReduceWindSpeed 5;
BA_ "GenSigSendType" SG_ 1337 ICC_SET_IPM_FirstBlowing 5;
BA_ "GenSigSendType" SG_ 1337 ICC_SET_IPM_BlowerDelay 5;
BA_ "GenSigSendType" SG_ 1337 ICC_SET_CirculationInTunnels 5;
BA_ "GenSigSendType" SG_ 1337 ICC_UVCLuminanceReq 5;
BA_ "GenSigSendType" SG_ 1337 ICC_UVCControlReq 5;
BA_ "GenSigSendType" SG_ 1337 ICC_CrossCountryCoolingReq 5;
BA_ "GenSigSendType" SG_ 1337 ICC_KeepWarmReq 5;
BA_ "GenSigSendType" SG_ 1337 ICC_keepwarmSetTemperatureReq 5;
BA_ "GenSigSendType" SG_ 1337 ICC_ParkingAirConditioning 5;
BA_ "GenSigSendType" SG_ 1337 ICC_CoolantFill_Req 5;
BA_ "GenSigSendType" SG_ 1337 ICC_FraganceLightoffReq 5;
BA_ "GenSigSendType" SG_ 1337 ICC_FraganceMemoffReq 5;
BA_ "GenSigSendType" SG_ 1337 ICC_CFSCycleLevel 5;
BA_ "GenSigSendType" SG_ 1337 ICC_TimingLevel 5;
BA_ "GenSigStartValue" SG_ 1337 ICC_ModeAdjustDisplaySts 5;
BA_ "GenSigSendType" SG_ 1337 ICC_ModeAdjustDisplaySts 5;
BA_ "GenSigSendType" SG_ 1337 ICC_AirPurgeReminderReq 5;
BA_ "GenSigSendType" SG_ 1337 ICC_BiochemicalFuncReq 5;
BA_ "GenSigSendType" SG_ 1337 ICC_TimedVentilationReq 5;
BA_ "GenSigStartValue" SG_ 1337 ICC_PetmodeSetTemperature_L_C 31;
BA_ "GenSigInvalidValue" SG_ 1337 ICC_PetmodeSetTemperature_L_C 31;
BA_ "GenSigSendType" SG_ 1337 ICC_PetmodeSetTemperature_L_C 5;
BA_ "GenSigStartValue" SG_ 1337 ICC_PetModeSetTemperature_R_C 31;
BA_ "GenSigInvalidValue" SG_ 1337 ICC_PetModeSetTemperature_R_C 31;
BA_ "GenSigSendType" SG_ 1337 ICC_PetModeSetTemperature_R_C 5;
BA_ "GenSigSendType" SG_ 1337 ICC_PetModeSetCLMOn 5;
BA_ "GenSigSendType" SG_ 1337 ICC_PetModeSetAutoKeySts 5;
BA_ "GenSigSendType" SG_ 1337 ICC_PetModeSetCirculationSts 5;
BA_ "GenSigSendType" SG_ 1337 ICC_ISSFctCmd_539h 5;
BA_ "GenSigSendType" SG_ 1318 ICC_SET_TDL_Rhythm_Switch 5;
BA_ "GenSigSendType" SG_ 1318 ICC_SET_TDL_Switch 5;
BA_ "GenSigSendType" SG_ 1318 ICC_SET_TDL_ColourModeAdj 5;
BA_ "GenSigSendType" SG_ 1318 ICC_VoiceWake 5;
BA_ "GenSigSendType" SG_ 1318 ICC_TDLAssociatedDriverModeSw 5;
BA_ "GenSigSendType" SG_ 1318 ICC_TDL_RhythmReq 5;
BA_ "GenSigSendType" SG_ 1318 ICC_SET_ApiluminanceAdj 5;
BA_ "GenSigStartValue" SG_ 1318 ICC_SET_MusicLoudness_120HZ 15;
BA_ "GenSigSendType" SG_ 1318 ICC_SET_MusicLoudness_120HZ 0;
BA_ "GenSigStartValue" SG_ 1318 ICC_SET_MusicLoudness_250HZ 15;
BA_ "GenSigSendType" SG_ 1318 ICC_SET_MusicLoudness_250HZ 0;
BA_ "GenSigStartValue" SG_ 1318 ICC_SET_MusicLoudness_500HZ 15;
BA_ "GenSigSendType" SG_ 1318 ICC_SET_MusicLoudness_500HZ 0;
BA_ "GenSigStartValue" SG_ 1318 ICC_SET_MusicLoudness_1000HZ 15;
BA_ "GenSigSendType" SG_ 1318 ICC_SET_MusicLoudness_1000HZ 0;
BA_ "GenSigStartValue" SG_ 1318 ICC_SET_MusicLoudness_1500HZ 15;
BA_ "GenSigSendType" SG_ 1318 ICC_SET_MusicLoudness_1500HZ 0;
BA_ "GenSigStartValue" SG_ 1318 ICC_SET_MusicLoudness_2000HZ 15;
BA_ "GenSigSendType" SG_ 1318 ICC_SET_MusicLoudness_2000HZ 0;
BA_ "GenSigStartValue" SG_ 1318 ICC_SET_MusicLoudness_6000HZ 15;
BA_ "GenSigSendType" SG_ 1318 ICC_SET_MusicLoudness_6000HZ 0;
BA_ "GenSigSendType" SG_ 1318 ICC_TDL_FlowLightSw 5;
BA_ "GenSigSendType" SG_ 1318 ICC_TDL_FlowLightModeAdj 5;
BA_ "GenSigStartValue" SG_ 1318 ICC_SET_256ColourAdj 127;
BA_ "GenSigInvalidValue" SG_ 1318 ICC_SET_256ColourAdj 127;
BA_ "GenSigSendType" SG_ 1318 ICC_SET_256ColourAdj 5;
BA_ "GenSigSendType" SG_ 1320 ICC_Chb_Req 5;
BA_ "GenSigSendType" SG_ 1320 ICC_ChbMem_Req 5;
BA_ "GenSigSendType" SG_ 1320 ICC_ChbDelay_Req 5;
BA_ "GenSigSendType" SG_ 1320 ICC_ChbSterilization_Req 5;
BA_ "GenSigSendType" SG_ 1320 ICC_ChbItemsLeft_Req 5;
BA_ "GenSigSendType" SG_ 1320 ICC_ParkingRadarSwSet 5;
BA_ "GenSigInvalidValue" SG_ 1320 ICC_ChbTimeset_Req 31;
BA_ "GenSigSendType" SG_ 1320 ICC_ChbTimeset_Req 5;
BA_ "GenSigSendType" SG_ 1320 ICC_ChbCoolset_Req 5;
BA_ "GenSigSendType" SG_ 1320 ICC_ChbCoolorheat_Req 5;
BA_ "GenSigSendType" SG_ 1320 ICC_ChbHeatset_Req 5;
BA_ "GenSigSendType" SG_ 1360 ICC_LISD_DisplaySwitch 5;
BA_ "GenSigSendType" SG_ 1360 ICC_LISD_ParkingShowCMD 5;
BA_ "GenSigSendType" SG_ 1360 ICC_RISD_DisplaySwitch 5;
BA_ "GenSigSendType" SG_ 1360 ICC_RISD_ParkingShowCMD 5;
BA_ "GenSigSendType" SG_ 1360 ICC_LogoParkingReq 5;
BA_ "GenSigSendType" SG_ 1360 ICC_LogoChargingReq 5;
BA_ "GenSigSendType" SG_ 1360 ICC_DRLSw 5;
BA_ "GenSigSendType" SG_ 1360 ICC_LISD_ParkingShowMod 5;
BA_ "GenSigSendType" SG_ 1360 ICC_RISD_ParkingShowMod 5;
BA_ "GenSigSendType" SG_ 1360 ICC_PenetrationLampSetF 5;
BA_ "GenSigSendType" SG_ 1360 ICC_MusicLampShowSW 5;
BA_ "GenSigSendType" SG_ 1360 ICC_LogoColorReq 5;
BA_ "GenSigSendType" SG_ 1360 ICC_XDriveMode 0;
BA_ "GenSigSendType" SG_ 1360 ICC_DowWaringSw 5;
BA_ "GenSigSendType" SG_ 1360 ICC_CarSearhSetSwitchSts 5;
BA_ "GenSigSendType" SG_ 1362 ICC_LISD_FrameCounter 5;
BA_ "GenSigSendType" SG_ 1362 ICC_LISD_RollingCounter 5;
BA_ "GenSigSendType" SG_ 1362 ICC_LISD_Pixel1_OnOff 5;
BA_ "GenSigSendType" SG_ 1362 ICC_LISD_Pixel2_OnOff 5;
BA_ "GenSigSendType" SG_ 1362 ICC_LISD_Pixel3_OnOff 5;
BA_ "GenSigSendType" SG_ 1362 ICC_LISD_Pixel4_OnOff 5;
BA_ "GenSigSendType" SG_ 1362 ICC_LISD_Pixel5_OnOff 5;
BA_ "GenSigSendType" SG_ 1362 ICC_LISD_Pixel6_OnOff 5;
BA_ "GenSigSendType" SG_ 1362 ICC_LISD_Pixel7_OnOff 5;
BA_ "GenSigSendType" SG_ 1362 ICC_LISD_Pixel8_OnOff 5;
BA_ "GenSigSendType" SG_ 1362 ICC_LISD_Pixel9_OnOff 5;
BA_ "GenSigSendType" SG_ 1362 ICC_LISD_Pixel10_OnOff 5;
BA_ "GenSigSendType" SG_ 1362 ICC_LISD_Pixel11_OnOff 5;
BA_ "GenSigSendType" SG_ 1362 ICC_LISD_Pixel12_OnOff 5;
BA_ "GenSigSendType" SG_ 1362 ICC_LISD_Pixel13_OnOff 5;
BA_ "GenSigSendType" SG_ 1362 ICC_LISD_Pixel14_OnOff 5;
BA_ "GenSigSendType" SG_ 1362 ICC_LISD_Pixel15_OnOff 5;
BA_ "GenSigSendType" SG_ 1362 ICC_LISD_Pixel16_OnOff 5;
BA_ "GenSigSendType" SG_ 1362 ICC_LISD_Pixel17_OnOff 5;
BA_ "GenSigSendType" SG_ 1362 ICC_LISD_Pixel18_OnOff 5;
BA_ "GenSigSendType" SG_ 1362 ICC_LISD_Pixel19_OnOff 5;
BA_ "GenSigSendType" SG_ 1362 ICC_LISD_Pixel20_OnOff 5;
BA_ "GenSigSendType" SG_ 1362 ICC_LISD_Pixel21_OnOff 5;
BA_ "GenSigSendType" SG_ 1362 ICC_LISD_Pixel22_OnOff 5;
BA_ "GenSigSendType" SG_ 1362 ICC_LISD_Pixel23_OnOff 5;
BA_ "GenSigSendType" SG_ 1362 ICC_LISD_Pixel24_OnOff 5;
BA_ "GenSigSendType" SG_ 1362 ICC_LISD_Pixel25_OnOff 5;
BA_ "GenSigSendType" SG_ 1362 ICC_LISD_Pixel26_OnOff 5;
BA_ "GenSigSendType" SG_ 1362 ICC_LISD_Pixel27_OnOff 5;
BA_ "GenSigSendType" SG_ 1362 ICC_LISD_Pixel28_OnOff 5;
BA_ "GenSigSendType" SG_ 1362 ICC_LISD_Pixel29_OnOff 5;
BA_ "GenSigSendType" SG_ 1362 ICC_LISD_Pixel30_OnOff 5;
BA_ "GenSigSendType" SG_ 1362 ICC_LISD_Pixel31_OnOff 5;
BA_ "GenSigSendType" SG_ 1362 ICC_LISD_Pixel32_OnOff 5;
BA_ "GenSigSendType" SG_ 1362 ICC_LISD_Pixel33_OnOff 5;
BA_ "GenSigSendType" SG_ 1362 ICC_LISD_Pixel34_OnOff 5;
BA_ "GenSigSendType" SG_ 1362 ICC_LISD_Pixel35_OnOff 5;
BA_ "GenSigSendType" SG_ 1362 ICC_LISD_Pixel36_OnOff 5;
BA_ "GenSigSendType" SG_ 1362 ICC_LISD_Pixel37_OnOff 5;
BA_ "GenSigSendType" SG_ 1362 ICC_LISD_Pixel38_OnOff 5;
BA_ "GenSigSendType" SG_ 1362 ICC_LISD_Pixel39_OnOff 5;
BA_ "GenSigSendType" SG_ 1362 ICC_LISD_Pixel40_OnOff 5;
BA_ "GenSigSendType" SG_ 1362 ICC_LISD_Pixel41_OnOff 5;
BA_ "GenSigSendType" SG_ 1362 ICC_LISD_Pixel42_OnOff 5;
BA_ "GenSigSendType" SG_ 1362 ICC_LISD_Pixel43_OnOff 5;
BA_ "GenSigSendType" SG_ 1362 ICC_LISD_Pixel44_OnOff 5;
BA_ "GenSigSendType" SG_ 1362 ICC_LISD_Pixel45_OnOff 5;
BA_ "GenSigSendType" SG_ 1362 ICC_LISD_Pixel46_OnOff 5;
BA_ "GenSigSendType" SG_ 1362 ICC_LISD_Pixel47_OnOff 5;
BA_ "GenSigSendType" SG_ 1362 ICC_LISD_Pixel48_OnOff 5;
BA_ "GenSigSendType" SG_ 1362 ICC_LISD_Pixel49_OnOff 5;
BA_ "GenSigSendType" SG_ 1362 ICC_LISD_Pixel50_OnOff 5;
BA_ "GenSigSendType" SG_ 1362 ICC_LISD_Pixel51_OnOff 5;
BA_ "GenSigSendType" SG_ 1362 ICC_LISD_Pixel52_OnOff 5;
BA_ "GenSigSendType" SG_ 1362 ICC_LISD_Pixel53_OnOff 5;
BA_ "GenSigSendType" SG_ 1362 ICC_LISD_Pixel54_OnOff 5;
BA_ "GenSigSendType" SG_ 1362 ICC_LISD_Pixel55_OnOff 5;
BA_ "GenSigSendType" SG_ 1362 ICC_LISD_Pixel56_OnOff 5;
BA_ "GenSigSendType" SG_ 1362 ICC_LISD_Pixel57_OnOff 5;
BA_ "GenSigSendType" SG_ 1362 ICC_LISD_Pixel58_OnOff 5;
BA_ "GenSigSendType" SG_ 1362 ICC_LISD_Pixel59_OnOff 5;
BA_ "GenSigSendType" SG_ 1362 ICC_LISD_Pixel60_OnOff 5;
BA_ "GenSigSendType" SG_ 1362 ICC_LISD_Pixel61_OnOff 5;
BA_ "GenSigSendType" SG_ 1362 ICC_LISD_Pixel62_OnOff 5;
BA_ "GenSigSendType" SG_ 1362 ICC_LISD_Pixel63_OnOff 5;
BA_ "GenSigSendType" SG_ 1362 ICC_LISD_Pixel64_OnOff 5;
BA_ "GenSigSendType" SG_ 1362 ICC_LISD_Pixel65_OnOff 5;
BA_ "GenSigSendType" SG_ 1362 ICC_LISD_Pixel66_OnOff 5;
BA_ "GenSigSendType" SG_ 1362 ICC_LISD_Pixel67_OnOff 5;
BA_ "GenSigSendType" SG_ 1362 ICC_LISD_Pixel68_OnOff 5;
BA_ "GenSigSendType" SG_ 1362 ICC_LISD_Pixel69_OnOff 5;
BA_ "GenSigSendType" SG_ 1362 ICC_LISD_Pixel70_OnOff 5;
BA_ "GenSigSendType" SG_ 1362 ICC_LISD_Pixel71_OnOff 5;
BA_ "GenSigSendType" SG_ 1362 ICC_LISD_Pixel72_OnOff 5;
BA_ "GenSigSendType" SG_ 1362 ICC_LISD_Pixel73_OnOff 5;
BA_ "GenSigSendType" SG_ 1362 ICC_LISD_Pixel74_OnOff 5;
BA_ "GenSigSendType" SG_ 1362 ICC_LISD_Pixel75_OnOff 5;
BA_ "GenSigSendType" SG_ 1362 ICC_LISD_Pixel76_OnOff 5;
BA_ "GenSigSendType" SG_ 1362 ICC_LISD_Pixel77_OnOff 5;
BA_ "GenSigSendType" SG_ 1362 ICC_LISD_Pixel78_OnOff 5;
BA_ "GenSigSendType" SG_ 1362 ICC_LISD_Pixel79_OnOff 5;
BA_ "GenSigSendType" SG_ 1362 ICC_LISD_Pixel80_OnOff 5;
BA_ "GenSigSendType" SG_ 1362 ICC_LISD_Pixel81_OnOff 5;
BA_ "GenSigSendType" SG_ 1362 ICC_LISD_Pixel82_OnOff 5;
BA_ "GenSigSendType" SG_ 1362 ICC_LISD_Pixel83_OnOff 5;
BA_ "GenSigSendType" SG_ 1362 ICC_LISD_Pixel84_OnOff 5;
BA_ "GenSigSendType" SG_ 1362 ICC_LISD_Pixel85_OnOff 5;
BA_ "GenSigSendType" SG_ 1362 ICC_LISD_Pixel86_OnOff 5;
BA_ "GenSigSendType" SG_ 1362 ICC_LISD_Pixel87_OnOff 5;
BA_ "GenSigSendType" SG_ 1362 ICC_LISD_Pixel88_OnOff 5;
BA_ "GenSigSendType" SG_ 1362 ICC_LISD_Pixel89_OnOff 5;
BA_ "GenSigSendType" SG_ 1362 ICC_LISD_Pixel90_OnOff 5;
BA_ "GenSigSendType" SG_ 1362 ICC_LISD_Pixel91_OnOff 5;
BA_ "GenSigSendType" SG_ 1362 ICC_LISD_Pixel92_OnOff 5;
BA_ "GenSigSendType" SG_ 1362 ICC_LISD_Pixel93_OnOff 5;
BA_ "GenSigSendType" SG_ 1362 ICC_LISD_Pixel94_OnOff 5;
BA_ "GenSigSendType" SG_ 1362 ICC_LISD_Pixel95_OnOff 5;
BA_ "GenSigSendType" SG_ 1362 ICC_LISD_Pixel96_OnOff 5;
BA_ "GenSigSendType" SG_ 1362 ICC_LISD_Pixel97_OnOff 5;
BA_ "GenSigSendType" SG_ 1362 ICC_LISD_Pixel98_OnOff 5;
BA_ "GenSigSendType" SG_ 1362 ICC_LISD_Pixel99_OnOff 5;
BA_ "GenSigSendType" SG_ 1362 ICC_LISD_Pixel100_OnOff 5;
BA_ "GenSigSendType" SG_ 1362 ICC_LISD_Pixel101_OnOff 5;
BA_ "GenSigSendType" SG_ 1362 ICC_LISD_Pixel102_OnOff 5;
BA_ "GenSigSendType" SG_ 1362 ICC_LISD_Pixel103_OnOff 5;
BA_ "GenSigSendType" SG_ 1362 ICC_LISD_Pixel104_OnOff 5;
BA_ "GenSigSendType" SG_ 1362 ICC_LISD_Pixel105_OnOff 5;
BA_ "GenSigSendType" SG_ 1362 ICC_LISD_Pixel106_OnOff 5;
BA_ "GenSigSendType" SG_ 1362 ICC_LISD_Pixel107_OnOff 5;
BA_ "GenSigSendType" SG_ 1362 ICC_LISD_Pixel108_OnOff 5;
BA_ "GenSigSendType" SG_ 1362 ICC_LISD_Pixel109_OnOff 5;
BA_ "GenSigSendType" SG_ 1362 ICC_LISD_Pixel110_OnOff 5;
BA_ "GenSigSendType" SG_ 1362 ICC_LISD_Pixel111_OnOff 5;
BA_ "GenSigSendType" SG_ 1362 ICC_LISD_Pixel112_OnOff 5;
BA_ "GenSigSendType" SG_ 1362 ICC_LISD_Pixel113_OnOff 5;
BA_ "GenSigSendType" SG_ 1362 ICC_LISD_Pixel114_OnOff 5;
BA_ "GenSigSendType" SG_ 1362 ICC_LISD_Pixel115_OnOff 5;
BA_ "GenSigSendType" SG_ 1362 ICC_LISD_Pixel116_OnOff 5;
BA_ "GenSigSendType" SG_ 1362 ICC_LISD_Pixel117_OnOff 5;
BA_ "GenSigSendType" SG_ 1362 ICC_LISD_Pixel118_OnOff 5;
BA_ "GenSigSendType" SG_ 1362 ICC_LISD_Pixel119_OnOff 5;
BA_ "GenSigSendType" SG_ 1362 ICC_LISD_Pixel120_OnOff 5;
BA_ "GenSigSendType" SG_ 1362 ICC_LISD_Pixel121_OnOff 5;
BA_ "GenSigSendType" SG_ 1362 ICC_LISD_Pixel122_OnOff 5;
BA_ "GenSigSendType" SG_ 1362 ICC_LISD_Pixel123_OnOff 5;
BA_ "GenSigSendType" SG_ 1362 ICC_LISD_Pixel124_OnOff 5;
BA_ "GenSigSendType" SG_ 1362 ICC_LISD_Pixel125_OnOff 5;
BA_ "GenSigSendType" SG_ 1362 ICC_LISD_Pixel126_OnOff 5;
BA_ "GenSigSendType" SG_ 1362 ICC_LISD_Pixel127_OnOff 5;
BA_ "GenSigSendType" SG_ 1362 ICC_LISD_Pixel128_OnOff 5;
BA_ "GenSigSendType" SG_ 1362 ICC_LISD_Pixel129_OnOff 5;
BA_ "GenSigSendType" SG_ 1362 ICC_LISD_Pixel130_OnOff 5;
BA_ "GenSigSendType" SG_ 1362 ICC_LISD_Pixel131_OnOff 5;
BA_ "GenSigSendType" SG_ 1362 ICC_LISD_Pixel132_OnOff 5;
BA_ "GenSigSendType" SG_ 1362 ICC_LISD_Pixel133_OnOff 5;
BA_ "GenSigSendType" SG_ 1362 ICC_LISD_Pixel134_OnOff 5;
BA_ "GenSigSendType" SG_ 1362 ICC_LISD_Pixel135_OnOff 5;
BA_ "GenSigSendType" SG_ 1362 ICC_LISD_Pixel136_OnOff 5;
BA_ "GenSigSendType" SG_ 1362 ICC_LISD_Pixel137_OnOff 5;
BA_ "GenSigSendType" SG_ 1362 ICC_LISD_Pixel138_OnOff 5;
BA_ "GenSigSendType" SG_ 1362 ICC_LISD_Pixel139_OnOff 5;
BA_ "GenSigSendType" SG_ 1362 ICC_LISD_Pixel140_OnOff 5;
BA_ "GenSigSendType" SG_ 1362 ICC_LISD_Pixel141_OnOff 5;
BA_ "GenSigSendType" SG_ 1362 ICC_LISD_Pixel142_OnOff 5;
BA_ "GenSigSendType" SG_ 1362 ICC_LISD_Pixel143_OnOff 5;
BA_ "GenSigSendType" SG_ 1362 ICC_LISD_Pixel144_OnOff 5;
BA_ "GenSigSendType" SG_ 1362 ICC_LISD_Pixel145_OnOff 5;
BA_ "GenSigSendType" SG_ 1362 ICC_LISD_Pixel146_OnOff 5;
BA_ "GenSigSendType" SG_ 1362 ICC_LISD_Pixel147_OnOff 5;
BA_ "GenSigSendType" SG_ 1362 ICC_LISD_Pixel148_OnOff 5;
BA_ "GenSigSendType" SG_ 1362 ICC_LISD_Pixel149_OnOff 5;
BA_ "GenSigSendType" SG_ 1362 ICC_LISD_Pixel150_OnOff 5;
BA_ "GenSigSendType" SG_ 1362 ICC_LISD_Pixel151_OnOff 5;
BA_ "GenSigSendType" SG_ 1362 ICC_LISD_Pixel152_OnOff 5;
BA_ "GenSigSendType" SG_ 1362 ICC_LISD_Pixel153_OnOff 5;
BA_ "GenSigSendType" SG_ 1362 ICC_LISD_Pixel154_OnOff 5;
BA_ "GenSigSendType" SG_ 1362 ICC_LISD_Pixel155_OnOff 5;
BA_ "GenSigSendType" SG_ 1362 ICC_LISD_Pixel156_OnOff 5;
BA_ "GenSigSendType" SG_ 1362 ICC_LISD_Pixel157_OnOff 5;
BA_ "GenSigSendType" SG_ 1362 ICC_LISD_Pixel158_OnOff 5;
BA_ "GenSigSendType" SG_ 1362 ICC_LISD_Pixel159_OnOff 5;
BA_ "GenSigSendType" SG_ 1362 ICC_LISD_Pixel160_OnOff 5;
BA_ "GenSigSendType" SG_ 1362 ICC_LISD_Pixel161_OnOff 5;
BA_ "GenSigSendType" SG_ 1362 ICC_LISD_Pixel162_OnOff 5;
BA_ "GenSigSendType" SG_ 1362 ICC_LISD_Pixel163_OnOff 5;
BA_ "GenSigSendType" SG_ 1362 ICC_LISD_Pixel164_OnOff 5;
BA_ "GenSigSendType" SG_ 1362 ICC_LISD_Pixel165_OnOff 5;
BA_ "GenSigSendType" SG_ 1362 ICC_LISD_Pixel166_OnOff 5;
BA_ "GenSigSendType" SG_ 1362 ICC_LISD_Pixel167_OnOff 5;
BA_ "GenSigSendType" SG_ 1362 ICC_LISD_Pixel168_OnOff 5;
BA_ "GenSigSendType" SG_ 1362 ICC_LISD_Pixel169_OnOff 5;
BA_ "GenSigSendType" SG_ 1362 ICC_LISD_Pixel170_OnOff 5;
BA_ "GenSigSendType" SG_ 1362 ICC_LISD_Pixel171_OnOff 5;
BA_ "GenSigSendType" SG_ 1362 ICC_LISD_Pixel172_OnOff 5;
BA_ "GenSigSendType" SG_ 1362 ICC_LISD_Pixel173_OnOff 5;
BA_ "GenSigSendType" SG_ 1362 ICC_LISD_Pixel174_OnOff 5;
BA_ "GenSigSendType" SG_ 1362 ICC_LISD_Pixel175_OnOff 5;
BA_ "GenSigSendType" SG_ 1362 ICC_LISD_Pixel176_OnOff 5;
BA_ "GenSigSendType" SG_ 1362 ICC_LISD_Pixel177_OnOff 5;
BA_ "GenSigSendType" SG_ 1362 ICC_LISD_Pixel178_OnOff 5;
BA_ "GenSigSendType" SG_ 1362 ICC_LISD_Pixel179_OnOff 5;
BA_ "GenSigSendType" SG_ 1362 ICC_LISD_Pixel180_OnOff 5;
BA_ "GenSigSendType" SG_ 1362 ICC_LISD_Pixel181_OnOff 5;
BA_ "GenSigSendType" SG_ 1362 ICC_LISD_Pixel182_OnOff 5;
BA_ "GenSigSendType" SG_ 1362 ICC_LISD_Pixel183_OnOff 5;
BA_ "GenSigSendType" SG_ 1362 ICC_LISD_Pixel184_OnOff 5;
BA_ "GenSigSendType" SG_ 1362 ICC_LISD_Pixel185_OnOff 5;
BA_ "GenSigSendType" SG_ 1362 ICC_LISD_Pixel186_OnOff 5;
BA_ "GenSigSendType" SG_ 1362 ICC_LISD_Pixel187_OnOff 5;
BA_ "GenSigSendType" SG_ 1362 ICC_LISD_Pixel188_OnOff 5;
BA_ "GenSigSendType" SG_ 1362 ICC_LISD_Pixel189_OnOff 5;
BA_ "GenSigSendType" SG_ 1362 ICC_LISD_Pixel190_OnOff 5;
BA_ "GenSigSendType" SG_ 1362 ICC_LISD_Pixel191_OnOff 5;
BA_ "GenSigSendType" SG_ 1362 ICC_LISD_Pixel192_OnOff 5;
BA_ "GenSigSendType" SG_ 1362 ICC_LISD_Pixel193_OnOff 5;
BA_ "GenSigSendType" SG_ 1362 ICC_LISD_Pixel194_OnOff 5;
BA_ "GenSigSendType" SG_ 1362 ICC_LISD_Pixel195_OnOff 5;
BA_ "GenSigSendType" SG_ 1362 ICC_LISD_Pixel196_OnOff 5;
BA_ "GenSigSendType" SG_ 1362 ICC_LISD_Pixel197_OnOff 5;
BA_ "GenSigSendType" SG_ 1362 ICC_LISD_Pixel198_OnOff 5;
BA_ "GenSigSendType" SG_ 1362 ICC_LISD_Pixel199_OnOff 5;
BA_ "GenSigSendType" SG_ 1362 ICC_LISD_Pixel200_OnOff 5;
BA_ "GenSigSendType" SG_ 1362 ICC_LISD_Pixel201_OnOff 5;
BA_ "GenSigSendType" SG_ 1362 ICC_LISD_Pixel202_OnOff 5;
BA_ "GenSigSendType" SG_ 1362 ICC_LISD_Pixel203_OnOff 5;
BA_ "GenSigSendType" SG_ 1362 ICC_LISD_Pixel204_OnOff 5;
BA_ "GenSigSendType" SG_ 1362 ICC_LISD_Pixel205_OnOff 5;
BA_ "GenSigSendType" SG_ 1362 ICC_LISD_Pixel206_OnOff 5;
BA_ "GenSigSendType" SG_ 1362 ICC_LISD_Pixel207_OnOff 5;
BA_ "GenSigSendType" SG_ 1362 ICC_LISD_Pixel208_OnOff 5;
BA_ "GenSigSendType" SG_ 1362 ICC_LISD_Pixel209_OnOff 5;
BA_ "GenSigSendType" SG_ 1362 ICC_LISD_Pixel210_OnOff 5;
BA_ "GenSigSendType" SG_ 1362 ICC_LISD_Pixel211_OnOff 5;
BA_ "GenSigSendType" SG_ 1362 ICC_LISD_Pixel212_OnOff 5;
BA_ "GenSigSendType" SG_ 1362 ICC_LISD_Pixel213_OnOff 5;
BA_ "GenSigSendType" SG_ 1362 ICC_LISD_Pixel214_OnOff 5;
BA_ "GenSigSendType" SG_ 1362 ICC_LISD_Pixel215_OnOff 5;
BA_ "GenSigSendType" SG_ 1362 ICC_LISD_Pixel216_OnOff 5;
BA_ "GenSigSendType" SG_ 1362 ICC_LISD_Pixel217_OnOff 5;
BA_ "GenSigSendType" SG_ 1362 ICC_LISD_Pixel218_OnOff 5;
BA_ "GenSigSendType" SG_ 1362 ICC_LISD_Pixel219_OnOff 5;
BA_ "GenSigSendType" SG_ 1362 ICC_LISD_Pixel220_OnOff 5;
BA_ "GenSigSendType" SG_ 1362 ICC_LISD_Pixel221_OnOff 5;
BA_ "GenSigSendType" SG_ 1362 ICC_LISD_Pixel222_OnOff 5;
BA_ "GenSigSendType" SG_ 1362 ICC_LISD_Pixel223_OnOff 5;
BA_ "GenSigSendType" SG_ 1362 ICC_LISD_Pixel224_OnOff 5;
BA_ "GenSigSendType" SG_ 1362 ICC_LISD_Pixel225_OnOff 5;
BA_ "GenSigSendType" SG_ 1362 ICC_LISD_Pixel226_OnOff 5;
BA_ "GenSigSendType" SG_ 1362 ICC_LISD_Pixel227_OnOff 5;
BA_ "GenSigSendType" SG_ 1362 ICC_LISD_Pixel228_OnOff 5;
BA_ "GenSigSendType" SG_ 1362 ICC_LISD_Pixel229_OnOff 5;
BA_ "GenSigSendType" SG_ 1362 ICC_LISD_Pixel230_OnOff 5;
BA_ "GenSigSendType" SG_ 1362 ICC_LISD_Pixel231_OnOff 5;
BA_ "GenSigSendType" SG_ 1362 ICC_LISD_Pixel232_OnOff 5;
BA_ "GenSigSendType" SG_ 1362 ICC_LISD_Pixel233_OnOff 5;
BA_ "GenSigSendType" SG_ 1362 ICC_LISD_Pixel234_OnOff 5;
BA_ "GenSigSendType" SG_ 1362 ICC_LISD_Pixel235_OnOff 5;
BA_ "GenSigSendType" SG_ 1362 ICC_LISD_Pixel236_OnOff 5;
BA_ "GenSigSendType" SG_ 1362 ICC_LISD_Pixel237_OnOff 5;
BA_ "GenSigSendType" SG_ 1362 ICC_LISD_Pixel238_OnOff 5;
BA_ "GenSigSendType" SG_ 1362 ICC_LISD_Pixel239_OnOff 5;
BA_ "GenSigSendType" SG_ 1362 ICC_LISD_Pixel240_OnOff 5;
BA_ "GenSigSendType" SG_ 1362 ICC_LISD_Pixel241_OnOff 5;
BA_ "GenSigSendType" SG_ 1362 ICC_LISD_Pixel242_OnOff 5;
BA_ "GenSigSendType" SG_ 1362 ICC_LISD_Pixel243_OnOff 5;
BA_ "GenSigSendType" SG_ 1362 ICC_LISD_Pixel244_OnOff 5;
BA_ "GenSigSendType" SG_ 1362 ICC_LISD_Pixel245_OnOff 5;
BA_ "GenSigSendType" SG_ 1362 ICC_LISD_Pixel246_OnOff 5;
BA_ "GenSigSendType" SG_ 1362 ICC_LISD_Pixel247_OnOff 5;
BA_ "GenSigSendType" SG_ 1362 ICC_LISD_Pixel248_OnOff 5;
BA_ "GenSigSendType" SG_ 1362 ICC_LISD_Pixel249_OnOff 5;
BA_ "GenSigSendType" SG_ 1362 ICC_LISD_Pixel250_OnOff 5;
BA_ "GenSigSendType" SG_ 1362 ICC_LISD_Pixel251_OnOff 5;
BA_ "GenSigSendType" SG_ 1362 ICC_LISD_Pixel252_OnOff 5;
BA_ "GenSigSendType" SG_ 1362 ICC_LISD_Pixel253_OnOff 5;
BA_ "GenSigSendType" SG_ 1362 ICC_LISD_Pixel254_OnOff 5;
BA_ "GenSigSendType" SG_ 1362 ICC_LISD_Pixel255_OnOff 5;
BA_ "GenSigSendType" SG_ 1362 ICC_LISD_Pixel256_OnOff 5;
BA_ "GenSigSendType" SG_ 1362 ICC_LISD_Pixel257_OnOff 5;
BA_ "GenSigSendType" SG_ 1362 ICC_LISD_Pixel258_OnOff 5;
BA_ "GenSigSendType" SG_ 1362 ICC_LISD_Pixel259_OnOff 5;
BA_ "GenSigSendType" SG_ 1362 ICC_LISD_Pixel260_OnOff 5;
BA_ "GenSigSendType" SG_ 1362 ICC_LISD_Pixel261_OnOff 5;
BA_ "GenSigSendType" SG_ 1362 ICC_LISD_Pixel262_OnOff 5;
BA_ "GenSigSendType" SG_ 1362 ICC_LISD_Pixel263_OnOff 5;
BA_ "GenSigSendType" SG_ 1362 ICC_LISD_Pixel264_OnOff 5;
BA_ "GenSigSendType" SG_ 1362 ICC_LISD_Pixel265_OnOff 5;
BA_ "GenSigSendType" SG_ 1362 ICC_LISD_Pixel266_OnOff 5;
BA_ "GenSigSendType" SG_ 1362 ICC_LISD_Pixel267_OnOff 5;
BA_ "GenSigSendType" SG_ 1362 ICC_LISD_Pixel268_OnOff 5;
BA_ "GenSigSendType" SG_ 1362 ICC_LISD_Pixel269_OnOff 5;
BA_ "GenSigSendType" SG_ 1362 ICC_LISD_Pixel270_OnOff 5;
BA_ "GenSigSendType" SG_ 1362 ICC_LISD_Pixel271_OnOff 5;
BA_ "GenSigSendType" SG_ 1362 ICC_LISD_Pixel272_OnOff 5;
BA_ "GenSigSendType" SG_ 1362 ICC_LISD_Pixel273_OnOff 5;
BA_ "GenSigSendType" SG_ 1362 ICC_LISD_Pixel274_OnOff 5;
BA_ "GenSigSendType" SG_ 1362 ICC_LISD_Pixel275_OnOff 5;
BA_ "GenSigSendType" SG_ 1362 ICC_LISD_Pixel276_OnOff 5;
BA_ "GenSigSendType" SG_ 1362 ICC_LISD_Pixel277_OnOff 5;
BA_ "GenSigSendType" SG_ 1362 ICC_LISD_Pixel278_OnOff 5;
BA_ "GenSigSendType" SG_ 1362 ICC_LISD_Pixel279_OnOff 5;
BA_ "GenSigSendType" SG_ 1362 ICC_LISD_Pixel280_OnOff 5;
BA_ "GenSigSendType" SG_ 1362 ICC_LISD_Pixel281_OnOff 5;
BA_ "GenSigSendType" SG_ 1362 ICC_LISD_Pixel282_OnOff 5;
BA_ "GenSigSendType" SG_ 1362 ICC_LISD_Pixel283_OnOff 5;
BA_ "GenSigSendType" SG_ 1362 ICC_LISD_Pixel284_OnOff 5;
BA_ "GenSigSendType" SG_ 1362 ICC_LISD_Pixel285_OnOff 5;
BA_ "GenSigSendType" SG_ 1362 ICC_LISD_Pixel286_OnOff 5;
BA_ "GenSigSendType" SG_ 1362 ICC_LISD_Pixel287_OnOff 5;
BA_ "GenSigSendType" SG_ 1362 ICC_LISD_Pixel288_OnOff 5;
BA_ "GenSigSendType" SG_ 1362 ICC_LISD_Pixel289_OnOff 5;
BA_ "GenSigSendType" SG_ 1362 ICC_LISD_Pixel290_OnOff 5;
BA_ "GenSigSendType" SG_ 1362 ICC_LISD_Pixel291_OnOff 5;
BA_ "GenSigSendType" SG_ 1362 ICC_LISD_Pixel292_OnOff 5;
BA_ "GenSigSendType" SG_ 1362 ICC_LISD_Pixel293_OnOff 5;
BA_ "GenSigSendType" SG_ 1362 ICC_LISD_Pixel294_OnOff 5;
BA_ "GenSigSendType" SG_ 1362 ICC_LISD_Pixel295_OnOff 5;
BA_ "GenSigSendType" SG_ 1362 ICC_LISD_Pixel296_OnOff 5;
BA_ "GenSigSendType" SG_ 1362 ICC_LISD_Pixel297_OnOff 5;
BA_ "GenSigSendType" SG_ 1362 ICC_LISD_Pixel298_OnOff 5;
BA_ "GenSigSendType" SG_ 1362 ICC_LISD_Pixel299_OnOff 5;
BA_ "GenSigSendType" SG_ 1362 ICC_LISD_Pixel300_OnOff 5;
BA_ "GenSigSendType" SG_ 1362 ICC_LISD_Pixel301_OnOff 5;
BA_ "GenSigSendType" SG_ 1362 ICC_LISD_Pixel302_OnOff 5;
BA_ "GenSigSendType" SG_ 1362 ICC_LISD_Pixel303_OnOff 5;
BA_ "GenSigSendType" SG_ 1362 ICC_LISD_Pixel304_OnOff 5;
BA_ "GenSigSendType" SG_ 1362 ICC_LISD_Pixel305_OnOff 5;
BA_ "GenSigSendType" SG_ 1362 ICC_LISD_Pixel306_OnOff 5;
BA_ "GenSigSendType" SG_ 1362 ICC_LISD_Pixel307_OnOff 5;
BA_ "GenSigSendType" SG_ 1362 ICC_LISD_Pixel308_OnOff 5;
BA_ "GenSigSendType" SG_ 1362 ICC_LISD_Pixel309_OnOff 5;
BA_ "GenSigSendType" SG_ 1362 ICC_LISD_Pixel310_OnOff 5;
BA_ "GenSigSendType" SG_ 1362 ICC_LISD_Pixel311_OnOff 5;
BA_ "GenSigSendType" SG_ 1362 ICC_LISD_Pixel312_OnOff 5;
BA_ "GenSigSendType" SG_ 1362 ICC_LISD_Pixel313_OnOff 5;
BA_ "GenSigSendType" SG_ 1362 ICC_LISD_Pixel314_OnOff 5;
BA_ "GenSigSendType" SG_ 1362 ICC_LISD_Pixel315_OnOff 5;
BA_ "GenSigSendType" SG_ 1362 ICC_LISD_Pixel316_OnOff 5;
BA_ "GenSigSendType" SG_ 1362 ICC_LISD_Pixel317_OnOff 5;
BA_ "GenSigSendType" SG_ 1362 ICC_LISD_Pixel318_OnOff 5;
BA_ "GenSigSendType" SG_ 1362 ICC_LISD_Pixel319_OnOff 5;
BA_ "GenSigSendType" SG_ 1362 ICC_LISD_Pixel320_OnOff 5;
BA_ "GenSigSendType" SG_ 1362 ICC_LISD_Pixel321_OnOff 5;
BA_ "GenSigSendType" SG_ 1362 ICC_LISD_Pixel322_OnOff 5;
BA_ "GenSigSendType" SG_ 1362 ICC_LISD_Pixel323_OnOff 5;
BA_ "GenSigSendType" SG_ 1362 ICC_LISD_Pixel324_OnOff 5;
BA_ "GenSigSendType" SG_ 1362 ICC_LISD_Pixel325_OnOff 5;
BA_ "GenSigSendType" SG_ 1362 ICC_LISD_Pixel326_OnOff 5;
BA_ "GenSigSendType" SG_ 1362 ICC_LISD_Pixel327_OnOff 5;
BA_ "GenSigSendType" SG_ 1362 ICC_LISD_Pixel328_OnOff 5;
BA_ "GenSigSendType" SG_ 1362 ICC_LISD_Pixel329_OnOff 5;
BA_ "GenSigSendType" SG_ 1362 ICC_LISD_Pixel330_OnOff 5;
BA_ "GenSigSendType" SG_ 1362 ICC_LISD_Pixel331_OnOff 5;
BA_ "GenSigSendType" SG_ 1362 ICC_LISD_Pixel332_OnOff 5;
BA_ "GenSigSendType" SG_ 1362 ICC_LISD_Pixel333_OnOff 5;
BA_ "GenSigSendType" SG_ 1362 ICC_LISD_Pixel334_OnOff 5;
BA_ "GenSigSendType" SG_ 1362 ICC_LISD_Pixel335_OnOff 5;
BA_ "GenSigSendType" SG_ 1362 ICC_LISD_Pixel336_OnOff 5;
BA_ "GenSigSendType" SG_ 1362 ICC_LISD_Pixel337_OnOff 5;
BA_ "GenSigSendType" SG_ 1362 ICC_LISD_Pixel338_OnOff 5;
BA_ "GenSigSendType" SG_ 1362 ICC_LISD_Pixel339_OnOff 5;
BA_ "GenSigSendType" SG_ 1362 ICC_LISD_Pixel340_OnOff 5;
BA_ "GenSigSendType" SG_ 1362 ICC_LISD_Pixel341_OnOff 5;
BA_ "GenSigSendType" SG_ 1362 ICC_LISD_Pixel342_OnOff 5;
BA_ "GenSigSendType" SG_ 1362 ICC_LISD_Pixel343_OnOff 5;
BA_ "GenSigSendType" SG_ 1362 ICC_LISD_Pixel344_OnOff 5;
BA_ "GenSigSendType" SG_ 1362 ICC_LISD_Pixel345_OnOff 5;
BA_ "GenSigSendType" SG_ 1362 ICC_LISD_Pixel346_OnOff 5;
BA_ "GenSigSendType" SG_ 1362 ICC_LISD_Pixel347_OnOff 5;
BA_ "GenSigSendType" SG_ 1362 ICC_LISD_Pixel348_OnOff 5;
BA_ "GenSigSendType" SG_ 1362 ICC_LISD_Pixel349_OnOff 5;
BA_ "GenSigSendType" SG_ 1362 ICC_LISD_Pixel350_OnOff 5;
BA_ "GenSigSendType" SG_ 1362 ICC_LISD_Pixel351_OnOff 5;
BA_ "GenSigSendType" SG_ 1362 ICC_LISD_Pixel352_OnOff 5;
BA_ "GenSigSendType" SG_ 1362 ICC_LISD_Pixel353_OnOff 5;
BA_ "GenSigSendType" SG_ 1362 ICC_LISD_Pixel354_OnOff 5;
BA_ "GenSigSendType" SG_ 1362 ICC_LISD_Pixel355_OnOff 5;
BA_ "GenSigSendType" SG_ 1362 ICC_LISD_Pixel356_OnOff 5;
BA_ "GenSigSendType" SG_ 1362 ICC_LISD_Pixel357_OnOff 5;
BA_ "GenSigSendType" SG_ 1362 ICC_LISD_Pixel358_OnOff 5;
BA_ "GenSigSendType" SG_ 1362 ICC_LISD_Pixel359_OnOff 5;
BA_ "GenSigSendType" SG_ 1362 ICC_LISD_Pixel360_OnOff 5;
BA_ "GenSigSendType" SG_ 1362 ICC_LISD_Pixel361_OnOff 5;
BA_ "GenSigSendType" SG_ 1362 ICC_LISD_Pixel362_OnOff 5;
BA_ "GenSigSendType" SG_ 1362 ICC_LISD_Pixel363_OnOff 5;
BA_ "GenSigSendType" SG_ 1362 ICC_LISD_Pixel364_OnOff 5;
BA_ "GenSigSendType" SG_ 1362 ICC_LISD_Pixel365_OnOff 5;
BA_ "GenSigSendType" SG_ 1362 ICC_LISD_Pixel366_OnOff 5;
BA_ "GenSigSendType" SG_ 1362 ICC_LISD_Pixel367_OnOff 5;
BA_ "GenSigSendType" SG_ 1362 ICC_LISD_Pixel368_OnOff 5;
BA_ "GenSigSendType" SG_ 1362 ICC_LISD_Pixel369_OnOff 5;
BA_ "GenSigSendType" SG_ 1362 ICC_LISD_Pixel370_OnOff 5;
BA_ "GenSigSendType" SG_ 1362 ICC_LISD_Pixel371_OnOff 5;
BA_ "GenSigSendType" SG_ 1362 ICC_LISD_Pixel372_OnOff 5;
BA_ "GenSigSendType" SG_ 1362 ICC_LISD_Pixel373_OnOff 5;
BA_ "GenSigSendType" SG_ 1362 ICC_LISD_Pixel374_OnOff 5;
BA_ "GenSigSendType" SG_ 1362 ICC_LISD_Pixel375_OnOff 5;
BA_ "GenSigSendType" SG_ 1362 ICC_LISD_Pixel376_OnOff 5;
BA_ "GenSigSendType" SG_ 1362 ICC_LISD_Pixel377_OnOff 5;
BA_ "GenSigSendType" SG_ 1362 ICC_LISD_Pixel378_OnOff 5;
BA_ "GenSigSendType" SG_ 1362 ICC_LISD_Pixel379_OnOff 5;
BA_ "GenSigSendType" SG_ 1362 ICC_LISD_Pixel380_OnOff 5;
BA_ "GenSigSendType" SG_ 1362 ICC_LISD_Pixel381_OnOff 5;
BA_ "GenSigSendType" SG_ 1362 ICC_LISD_Pixel382_OnOff 5;
BA_ "GenSigSendType" SG_ 1362 ICC_LISD_Pixel383_OnOff 5;
BA_ "GenSigSendType" SG_ 1362 ICC_LISD_Pixel384_OnOff 5;
BA_ "GenSigSendType" SG_ 1362 ICC_LISD_Pixel385_OnOff 5;
BA_ "GenSigSendType" SG_ 1362 ICC_LISD_Pixel386_OnOff 5;
BA_ "GenSigSendType" SG_ 1362 ICC_LISD_Pixel387_OnOff 5;
BA_ "GenSigSendType" SG_ 1362 ICC_LISD_Pixel388_OnOff 5;
BA_ "GenSigSendType" SG_ 1362 ICC_LISD_Pixel389_OnOff 5;
BA_ "GenSigSendType" SG_ 1362 ICC_LISD_Pixel390_OnOff 5;
BA_ "GenSigSendType" SG_ 1362 ICC_LISD_Pixel391_OnOff 5;
BA_ "GenSigSendType" SG_ 1362 ICC_LISD_Pixel392_OnOff 5;
BA_ "GenSigSendType" SG_ 1362 ICC_LISD_Pixel393_OnOff 5;
BA_ "GenSigSendType" SG_ 1362 ICC_LISD_Pixel394_OnOff 5;
BA_ "GenSigSendType" SG_ 1362 ICC_LISD_Pixel395_OnOff 5;
BA_ "GenSigSendType" SG_ 1362 ICC_LISD_Pixel396_OnOff 5;
BA_ "GenSigSendType" SG_ 1362 ICC_LISD_Pixel397_OnOff 5;
BA_ "GenSigSendType" SG_ 1362 ICC_LISD_Pixel398_OnOff 5;
BA_ "GenSigSendType" SG_ 1362 ICC_LISD_Pixel399_OnOff 5;
BA_ "GenSigSendType" SG_ 1362 ICC_LISD_Pixel400_OnOff 5;
BA_ "GenSigSendType" SG_ 1362 ICC_LISD_Pixel401_OnOff 5;
BA_ "GenSigSendType" SG_ 1362 ICC_LISD_Pixel402_OnOff 5;
BA_ "GenSigSendType" SG_ 1362 ICC_LISD_Pixel403_OnOff 5;
BA_ "GenSigSendType" SG_ 1362 ICC_LISD_Pixel404_OnOff 5;
BA_ "GenSigSendType" SG_ 1362 ICC_LISD_Pixel405_OnOff 5;
BA_ "GenSigSendType" SG_ 1362 ICC_LISD_Pixel406_OnOff 5;
BA_ "GenSigSendType" SG_ 1362 ICC_LISD_Pixel407_OnOff 5;
BA_ "GenSigSendType" SG_ 1362 ICC_LISD_Pixel408_OnOff 5;
BA_ "GenSigSendType" SG_ 1362 ICC_LISD_Pixel409_OnOff 5;
BA_ "GenSigSendType" SG_ 1362 ICC_LISD_Pixel410_OnOff 5;
BA_ "GenSigSendType" SG_ 1362 ICC_LISD_Pixel411_OnOff 5;
BA_ "GenSigSendType" SG_ 1362 ICC_LISD_Pixel412_OnOff 5;
BA_ "GenSigSendType" SG_ 1362 ICC_LISD_Pixel413_OnOff 5;
BA_ "GenSigSendType" SG_ 1362 ICC_LISD_Pixel414_OnOff 5;
BA_ "GenSigSendType" SG_ 1362 ICC_LISD_Pixel415_OnOff 5;
BA_ "GenSigSendType" SG_ 1362 ICC_LISD_Pixel416_OnOff 5;
BA_ "GenSigSendType" SG_ 1362 ICC_LISD_Pixel417_OnOff 5;
BA_ "GenSigSendType" SG_ 1362 ICC_LISD_Pixel418_OnOff 5;
BA_ "GenSigSendType" SG_ 1362 ICC_LISD_Pixel419_OnOff 5;
BA_ "GenSigSendType" SG_ 1362 ICC_LISD_Pixel420_OnOff 5;
BA_ "GenSigSendType" SG_ 1362 ICC_LISD_Pixel421_OnOff 5;
BA_ "GenSigSendType" SG_ 1362 ICC_LISD_Pixel422_OnOff 5;
BA_ "GenSigSendType" SG_ 1362 ICC_LISD_Pixel423_OnOff 5;
BA_ "GenSigSendType" SG_ 1362 ICC_LISD_Pixel424_OnOff 5;
BA_ "GenSigSendType" SG_ 1362 ICC_LISD_Pixel425_OnOff 5;
BA_ "GenSigSendType" SG_ 1362 ICC_LISD_Pixel426_OnOff 5;
BA_ "GenSigSendType" SG_ 1362 ICC_LISD_Pixel427_OnOff 5;
BA_ "GenSigSendType" SG_ 1362 ICC_LISD_Pixel428_OnOff 5;
BA_ "GenSigSendType" SG_ 1362 ICC_LISD_Pixel429_OnOff 5;
BA_ "GenSigSendType" SG_ 1362 ICC_LISD_Pixel430_OnOff 5;
BA_ "GenSigSendType" SG_ 1362 ICC_LISD_Pixel431_OnOff 5;
BA_ "GenSigSendType" SG_ 1362 ICC_LISD_Pixel432_OnOff 5;
BA_ "GenSigSendType" SG_ 1362 ICC_LISD_Pixel433_OnOff 5;
BA_ "GenSigSendType" SG_ 1362 ICC_LISD_Pixel434_OnOff 5;
BA_ "GenSigSendType" SG_ 1362 ICC_LISD_Pixel435_OnOff 5;
BA_ "GenSigSendType" SG_ 1362 ICC_LISD_Pixel436_OnOff 5;
BA_ "GenSigSendType" SG_ 1362 ICC_LISD_Pixel437_OnOff 5;
BA_ "GenSigSendType" SG_ 1362 ICC_LISD_Pixel438_OnOff 5;
BA_ "GenSigSendType" SG_ 1362 ICC_LISD_Pixel439_OnOff 5;
BA_ "GenSigSendType" SG_ 1362 ICC_LISD_Pixel440_OnOff 5;
BA_ "GenSigSendType" SG_ 1362 ICC_LISD_Pixel441_OnOff 5;
BA_ "GenSigSendType" SG_ 1362 ICC_LISD_Pixel442_OnOff 5;
BA_ "GenSigSendType" SG_ 1362 ICC_LISD_Pixel443_OnOff 5;
BA_ "GenSigSendType" SG_ 1362 ICC_LISD_Pixel444_OnOff 5;
BA_ "GenSigSendType" SG_ 1362 ICC_LISD_Pixel445_OnOff 5;
BA_ "GenSigSendType" SG_ 1362 ICC_LISD_Pixel446_OnOff 5;
BA_ "GenSigSendType" SG_ 1362 ICC_LISD_Pixel447_OnOff 5;
BA_ "GenSigSendType" SG_ 1362 ICC_LISD_Pixel448_OnOff 5;
BA_ "GenSigSendType" SG_ 1362 ICC_LISD_Pixel449_OnOff 5;
BA_ "GenSigSendType" SG_ 1362 ICC_LISD_Pixel450_OnOff 5;
BA_ "GenSigSendType" SG_ 1362 ICC_LISD_Pixel451_OnOff 5;
BA_ "GenSigSendType" SG_ 1362 ICC_LISD_Pixel452_OnOff 5;
BA_ "GenSigSendType" SG_ 1362 ICC_LISD_Pixel453_OnOff 5;
BA_ "GenSigSendType" SG_ 1362 ICC_LISD_Pixel454_OnOff 5;
BA_ "GenSigSendType" SG_ 1362 ICC_LISD_Pixel455_OnOff 5;
BA_ "GenSigSendType" SG_ 1362 ICC_LISD_Pixel456_OnOff 5;
BA_ "GenSigSendType" SG_ 1362 ICC_LISD_Pixel457_OnOff 5;
BA_ "GenSigSendType" SG_ 1362 ICC_LISD_Pixel458_OnOff 5;
BA_ "GenSigSendType" SG_ 1362 ICC_LISD_Pixel459_OnOff 5;
BA_ "GenSigSendType" SG_ 1362 ICC_LISD_Pixel460_OnOff 5;
BA_ "GenSigSendType" SG_ 1362 ICC_LISD_Pixel461_OnOff 5;
BA_ "GenSigSendType" SG_ 1362 ICC_LISD_Pixel462_OnOff 5;
BA_ "GenSigSendType" SG_ 1362 ICC_LISD_Pixel463_OnOff 5;
BA_ "GenSigSendType" SG_ 1362 ICC_LISD_Pixel464_OnOff 5;
BA_ "GenSigSendType" SG_ 1362 ICC_LISD_Pixel465_OnOff 5;
BA_ "GenSigSendType" SG_ 1362 ICC_LISD_Pixel466_OnOff 5;
BA_ "GenSigSendType" SG_ 1362 ICC_LISD_Pixel467_OnOff 5;
BA_ "GenSigSendType" SG_ 1362 ICC_LISD_Pixel468_OnOff 5;
BA_ "GenSigSendType" SG_ 1362 ICC_LISD_Pixel469_OnOff 5;
BA_ "GenSigSendType" SG_ 1362 ICC_LISD_Pixel470_OnOff 5;
BA_ "GenSigSendType" SG_ 1362 ICC_LISD_Pixel471_OnOff 5;
BA_ "GenSigSendType" SG_ 1362 ICC_LISD_Pixel472_OnOff 5;
BA_ "GenSigSendType" SG_ 1362 ICC_LISD_Pixel473_OnOff 5;
BA_ "GenSigSendType" SG_ 1362 ICC_LISD_Pixel474_OnOff 5;
BA_ "GenSigSendType" SG_ 1362 ICC_LISD_Pixel475_OnOff 5;
BA_ "GenSigSendType" SG_ 1362 ICC_LISD_Pixel476_OnOff 5;
BA_ "GenSigSendType" SG_ 1362 ICC_LISD_Pixel477_OnOff 5;
BA_ "GenSigSendType" SG_ 1362 ICC_LISD_Pixel478_OnOff 5;
BA_ "GenSigSendType" SG_ 1362 ICC_LISD_Pixel479_OnOff 5;
BA_ "GenSigSendType" SG_ 1362 ICC_LISD_Pixel480_OnOff 5;
BA_ "GenSigSendType" SG_ 1362 ICC_LISD_Pixel481_OnOff 5;
BA_ "GenSigSendType" SG_ 1362 ICC_LISD_Pixel482_OnOff 5;
BA_ "GenSigSendType" SG_ 1362 ICC_LISD_Pixel483_OnOff 5;
BA_ "GenSigSendType" SG_ 1362 ICC_LISD_Pixel484_OnOff 5;
BA_ "GenSigSendType" SG_ 1362 ICC_LISD_Pixel485_OnOff 5;
BA_ "GenSigSendType" SG_ 1362 ICC_LISD_Pixel486_OnOff 5;
BA_ "GenSigSendType" SG_ 1362 ICC_LISD_Pixel487_OnOff 5;
BA_ "GenSigSendType" SG_ 1362 ICC_LISD_Pixel488_OnOff 5;
BA_ "GenSigSendType" SG_ 1362 ICC_LISD_Pixel489_OnOff 5;
BA_ "GenSigSendType" SG_ 1362 ICC_LISD_Pixel490_OnOff 5;
BA_ "GenSigSendType" SG_ 1362 ICC_LISD_Pixel491_OnOff 5;
BA_ "GenSigSendType" SG_ 1362 ICC_LISD_Pixel492_OnOff 5;
BA_ "GenSigSendType" SG_ 1362 ICC_LISD_Pixel493_OnOff 5;
BA_ "GenSigSendType" SG_ 1362 ICC_LISD_Pixel494_OnOff 5;
BA_ "GenSigSendType" SG_ 1362 ICC_LISD_Pixel495_OnOff 5;
BA_ "GenSigSendType" SG_ 1362 ICC_LISD_Pixel496_OnOff 5;
BA_ "GenSigSendType" SG_ 1362 ICC_LISD_Pixel497_OnOff 5;
BA_ "GenSigSendType" SG_ 1362 ICC_LISD_Pixel498_OnOff 5;
BA_ "GenSigSendType" SG_ 1362 ICC_LISD_Pixel499_OnOff 5;
BA_ "GenSigSendType" SG_ 1362 ICC_LISD_Pixel500_OnOff 5;
BA_ "GenSigSendType" SG_ 1362 ICC_LISD_Pixel501_OnOff 5;
BA_ "GenSigSendType" SG_ 1362 ICC_LISD_Pixel502_OnOff 5;
BA_ "GenSigSendType" SG_ 1362 ICC_LISD_Pixel503_OnOff 5;
BA_ "GenSigSendType" SG_ 1362 ICC_LISD_Pixel504_OnOff 5;
VAL_ 1238 ICC_CFSSwitch 0 "Not Active" 1 "ON" 2 "OFF" 3 "Not Used" ;
VAL_ 1238 ICC_CFSLevelSet 0 "Not Active" 1 "Level 1" 2 "Level 2" 3 "Level 3" 4 "Reserved" 5 "Reserved" 6 "Reserved" 7 "Reserved" ;
VAL_ 1238 ICC_CFSPosSet 0 "Not Active" 1 "Position One" 2 "Position Two" 3 "Position Three" ;
VAL_ 1238 ICC_PM25Switch 0 "Not Active" 1 "ON" 2 "OFF" 3 "Not Used" ;
VAL_ 1238 ICC_AQSSwitch 0 "Not Active" 1 "ON" 2 "OFF" 3 "Not Used" ;
VAL_ 1238 ICC_SecSetTemp_C 31 "Not Active" ;
VAL_ 1238 ICC_SecFaceKeySts 0 "Not Active" 1 "ON" 2 "OFF" 3 "Not Used" ;
VAL_ 1238 ICC_SecFootKeySts 0 "Not Active" 1 "ON" 2 "OFF" 3 "Not Used" ;
VAL_ 1238 ICC_SecBlowSpeedLevelKeySts 0 "Not Active" 1 "Level  1" 2 "Level  2" 3 "Level  3" 4 "Level  4" 5 "Level  5" 6 "Level  6" 7 "Level  7" 8 "Reserved" 9 "Reserved" 10 "Reserved" 11 "Reserved" 12 "Reserved" 13 "Reserved" 14 "Reserved" 15 "Reserved" ;
VAL_ 1238 ICC_SecAutoSwitch 0 "Not Active" 1 "ON" 2 "OFF" 3 "Not Used" ;
VAL_ 1238 ICC_SecCLMSwitch 0 "Not Active" 1 "ON" 2 "OFF" 3 "Not Used" ;
VAL_ 1238 ICC_ThrSetTemp_C 31 "Not Active" ;
VAL_ 1238 ICC_ThrFaceKeySts 0 "Not Active" 1 "ON" 2 "OFF" 3 "Not Used" ;
VAL_ 1238 ICC_ThrFootKeySts 0 "Not Active" 1 "ON" 2 "OFF" 3 "Not Used" ;
VAL_ 1238 ICC_ThrBlowSpeedLevelKeySts 0 "Not Active" 1 "Level  1" 2 "Level  2" 3 "Level  3" 4 "Level  4" 5 "Level  5" 6 "Level  6" 7 "Level  7" 8 "Level  0" 9 "Reserved" 10 "Reserved" 11 "Reserved" 12 "Reserved" 13 "Reserved" 14 "Reserved" 15 "Reserved" ;
VAL_ 1238 ICC_ThrAutoSwitch 0 "Not Active" 1 "ON" 2 "OFF" 3 "Not Used" ;
VAL_ 1238 ICC_ThrCLMSwitch 0 "Not Active" 1 "ON" 2 "OFF" 3 "Not Used" ;
VAL_ 1238 ICC_ThrACRequestKeySts 0 "Not Active" 1 "ON" 2 "OFF" 3 "Not used" ;
VAL_ 1238 ICC_DFMSwitch 0 "Not Active" 1 "ON" 2 "OFF" 3 "Not Used" ;
VAL_ 1289 ICC_TirePressureDisplayUnit 0 "Not Active" 1 "kPa" 2 "bar" 3 "psi" ;
VAL_ 1289 ICC_TireTemperatureDisplayUnit 0 "Not Active" 1 "°C" 2 "F" 3 "Reserved" ;
VAL_ 1289 ICC_ToggleUnits 0 "Not Active" 1 "Imperial" 2 "Metric" 3 "Reserved" ;
VAL_ 1289 ICC_BtConFlag 0 "invalid" 1 "bluetooth not found" 2 "PIN error" 3 "other anomalies" 4 "bluetooth connection successful" ;
VAL_ 1289 ICC_GPSSwitchSet 0 "Not Active" 1 "On" 2 "Off" 3 "Not Used" ;
VAL_ 1167 ICC_KeyDriveModememory 0 "Not Active" 1 "ON" 2 "OFF" 3 "Reserved" ;
VAL_ 1167 ICC_DriveModeSet 0 "Not Active" 1 "ECO" 2 "NORMAL" 3 "SPORT" 4 "SNOW" 5 "MUD" 6 "OffRoad" 7 "SAND" 8 "ROCK" 9 "EXPERT" 10 "X" 11 "WADE" 12 "UTURN" 13 "DRIFT" 14 "TOW" 15 "OffroadRace" 16 "Reserved" 17 "Reserved" 18 "Reserved" 19 "Reserved" 20 "Reserved" 21 "Reserved" 22 "Reserved" 23 "Reserved" 24 "Reserved" 25 "Reserved" 26 "Reserved" 27 "Reserved" 28 "Reserved" 29 "Reserved" 30 "Reserved" 31 "Reserved" ;
VAL_ 1167 ICC_DRIFTModeSetReq 0 "Not active" 1 "Entry Mode" 2 "Master mode" 3 "Expert mode" ;
VAL_ 1167 ICC_EXPERTEIPBESPSet 0 "Not Active" 1 "TCS_VDC_OFF" 2 "ALL_ON" 3 "ALL_OFF" ;
VAL_ 1167 ICC_EXPERTEcoSet 0 "Not Active" 1 "ON" 2 "OFF" 3 "Reserved" ;
VAL_ 1167 ICC_EXPERTNormSet 0 "NotActive" 1 "ON" 2 "OFF" 3 "Reserved" ;
VAL_ 1167 ICC_EXPERTSportSet 0 "Not Active" 1 "ON" 2 "OFF" 3 "Reserved" ;
VAL_ 1167 ICC_CrossaxisSet 0 "Not Active" 1 "ON" 2 "OFF" 3 "Reserved" ;
VAL_ 1167 ICC_EXPERTRWDSet 0 "Not Active" 1 "ON" 2 "OFF" 3 "Reserved" ;
VAL_ 1167 ICC_EXPERTAWDSet 0 "Not Active" 1 "ON" 2 "OFF" 3 "Reserved" ;
VAL_ 1167 ICC_EXPERTAutoSet 0 "Not Active" 1 "ON" 2 "OFF" 3 "Reserved" ;
VAL_ 1167 ICC_CLIMBSet 0 "Not Active" 1 "ON" 2 "OFF" 3 "Reserved" ;
VAL_ 1167 ICC_DriveModeExitSet 0 "Not Active" 1 "ON" 2 "OFF" 3 "Reserved" ;
VAL_ 1167 ICC_CCOSwtReq 0 "Not Active" 1 "ON" 2 "OFF" 3 "Reserved" ;
VAL_ 1167 ICC_TABSwtReq 0 "Not Active" 1 "ON" 2 "OFF" 3 "Reserved" ;
VAL_ 1167 ICC_V2L_IntlDisChg 0 "Not Active" 1 "OFF" 2 "IntelV2L ON" 3 "Reserved" ;
VAL_ 1167 ICC_ExhibitionModeSwitch 0 "Not Active" 1 "ON" 2 "OFF" 3 "Reserved" ;
VAL_ 1167 ICC_TrailerMode 0 "Not Active" 1 "ON" 2 "OFF" 3 "Reserved" ;
VAL_ 1167 ICC_V2L_DisChgMem 0 "Not Active" 1 "Remember" 2 "No Remember" 3 "Reserved" ;
VAL_ 1167 ICC_DrivePowerDispSet 0 "Not Active" 1 "PercentDisp" 2 "kWDisp" 3 "Reserved" ;
VAL_ 1167 ICC_WLTC_to_CLTC_Mode 0 "Not Active" 1 "CLTC" 2 "WLTC" 3 "Reserved" ;
VAL_ 1167 ICC_StopChrgnSwitch 0 "Not Active" 1 "ON" 2 "OFF" 3 "Reserved" ;
VAL_ 1167 ICC_StopChrgnMode 0 "Not Active" 1 "Silence" 2 "Quick" 3 "Reserved" ;
VAL_ 1167 ICC_RegenerateLevelCtrl 0 "Not Active" 1 "Low" 2 "High" 3 "middle" 4 "SinglePedl" 5 "Reserved" 6 "Reserved" 7 "Reserved" ;
VAL_ 1167 ICC_SinglePedalMem 0 "Not Active" 1 "ON" 2 "OFF" 3 "Reserved" ;
VAL_ 1167 ICC_FuelDetnSwt 0 "Not Active" 1 "ON" 2 "OFF" 3 "Reserved" ;
VAL_ 1167 ICC_FuelDetnState 0 "Not Active" 1 "High Idle" 2 "Low Idle" 3 "Reserved" ;
VAL_ 1167 ICC_FuelDetnOpDefeated 0 "No Prompt" 1 "Prompt" ;
VAL_ 1167 ICC_HVDownRepairMode 0 "Not Active" 1 "ON" 2 "OFF" 3 "Reserved" ;
VAL_ 1167 ICC_UTURNSnowSet 0 "Not Active" 1 "ON" 2 "OFF" 3 "Reserved" ;
VAL_ 1167 ICC_UTURNSandSet 0 "Not Active" 1 "ON" 2 "OFF" 3 "Reserved" ;
VAL_ 1167 ICC_UTURNMudSet 0 "Not Active" 1 "ON" 2 "OFF" 3 "Reserved" ;
VAL_ 1167 ICC_UTURNGrassSet 0 "Not Active" 1 "ON" 2 "OFF" 3 "Reserved" ;
VAL_ 1167 ICC_RestoreDefaults_48Fh 0 "Not Active" 1 "ON" 2 "OFF" 3 "Reserved" ;
VAL_ 1167 ICC_LTCDispSet2 0 "Not Active" 1 "WLTC" 2 "CLTC" 3 "Reserved" ;
VAL_ 1167 ICC_SetSocManage 0 "NotActive" 1 "Default" 2 "SAVE" 3 "Auto" 4 "Charge" 5 "Reserved" 6 "Reserved" 7 "Reserved" ;
VAL_ 1326 ICC_DWDOnOff_Req 0 "Not Active" 1 "ON" 2 "OFF" 3 "Reserved" ;
VAL_ 1326 ICC_ContainerLightSet 0 "Not_Active" 1 "ON" 2 "OFF" 3 "reserved" ;
VAL_ 1331 ICC_RLSeatEasyEntryExitSet 0 "Not Active" 1 "ON" 2 "OFF" 3 "Not Used" ;
VAL_ 1331 ICC_RRSeatEasyEntryExitSet 0 "Not Active" 1 "ON" 2 "OFF" 3 "Not Used" ;
VAL_ 1331 ICC_RLMemoryRecoveryCmd 0 "Not Active" 1 "Save" 2 "Recover Manual" 3 "RecoverAuto" ;
VAL_ 1331 ICC_RRMemoryRecoveryCmd 0 "Not Active" 1 "Save" 2 "Recover Manual" 3 "RecoverAuto" ;
VAL_ 1331 ICC_RLSitPosnlocation 0 "Not Active" 1 "Location1" 2 "Location2" 3 "Location3" ;
VAL_ 1331 ICC_RRSitPosnlocation 0 "Not Active" 1 "Location1" 2 "Location2" 3 "Location3" ;
VAL_ 1331 ICC_CMSMDisplaySwitch 0 "Not active" 1 "ON" 2 "OFF" 3 "Reserved" ;
VAL_ 1331 ICC_CMSMDisplayAdjustmode 0 "Not active" 1 "NormalAngle" 2 "ViewAngle" 3 "Reserved" ;
VAL_ 1331 ICC_CMSMSetstandardSwitch 0 "Not active" 1 "ON" 2 "OFF" 3 "Reserved" ;
VAL_ 1331 ICC_LeftPedalControl 0 "Not active" 1 "Spread_LeftPedal" 2 "Retract_LeftPedal" 3 "Auto" ;
VAL_ 1331 ICC_RightPedalControl 0 "Not active" 1 "Spread_RightPedal" 2 "Retract_RightPedal" 3 "Auto" ;
VAL_ 1331 ICC_EPCEnable 0 "Not active" 1 "ON" 2 "OFF" 3 "Reserved" ;
VAL_ 1331 ICC_AMPKTVvoiceVolumeSet 0 "Not Active" 1 "0" 2 "1" 3 "2" 4 "3" 5 "4" 6 "5" 7 "6" 8 "7" 9 "8" 10 "9" 11 "10" 12 "11" 13 "12" 14 "13" 15 "14" 16 "15" 17 "16" 18 "17" 19 "18" 20 "19" 21 "20" 22 "21" 23 "22" 24 "23" 25 "24" 26 "25" 27 "26" 28 "27" 29 "28" 30 "29" 31 "30" 32 "31" 33 "Reserved" 34 "Reserved" 35 "Reserved" 36 "Reserved" 37 "Reserved" 38 "Reserved" 39 "Reserved" 40 "Reserved" 41 "Reserved" 42 "Reserved" 43 "Reserved" 44 "Reserved" 45 "Reserved" 46 "Reserved" 47 "Reserved" 48 "Reserved" 49 "Reserved" 50 "Reserved" 51 "Reserved" 52 "Reserved" 53 "Reserved" 54 "Reserved" 55 "Reserved" 56 "Reserved" 57 "Reserved" 58 "Reserved" 59 "Reserved" 60 "Reserved" 61 "Reserved" 62 "Reserved" 63 "Reserved" ;
VAL_ 1331 ICC_AMPA2BENCSoundReq 0 "Not Active" 1 "ON" 2 "OFF" 3 "Reserved" ;
VAL_ 1331 ICC_AMPENCVolumeSet 0 "Not Active" 1 "0" 2 "1" 3 "2" 4 "3" 5 "4" 6 "5" 7 "6" 8 "7" 9 "8" 10 "9" 11 "10" 12 "11" 13 "12" 14 "13" 15 "14" 16 "15" 17 "16" 18 "17" 19 "18" 20 "19" 21 "20" 22 "21" 23 "22" 24 "23" 25 "24" 26 "25" 27 "26" 28 "27" 29 "28" 30 "29" 31 "30" 32 "31" 33 "Reserved" 34 "Reserved" 35 "Reserved" 36 "Reserved" 37 "Reserved" 38 "Reserved" 39 "Reserved" 40 "Reserved" 41 "Reserved" 42 "Reserved" 43 "Reserved" 44 "Reserved" 45 "Reserved" 46 "Reserved" 47 "Reserved" 48 "Reserved" 49 "Reserved" 50 "Reserved" 51 "Reserved" 52 "Reserved" 53 "Reserved" 54 "Reserved" 55 "Reserved" 56 "Reserved" 57 "Reserved" 58 "Reserved" 59 "Reserved" 60 "Reserved" 61 "Reserved" 62 "Reserved" 63 "Reserved" ;
VAL_ 1331 ICC_AMPA2BChimeSoundReq 0 "Not Active" 1 "ON" 2 "OFF" 3 "Reserved" ;
VAL_ 1331 Set_AMPSoundFocus_2 0 "Not Active" 1 "Customized" 2 "All" 3 "Driver" 4 "Sleep" 5 "VIP" 6 "FrontRow" 7 "BackRow" ;
VAL_ 1331 ICC_AMPA2BKTVvoiceSoundReq 0 "Not Active" 1 "IESS OFF and KTV OFF（默认值)" 2 "IESS OFF and KTV ON" 3 "IESS ON and KTV OFF" 4 "IESS ON and KTV ON" ;
VAL_ 1331 ICC_MedStatusSet 0 "Not Active" 1 "ON" 2 "OFF" 3 "Not Used" ;
VAL_ 1331 Set_AMPLoudness 0 "Not Active" 1 "ON" 2 "OFF" 3 "Reserved" ;
VAL_ 1331 ICC_MedAreaSet 0 "Not Active" 1 "Front Left" 2 "Front Right" 3 "Front Left and Right" 4 "2Row Left" 5 "2Row Right" 6 "2Row Left and 2Row Right" 7 "Front Left and 2Row Right" 8 "Front Right and 2Row Left" 9 "Front Left and 2Row Left" 10 "Front Right and 2Row Right" ;
VAL_ 1331 ICC_LeftElectricPedalsSet 0 "Not active" 1 "Open" 2 "Close" 3 "Reserved" ;
VAL_ 1331 ICC_RightElectricPedalsSet 0 "Not active" 1 "Open" 2 "Close" 3 "Reserved" ;
VAL_ 1331 ICC_NapAreaSet2 0 "Not Active" 1 "2Row Left" 2 "2Row Right" 3 "2Row Left and Right" 4 "Front Left and 2Row Right" 5 "Front Right and 2Row Left" 6 "Front Left and 2Row Left" 7 "Front Right and 2Row Right" ;
VAL_ 1331 ICC_DisplayAdjustrAngReq 0 "Not active" ;
VAL_ 1331 Set_AMPKeyVolume 0 "Not Active" 1 "0" 2 "1" 3 "2" 4 "3" 5 "4" 6 "5" 7 "6" 8 "7" 9 "8" 10 "9" 11 "10" 12 "11" 13 "12" 14 "13" 15 "14" 16 "15" 17 "16" 18 "17" 19 "18" 20 "19" 21 "20" 22 "21" 23 "22" 24 "23" 25 "24" 26 "25" 27 "26" 28 "27" 29 "28" 30 "29" 31 "30" 32 "31" 33 "Reserved" 34 "Reserved" 35 "Reserved" 36 "Reserved" 37 "Reserved" 38 "Reserved" 39 "Reserved" 40 "Reserved" 41 "Reserved" 42 "Reserved" 43 "Reserved" 44 "Reserved" 45 "Reserved" 46 "Reserved" 47 "Reserved" 48 "Reserved" 49 "Reserved" 50 "Reserved" 51 "Reserved" 52 "Reserved" 53 "Reserved" 54 "Reserved" 55 "Reserved" 56 "Reserved" 57 "Reserved" 58 "Reserved" 59 "Reserved" 60 "Reserved" 61 "Reserved" 62 "Reserved" 63 "Reserved" ;
VAL_ 1331 ICC_CMSMTouchSts 0 "Not active" 1 "Touch" 2 "No Touch" 3 "Reserved" ;
VAL_ 1331 Set_AMPExSoundmode 0 "Not Active" 1 "Soundmode1" 2 "Soundmode2" 3 "Soundmode3" 4 "OFF" 5 "Reserved" 6 "Reserved" 7 "Reserved" ;
VAL_ 1331 Set_AMPA2BENCSound 0 "Not Active" 1 "FL+FR+RL+SWF" 2 "FL+FR+SWF+RR" 3 "FL+FR+RL+RR" 4 "OFF" 5 "reserved" 6 "reserved" 7 "reserved" ;
VAL_ 1333 ICC_SRFCmd 0 "Not Active" 1 "Open" 2 "Close" 3 "Tilt" ;
VAL_ 1333 ICC_SRFPercentCmd 0 "Not Active" 1 "0" 2 "10%" 3 "20%" 4 "30%" 5 "40%" 6 "50%" 7 "60%" 8 "70%" 9 "80%" 10 "90%" 11 "100%" ;
VAL_ 1333 ICC_CSunshadeReq 0 "Not Active" 1 "Open" 2 "Close" 3 "Half_Open" ;
VAL_ 1333 ICC_CSunshadePercentReq 0 "Not Active" 1 "0%" 2 "10%" 3 "20%" 4 "30%" 5 "40%" 6 "50%" 7 "60%" 8 "70%" 9 "80%" 10 "90%" 11 "100%" ;
VAL_ 1333 ICC_SunshadeCmd 0 "Not Active" 1 "Open" 2 "Close" 3 "Half_Open" ;
VAL_ 1333 ICC_SunshadePercentCmd 0 "Not Active" 1 "0%" 2 "10%" 3 "20%" 4 "30%" 5 "40%" 6 "50%" 7 "60%" 8 "70%" 9 "80%" 10 "90%" 11 "100%" ;
VAL_ 1333 CSunshadeLearnedReq_535h 0 "Not Active" 1 "StartLearn" 2 "StopLearn" 3 "reserved" ;
VAL_ 1333 CSunshadePercentReq_535h 0 "No request" 1 "Sunshade 0%" 2 "Sunshade 1%" 3 "Sunshade 2%" 4 "Sunshade 3%" 5 "Sunshade 4%" 6 "Sunshade 5%" 7 "Sunshade 6%" 8 "Sunshade 7%" 9 "Sunshade 8%" 10 "Sunshade 9%" 11 "Sunshade 10%" 12 "Sunshade 11%" 13 "Sunshade 12%" 14 "Sunshade 13%" 15 "Sunshade 14%" 16 "Sunshade 15%" 17 "Sunshade 16%" 18 "Sunshade 17%" 19 "Sunshade 18%" 20 "Sunshade 19%" 21 "Sunshade 20%" 22 "Sunshade 21%" 23 "Sunshade 22%" 24 "Sunshade 23%" 25 "Sunshade 24%" 26 "Sunshade 25%" 27 "Sunshade 26%" 28 "Sunshade 27%" 29 "Sunshade 28%" 30 "Sunshade 29%" 31 "Sunshade 30%" 32 "Sunshade 31%" 33 "Sunshade 32%" 34 "Sunshade 33%" 35 "Sunshade 34%" 36 "Sunshade 35%" 37 "Sunshade 36%" 38 "Sunshade 37%" 39 "Sunshade 38%" 40 "Sunshade 39%" 41 "Sunshade 40%" 42 "Sunshade 41%" 43 "Sunshade 42%" 44 "Sunshade 43%" 45 "Sunshade 44%" 46 "Sunshade 45%" 47 "Sunshade 46%" 48 "Sunshade 47%" 49 "Sunshade 48%" 50 "Sunshade 49%" 51 "Sunshade 50%" 52 "Sunshade 51%" 53 "Sunshade 52%" 54 "Sunshade 53%" 55 "Sunshade 54%" 56 "Sunshade 55%" 57 "Sunshade 56%" 58 "Sunshade 57%" 59 "Sunshade 58%" 60 "Sunshade 59%" 61 "Sunshade 60%" 62 "Sunshade 61%" 63 "Sunshade 62%" 64 "Sunshade 63%" 65 "Sunshade 64%" 66 "Sunshade 65%" 67 "Sunshade 66%" 68 "Sunshade 67%" 69 "Sunshade 68%" 70 "Sunshade 69%" 71 "Sunshade 70%" 72 "Sunshade 71%" 73 "Sunshade 72%" 74 "Sunshade 73%" 75 "Sunshade 74%" 76 "Sunshade 75%" 77 "Sunshade 76%" 78 "Sunshade 77%" 79 "Sunshade 78%" 80 "Sunshade 79%" 81 "Sunshade 80%" 82 "Sunshade 81%" 83 "Sunshade 82%" 84 "Sunshade 83%" 85 "Sunshade 84%" 86 "Sunshade 85%" 87 "Sunshade 86%" 88 "Sunshade 87%" 89 "Sunshade 88%" 90 "Sunshade 89%" 91 "Sunshade 90%" 92 "Sunshade 91%" 93 "Sunshade 92%" 94 "Sunshade 93%" 95 "Sunshade 94%" 96 "Sunshade 95%" 97 "Sunshade 96%" 98 "Sunshade 97%" 99 "Sunshade 98%" 100 "Sunshade 99%" 101 "Sunshade 100%" 102 "Stop" 103 "initialize" 104 "Reserved" 105 "Reserved" 106 "Reserved" 107 "Reserved" 108 "Reserved" 109 "Reserved" 110 "Reserved" 111 "Reserved" 112 "Reserved" 113 "Reserved" 114 "Reserved" 115 "Reserved" 116 "Reserved" 117 "Reserved" 118 "Reserved" 119 "Reserved" 120 "Reserved" 121 "Reserved" 122 "Reserved" 123 "Reserved" 124 "Reserved" 125 "Reserved" 126 "Reserved" 127 "Reserved" 128 "Reserved" 129 "Reserved" 130 "Reserved" 131 "Reserved" 132 "Reserved" 133 "Reserved" 134 "Reserved" 135 "Reserved" 136 "Reserved" 137 "Reserved" 138 "Reserved" 139 "Reserved" 140 "Reserved" 141 "Reserved" 142 "Reserved" 143 "Reserved" 144 "Reserved" 145 "Reserved" 146 "Reserved" 147 "Reserved" 148 "Reserved" 149 "Reserved" 150 "Reserved" 151 "Reserved" 152 "Reserved" 153 "Reserved" 154 "Reserved" 155 "Reserved" 156 "Reserved" 157 "Reserved" 158 "Reserved" 159 "Reserved" 160 "Reserved" 161 "Reserved" 162 "Reserved" 163 "Reserved" 164 "Reserved" 165 "Reserved" 166 "Reserved" 167 "Reserved" 168 "Reserved" 169 "Reserved" 170 "Reserved" 171 "Reserved" 172 "Reserved" 173 "Reserved" 174 "Reserved" 175 "Reserved" 176 "Reserved" 177 "Reserved" 178 "Reserved" 179 "Reserved" 180 "Reserved" 181 "Reserved" 182 "Reserved" 183 "Reserved" 184 "Reserved" 185 "Reserved" 186 "Reserved" 187 "Reserved" 188 "Reserved" 189 "Reserved" 190 "Reserved" 191 "Reserved" 192 "Reserved" 193 "Reserved" 194 "Reserved" 195 "Reserved" 196 "Reserved" 197 "Reserved" 198 "Reserved" 199 "Reserved" 200 "Reserved" 201 "Reserved" 202 "Reserved" 203 "Reserved" 204 "Reserved" 205 "Reserved" 206 "Reserved" 207 "Reserved" 208 "Reserved" 209 "Reserved" 210 "Reserved" 211 "Reserved" 212 "Reserved" 213 "Reserved" 214 "Reserved" 215 "Reserved" 216 "Reserved" 217 "Reserved" 218 "Reserved" 219 "Reserved" 220 "Reserved" 221 "Reserved" 222 "Reserved" 223 "Reserved" 224 "Reserved" 225 "Reserved" 226 "Reserved" 227 "Reserved" 228 "Reserved" 229 "Reserved" 230 "Reserved" 231 "Reserved" 232 "Reserved" 233 "Reserved" 234 "Reserved" 235 "Reserved" 236 "Reserved" 237 "Reserved" 238 "Reserved" 239 "Reserved" 240 "Reserved" 241 "Reserved" 242 "Reserved" 243 "Reserved" 244 "Reserved" 245 "Reserved" 246 "Reserved" 247 "Reserved" 248 "Reserved" 249 "Reserved" 250 "Reserved" 251 "Reserved" 252 "Reserved" 253 "Reserved" 254 "Reserved" 255 "Reserved" ;
VAL_ 1335 ICC_SET_EPS_SteerReturnRmdSts 0 "Not Active" 1 "ON" 2 "OFF" 3 "reserved" ;
VAL_ 1335 ICC_SET_MFSShake 0 "Not Active" 1 "ON" 2 "OFF" 3 "reserved" ;
VAL_ 1335 ICC_DMS_1_DistractionLevel 0 "Not Active" 1 "DISTRACTION_LEVEL_LIGHT" 2 "DISTRACTION_LEVEL_MEDIUM" 3 "DISTRACTION_LEVEL_HEAVY" 4 "Reserved" 5 "Reserved" 6 "Reserved" 7 "Reserved" ;
VAL_ 1335 ICC_SET_EPS_AsociWithDrvModSts 0 "Not_Active" 1 "ON" 2 "OFF" 3 "reserved" ;
VAL_ 1335 ICC_OverLoadWarnShieldSet 0 "Not Active" 1 "ON" 2 "OFF" 3 "reserved" ;
VAL_ 1335 ICC_BSWReq 0 "Not Active" 1 "ON" 2 "OFF" 3 "reserved" ;
VAL_ 1335 ICC_horizontalReq 0 "Not Active" 1 "ON" 2 "OFF" 3 "Not Used" ;
VAL_ 1335 ICC_RolloverSetCmd 0 "Not Active" 1 "Rollover Deploy OFF" 2 "Rollover Deploy ON" 3 "reserved" ;
VAL_ 1335 ICC_TrekThroughReq_537h 0 "Not Active" 1 "ON" 2 "OFF" 3 "Reserved" ;
VAL_ 1335 ICC_InflateReq_537h 0 "Not Active" 1 "ON" 2 "OFF" 3 "Reserved" ;
VAL_ 1335 ICC_UndergroundModeReq_537h 0 "Not Active" 1 "ON" 2 "OFF" 3 "Reserved" ;
VAL_ 1337 ICC_SET_BT_ReduceWindSpeed 0 "Not_Active" 1 "ON" 2 "OFF" 3 "Reserved" ;
VAL_ 1337 ICC_SET_IPM_FirstBlowing 0 "Not Active" 1 "ON" 2 "OFF" 3 "Reserved" ;
VAL_ 1337 ICC_SET_IPM_BlowerDelay 0 "Not Active" 1 "ON" 2 "OFF" 3 "Reserved" ;
VAL_ 1337 ICC_SET_CirculationInTunnels 0 "Not Active" 1 "ON" 2 "OFF" 3 "Reserved" ;
VAL_ 1337 ICC_UVCLuminanceReq 0 "Not Active" 1 "high" 2 "lower" 3 "reserved" ;
VAL_ 1337 ICC_UVCControlReq 0 "Not Active" 1 "ON" 2 "OFF" 3 "AUTO" ;
VAL_ 1337 ICC_CrossCountryCoolingReq 0 "Not Active" 1 "ON" 2 "OFF" 3 "Reserved" ;
VAL_ 1337 ICC_KeepWarmReq 0 "Not Active" 1 "Open_AC" 2 "Open_NotAC" 3 "Closed" ;
VAL_ 1337 ICC_keepwarmSetTemperatureReq 0 "Not Active" 1 "Temperature 20°C" 2 "Temperature 25°C" 3 "Temperature 30°C" 4 "Temperature 35°C" 5 "Temperature 40°C" 6 "Temperature 45°C" 7 "Temperature 50°C" 8 "Temperature 55°C" 9 "Temperature 60°C" ;
VAL_ 1337 ICC_ParkingAirConditioning 0 "Not Active" 1 "Disable" 2 "AUTO" 3 "ventilate" ;
VAL_ 1337 ICC_CoolantFill_Req 0 "Not Active" 1 "ON" 2 "OFF" 3 "Reserved" ;
VAL_ 1337 ICC_FraganceLightoffReq 0 "No Active" 1 "FraganceLight_on" 2 "FraganceLight_off" 3 "Reserved" ;
VAL_ 1337 ICC_FraganceMemoffReq 0 "Not_Active" 1 "FraganceMem_on" 2 "FraganceMem_off" 3 "Reserved" ;
VAL_ 1337 ICC_CFSCycleLevel 0 "Not_Active" 1 "CFSCycle level1" 2 "CFSCycle level2" 3 "CFSCycle level3" 4 "CFSCycle level4" 5 "reserved" 6 "reserved" 7 "reserved" ;
VAL_ 1337 ICC_TimingLevel 0 "Not_Active" 1 "CFSTiming level1" 2 "CFSTiming level2" 3 "CFSTiming level3" 4 "CFSTiming level4" 5 "reserved" 6 "reserved" 7 "reserved" ;
VAL_ 1337 ICC_ModeAdjustDisplaySts 0 "BlowFace" 1 "BlowFaceAndBlowFoot" 2 "BlowFoot" 3 "BlowFootAndBlowWindow" 4 "BlowWindow" 5 "Not Active" 6 "BlowFaceAndBlowWindow" 7 "BlowFaceAndBlowFootAndBlowWindow" 8 "Auto" 9 "reserved" 10 "reserved" 11 "reserved" 12 "reserved" 13 "reserved" 14 "reserved" 15 "reserved" ;
VAL_ 1337 ICC_AirPurgeReminderReq 0 "Not_Active" 1 "ON" 2 "OFF" 3 "Not_Used" ;
VAL_ 1337 ICC_BiochemicalFuncReq 0 "Not Active" 1 "ON" 2 "OFF" 3 "Reserved" ;
VAL_ 1337 ICC_TimedVentilationReq 0 "Not Active" 1 "ON" 2 "OFF" 3 "Reserved" ;
VAL_ 1337 ICC_PetmodeSetTemperature_L_C 31 "Not active" ;
VAL_ 1337 ICC_PetModeSetTemperature_R_C 31 "Not active" ;
VAL_ 1337 ICC_PetModeSetCLMOn 0 "Not Active" 1 "On" 2 "Off" 3 "Not Used" ;
VAL_ 1337 ICC_PetModeSetAutoKeySts 0 "Not Active" 1 "On" 2 "Off" 3 "Not Used" ;
VAL_ 1337 ICC_PetModeSetCirculationSts 0 "Not Active" 1 "Recirculation mode" 2 "Air circulation mode" 3 "Two-Layer Flow Mode" ;
VAL_ 1337 ICC_ISSFctCmd_539h 0 "Not Active" 1 "ON" 2 "OFF" 3 "Not Used" ;
VAL_ 1318 ICC_SET_TDL_Rhythm_Switch 0 "Not_Active" 1 "ON" 2 "OFF" 3 "reserved" ;
VAL_ 1318 ICC_SET_TDL_Switch 0 "Not_Active" 1 "ON" 2 "OFF" 3 "reserved" ;
VAL_ 1318 ICC_SET_TDL_ColourModeAdj 0 "Not_Active" 1 "Monochrome" 2 "panchromatic" 3 "OFF" 4 "Reserved" 5 "Reserved" 6 "Reserved" 7 "Reserved" ;
VAL_ 1318 ICC_VoiceWake 0 "Not_Active" 1 "ON" 2 "OFF" 3 "LHFawaken" 4 "LHRawaken" 5 "RHFawaken" 6 "RHRawaken" 7 "Reserved" ;
VAL_ 1318 ICC_TDLAssociatedDriverModeSw 0 "Not_Active" 1 "ON" 2 "OFF" 3 "reserved" ;
VAL_ 1318 ICC_TDL_RhythmReq 0 "Not_Active" 1 "Mode1" 2 "Mode2" 3 "Mode3" 4 "Mode4" 5 "Mode5" 6 "Mode6" 7 "Reserved" ;
VAL_ 1318 ICC_SET_ApiluminanceAdj 0 "Not_Active" 1 "Level1" 2 "Level2" 3 "Level3" 4 "Level4" 5 "Level5" 6 "Level6" 7 "Level7" 8 "Level8" 9 "Reserved" 10 "Reserved" 11 "Reserved" 12 "Reserved" 13 "Reserved" 14 "Reserved" 15 "Reserved" ;
VAL_ 1318 ICC_SET_MusicLoudness_120HZ 0 "Not_Active" 1 "Level_1" 2 "Level_2" 3 "Level_3" 4 "Level_4" 5 "Level_5" 6 "Level_6" 7 "Level_7" 8 "Level_8" 9 "Level_9" 10 "Level_10" 11 "Level_11" 12 "Level_12" 13 "Level_13" 14 "Level_14" 15 "Level_15" ;
VAL_ 1318 ICC_SET_MusicLoudness_250HZ 0 "Not_Active" 1 "Level_1" 2 "Level_2" 3 "Level_3" 4 "Level_4" 5 "Level_5" 6 "Level_6" 7 "Level_7" 8 "Level_8" 9 "Level_9" 10 "Level_10" 11 "Level_11" 12 "Level_12" 13 "Level_13" 14 "Level_14" 15 "Level_15" ;
VAL_ 1318 ICC_SET_MusicLoudness_500HZ 0 "Not_Active" 1 "Level_1" 2 "Level_2" 3 "Level_3" 4 "Level_4" 5 "Level_5" 6 "Level_6" 7 "Level_7" 8 "Level_8" 9 "Level_9" 10 "Level_10" 11 "Level_11" 12 "Level_12" 13 "Level_13" 14 "Level_14" 15 "Level_15" ;
VAL_ 1318 ICC_SET_MusicLoudness_1000HZ 0 "Not_Active" 1 "Level_1" 2 "Level_2" 3 "Level_3" 4 "Level_4" 5 "Level_5" 6 "Level_6" 7 "Level_7" 8 "Level_8" 9 "Level_9" 10 "Level_10" 11 "Level_11" 12 "Level_12" 13 "Level_13" 14 "Level_14" 15 "Level_15" ;
VAL_ 1318 ICC_SET_MusicLoudness_1500HZ 0 "Not_Active" 1 "Level_1" 2 "Level_2" 3 "Level_3" 4 "Level_4" 5 "Level_5" 6 "Level_6" 7 "Level_7" 8 "Level_8" 9 "Level_9" 10 "Level_10" 11 "Level_11" 12 "Level_12" 13 "Level_13" 14 "Level_14" 15 "Level_15" ;
VAL_ 1318 ICC_SET_MusicLoudness_2000HZ 0 "Not_Active" 1 "Level_1" 2 "Level_2" 3 "Level_3" 4 "Level_4" 5 "Level_5" 6 "Level_6" 7 "Level_7" 8 "Level_8" 9 "Level_9" 10 "Level_10" 11 "Level_11" 12 "Level_12" 13 "Level_13" 14 "Level_14" 15 "Level_15" ;
VAL_ 1318 ICC_SET_MusicLoudness_6000HZ 0 "Not_Active" 1 "Level_1" 2 "Level_2" 3 "Level_3" 4 "Level_4" 5 "Level_5" 6 "Level_6" 7 "Level_7" 8 "Level_8" 9 "Level_9" 10 "Level_10" 11 "Level_11" 12 "Level_12" 13 "Level_13" 14 "Level_14" 15 "Level_15" ;
VAL_ 1318 ICC_TDL_FlowLightSw 0 "Not_Active" 1 "ON" 2 "OFF" 3 "reserved" ;
VAL_ 1318 ICC_TDL_FlowLightModeAdj 0 "Not Active" 1 "mode1" 2 "mode2" 3 "mode3" 4 "mode4" 5 "mode5" 6 "mode6" 7 "Reserved" ;
VAL_ 1320 ICC_Chb_Req 0 "Not Active" 1 "Chb_ON" 2 "Chb_OFF" 3 "reserved" ;
VAL_ 1320 ICC_ChbMem_Req 0 "Not Active" 1 "ChbMem_ON" 2 "ChbMem_OFF" 3 "reserved" ;
VAL_ 1320 ICC_ChbDelay_Req 0 "Not Active" 1 "ChbDelay_ON" 2 "ChbDelay_OFF" 3 "reserved" ;
VAL_ 1320 ICC_ChbSterilization_Req 0 "Not Active" 1 "Chbsterilize_ON" 2 "Chbsterilize_OFF" 3 "reserved" ;
VAL_ 1320 ICC_ChbItemsLeft_Req 0 "Not Active" 1 "Chbhanddown_ON" 2 "Chbhanddown_OFF" 3 "reserved" ;
VAL_ 1320 ICC_ParkingRadarSwSet 0 "Not active" 1 "ON" 2 "OFF" 3 "Reserved" ;
VAL_ 1320 ICC_ChbCoolset_Req 0 "Not_Active" 1 "ChbCoolset_-6" 2 "ChbCoolset_-5" 3 "ChbCoolset_-4" 4 "ChbCoolset_-3" 5 "ChbCoolset_-2" 6 "ChbCoolset_-1" 7 "ChbCoolset_0" 8 "ChbCoolset_1" 9 "ChbCoolset_2" 10 "ChbCoolset_3" 11 "ChbCoolset_4" 12 "ChbCoolset_5" 13 "ChbCoolset_6" 14 "ChbCoolset_-18" 15 "ChbCoolset_-17" 16 "ChbCoolset_-16" 17 "ChbCoolset_-15" 18 "ChbCoolset_-14" 19 "ChbCoolset_-13" 20 "ChbCoolset_-12" 21 "ChbCoolset_-11" 22 "ChbCoolset_-10" 23 "ChbCoolset_-9" 24 "ChbCoolset_-8" 25 "ChbCoolset_-7" 26 "Reserved" 27 "Reserved" 28 "Reserved" 29 "Reserved" 30 "Reserved" 31 "Reserved" ;
VAL_ 1320 ICC_ChbCoolorheat_Req 0 "NotActive" 1 "ChbCool_on" 2 "ChbHeat_on" 3 "Close" 4 "ColdDrinkMode" 5 "IceCreamMode" 6 "WarmMilkMode" 7 "WarmDrinkMode" ;
VAL_ 1320 ICC_ChbHeatset_Req 0 "Not Active" 1 "ChbHeatset_35" 2 "ChbHeatset_36" 3 "ChbHeatset_37" 4 "ChbHeatset_38" 5 "ChbHeatset_39" 6 "ChbHeatset_40" 7 "ChbHeatset_41" 8 "ChbHeatset_42" 9 "ChbHeatset_43" 10 "ChbHeatset_44" 11 "ChbHeatset_45" 12 "ChbHeatset_46" 13 "ChbHeatset_47" 14 "ChbHeatset_48" 15 "ChbHeatset_49" 16 "ChbHeatset_50" ;
VAL_ 1360 ICC_LISD_DisplaySwitch 0 "Default value" 1 "Display ON" 2 "Display OFF" 3 "Reserved" ;
VAL_ 1360 ICC_LISD_ParkingShowCMD 0 "Default value" 1 "ON" 2 "OFF" 3 "Reserved" ;
VAL_ 1360 ICC_RISD_DisplaySwitch 0 "Default value" 1 "Display ON" 2 "Display OFF" 3 "Reserved" ;
VAL_ 1360 ICC_RISD_ParkingShowCMD 0 "Default value" 1 "ON" 2 "OFF" 3 "Reserved" ;
VAL_ 1360 ICC_LogoParkingReq 0 "Not Active" 1 "ON" 2 "OFF" 3 "Reserved" ;
VAL_ 1360 ICC_LogoChargingReq 0 "Not Active" 1 "ON" 2 "OFF" 3 "Reserved" ;
VAL_ 1360 ICC_DRLSw 0 "Not active" 1 "ON" 2 "OFF" 3 "Reserved" ;
VAL_ 1360 ICC_LISD_ParkingShowMod 0 "Default value" 1 "Mode1" 2 "Mode2" 3 "Mode3" 4 "Mode4" 5 "Reserved" 6 "Reserved" 7 "Reserved" 8 "Reserved" 9 "Reserved" 10 "Reserved" 11 "Reserved" 12 "Reserved" 13 "Reserved" 14 "Reserved" 15 "Reserved" ;
VAL_ 1360 ICC_RISD_ParkingShowMod 0 "Default value" 1 "Mode1" 2 "Mode2" 3 "Mode3" 4 "Mode4" 5 "Reserved" 6 "Reserved" 7 "Reserved" 8 "Reserved" 9 "Reserved" 10 "Reserved" 11 "Reserved" 12 "Reserved" 13 "Reserved" 14 "Reserved" 15 "Reserved" ;
VAL_ 1360 ICC_PenetrationLampSetF 0 "Not_Active" 1 "ON" 2 "OFF" 3 "reserved" ;
VAL_ 1360 ICC_MusicLampShowSW 0 "Not active" 1 "OFF" 2 "ON" 3 "Reserved" ;
VAL_ 1360 ICC_LogoColorReq 0 "Not_Active" ;
VAL_ 1360 ICC_XDriveMode 0 "Not Active" 1 "unidentifiable" 2 "Normal" 3 "SNOW" 4 "MUD" 5 "ROCK" 6 "SAND" 7 "WATERSURFACE" 8 "Normal" 9 "SNOW" 10 "MUD" 11 "ROCK" 12 "SAND" 13 "WATERSURFACE" 14 "Normal" 15 "SNOW" 16 "MUD" 17 "ROCK" 18 "SAND" 19 "Reserved" 20 "Reserved" 21 "Reserved" 22 "Reserved" 23 "Reserved" 24 "Reserved" 25 "Reserved" 26 "Reserved" 27 "Reserved" 28 "Reserved" 29 "Reserved" 30 "Reserved" 31 "Reserved" ;
VAL_ 1360 ICC_DowWaringSw 0 "Not_Active" 1 "ON" 2 "OFF" 3 "reserved" ;
VAL_ 1360 ICC_CarSearhSetSwitchSts 0 "Not Active" 1 "Only Lighting" 2 "Sound and Lighting" 3 "Reserved" ;
VAL_ 1362 ICC_LISD_FrameCounter 0 "FrameCounter 0" 1 "FrameCounter 1" 2 "FrameCounter 2" 3 "FrameCounter 3" ;
VAL_ 1362 ICC_LISD_RollingCounter 0 "Counter 0" 1 "Counter 1" 2 "Counter 2" 3 "Reserved" ;
VAL_ 1362 ICC_LISD_Pixel1_OnOff 0 "Pixel On" 1 "Pixel Off" ;
VAL_ 1362 ICC_LISD_Pixel2_OnOff 0 "Pixel On" 1 "Pixel Off" ;
VAL_ 1362 ICC_LISD_Pixel3_OnOff 0 "Pixel On" 1 "Pixel Off" ;
VAL_ 1362 ICC_LISD_Pixel4_OnOff 0 "Pixel On" 1 "Pixel Off" ;
VAL_ 1362 ICC_LISD_Pixel5_OnOff 0 "Pixel On" 1 "Pixel Off" ;
VAL_ 1362 ICC_LISD_Pixel6_OnOff 0 "Pixel On" 1 "Pixel Off" ;
VAL_ 1362 ICC_LISD_Pixel7_OnOff 0 "Pixel On" 1 "Pixel Off" ;
VAL_ 1362 ICC_LISD_Pixel8_OnOff 0 "Pixel On" 1 "Pixel Off" ;
VAL_ 1362 ICC_LISD_Pixel9_OnOff 0 "Pixel On" 1 "Pixel Off" ;
VAL_ 1362 ICC_LISD_Pixel10_OnOff 0 "Pixel On" 1 "Pixel Off" ;
VAL_ 1362 ICC_LISD_Pixel11_OnOff 0 "Pixel On" 1 "Pixel Off" ;
VAL_ 1362 ICC_LISD_Pixel12_OnOff 0 "Pixel On" 1 "Pixel Off" ;
VAL_ 1362 ICC_LISD_Pixel13_OnOff 0 "Pixel On" 1 "Pixel Off" ;
VAL_ 1362 ICC_LISD_Pixel14_OnOff 0 "Pixel On" 1 "Pixel Off" ;
VAL_ 1362 ICC_LISD_Pixel15_OnOff 0 "Pixel On" 1 "Pixel Off" ;
VAL_ 1362 ICC_LISD_Pixel16_OnOff 0 "Pixel On" 1 "Pixel Off" ;
VAL_ 1362 ICC_LISD_Pixel17_OnOff 0 "Pixel On" 1 "Pixel Off" ;
VAL_ 1362 ICC_LISD_Pixel18_OnOff 0 "Pixel On" 1 "Pixel Off" ;
VAL_ 1362 ICC_LISD_Pixel19_OnOff 0 "Pixel On" 1 "Pixel Off" ;
VAL_ 1362 ICC_LISD_Pixel20_OnOff 0 "Pixel On" 1 "Pixel Off" ;
VAL_ 1362 ICC_LISD_Pixel21_OnOff 0 "Pixel On" 1 "Pixel Off" ;
VAL_ 1362 ICC_LISD_Pixel22_OnOff 0 "Pixel On" 1 "Pixel Off" ;
VAL_ 1362 ICC_LISD_Pixel23_OnOff 0 "Pixel On" 1 "Pixel Off" ;
VAL_ 1362 ICC_LISD_Pixel24_OnOff 0 "Pixel On" 1 "Pixel Off" ;
VAL_ 1362 ICC_LISD_Pixel25_OnOff 0 "Pixel On" 1 "Pixel Off" ;
VAL_ 1362 ICC_LISD_Pixel26_OnOff 0 "Pixel On" 1 "Pixel Off" ;
VAL_ 1362 ICC_LISD_Pixel27_OnOff 0 "Pixel On" 1 "Pixel Off" ;
VAL_ 1362 ICC_LISD_Pixel28_OnOff 0 "Pixel On" 1 "Pixel Off" ;
VAL_ 1362 ICC_LISD_Pixel29_OnOff 0 "Pixel On" 1 "Pixel Off" ;
VAL_ 1362 ICC_LISD_Pixel30_OnOff 0 "Pixel On" 1 "Pixel Off" ;
VAL_ 1362 ICC_LISD_Pixel31_OnOff 0 "Pixel On" 1 "Pixel Off" ;
VAL_ 1362 ICC_LISD_Pixel32_OnOff 0 "Pixel On" 1 "Pixel Off" ;
VAL_ 1362 ICC_LISD_Pixel33_OnOff 0 "Pixel On" 1 "Pixel Off" ;
VAL_ 1362 ICC_LISD_Pixel34_OnOff 0 "Pixel On" 1 "Pixel Off" ;
VAL_ 1362 ICC_LISD_Pixel35_OnOff 0 "Pixel On" 1 "Pixel Off" ;
VAL_ 1362 ICC_LISD_Pixel36_OnOff 0 "Pixel On" 1 "Pixel Off" ;
VAL_ 1362 ICC_LISD_Pixel37_OnOff 0 "Pixel On" 1 "Pixel Off" ;
VAL_ 1362 ICC_LISD_Pixel38_OnOff 0 "Pixel On" 1 "Pixel Off" ;
VAL_ 1362 ICC_LISD_Pixel39_OnOff 0 "Pixel On" 1 "Pixel Off" ;
VAL_ 1362 ICC_LISD_Pixel40_OnOff 0 "Pixel On" 1 "Pixel Off" ;
VAL_ 1362 ICC_LISD_Pixel41_OnOff 0 "Pixel On" 1 "Pixel Off" ;
VAL_ 1362 ICC_LISD_Pixel42_OnOff 0 "Pixel On" 1 "Pixel Off" ;
VAL_ 1362 ICC_LISD_Pixel43_OnOff 0 "Pixel On" 1 "Pixel Off" ;
VAL_ 1362 ICC_LISD_Pixel44_OnOff 0 "Pixel On" 1 "Pixel Off" ;
VAL_ 1362 ICC_LISD_Pixel45_OnOff 0 "Pixel On" 1 "Pixel Off" ;
VAL_ 1362 ICC_LISD_Pixel46_OnOff 0 "Pixel On" 1 "Pixel Off" ;
VAL_ 1362 ICC_LISD_Pixel47_OnOff 0 "Pixel On" 1 "Pixel Off" ;
VAL_ 1362 ICC_LISD_Pixel48_OnOff 0 "Pixel On" 1 "Pixel Off" ;
VAL_ 1362 ICC_LISD_Pixel49_OnOff 0 "Pixel On" 1 "Pixel Off" ;
VAL_ 1362 ICC_LISD_Pixel50_OnOff 0 "Pixel On" 1 "Pixel Off" ;
VAL_ 1362 ICC_LISD_Pixel51_OnOff 0 "Pixel On" 1 "Pixel Off" ;
VAL_ 1362 ICC_LISD_Pixel52_OnOff 0 "Pixel On" 1 "Pixel Off" ;
VAL_ 1362 ICC_LISD_Pixel53_OnOff 0 "Pixel On" 1 "Pixel Off" ;
VAL_ 1362 ICC_LISD_Pixel54_OnOff 0 "Pixel On" 1 "Pixel Off" ;
VAL_ 1362 ICC_LISD_Pixel55_OnOff 0 "Pixel On" 1 "Pixel Off" ;
VAL_ 1362 ICC_LISD_Pixel56_OnOff 0 "Pixel On" 1 "Pixel Off" ;
VAL_ 1362 ICC_LISD_Pixel57_OnOff 0 "Pixel On" 1 "Pixel Off" ;
VAL_ 1362 ICC_LISD_Pixel58_OnOff 0 "Pixel On" 1 "Pixel Off" ;
VAL_ 1362 ICC_LISD_Pixel59_OnOff 0 "Pixel On" 1 "Pixel Off" ;
VAL_ 1362 ICC_LISD_Pixel60_OnOff 0 "Pixel On" 1 "Pixel Off" ;
VAL_ 1362 ICC_LISD_Pixel61_OnOff 0 "Pixel On" 1 "Pixel Off" ;
VAL_ 1362 ICC_LISD_Pixel62_OnOff 0 "Pixel On" 1 "Pixel Off" ;
VAL_ 1362 ICC_LISD_Pixel63_OnOff 0 "Pixel On" 1 "Pixel Off" ;
VAL_ 1362 ICC_LISD_Pixel64_OnOff 0 "Pixel On" 1 "Pixel Off" ;
VAL_ 1362 ICC_LISD_Pixel65_OnOff 0 "Pixel On" 1 "Pixel Off" ;
VAL_ 1362 ICC_LISD_Pixel66_OnOff 0 "Pixel On" 1 "Pixel Off" ;
VAL_ 1362 ICC_LISD_Pixel67_OnOff 0 "Pixel On" 1 "Pixel Off" ;
VAL_ 1362 ICC_LISD_Pixel68_OnOff 0 "Pixel On" 1 "Pixel Off" ;
VAL_ 1362 ICC_LISD_Pixel69_OnOff 0 "Pixel On" 1 "Pixel Off" ;
VAL_ 1362 ICC_LISD_Pixel70_OnOff 0 "Pixel On" 1 "Pixel Off" ;
VAL_ 1362 ICC_LISD_Pixel71_OnOff 0 "Pixel On" 1 "Pixel Off" ;
VAL_ 1362 ICC_LISD_Pixel72_OnOff 0 "Pixel On" 1 "Pixel Off" ;
VAL_ 1362 ICC_LISD_Pixel73_OnOff 0 "Pixel On" 1 "Pixel Off" ;
VAL_ 1362 ICC_LISD_Pixel74_OnOff 0 "Pixel On" 1 "Pixel Off" ;
VAL_ 1362 ICC_LISD_Pixel75_OnOff 0 "Pixel On" 1 "Pixel Off" ;
VAL_ 1362 ICC_LISD_Pixel76_OnOff 0 "Pixel On" 1 "Pixel Off" ;
VAL_ 1362 ICC_LISD_Pixel77_OnOff 0 "Pixel On" 1 "Pixel Off" ;
VAL_ 1362 ICC_LISD_Pixel78_OnOff 0 "Pixel On" 1 "Pixel Off" ;
VAL_ 1362 ICC_LISD_Pixel79_OnOff 0 "Pixel On" 1 "Pixel Off" ;
VAL_ 1362 ICC_LISD_Pixel80_OnOff 0 "Pixel On" 1 "Pixel Off" ;
VAL_ 1362 ICC_LISD_Pixel81_OnOff 0 "Pixel On" 1 "Pixel Off" ;
VAL_ 1362 ICC_LISD_Pixel82_OnOff 0 "Pixel On" 1 "Pixel Off" ;
VAL_ 1362 ICC_LISD_Pixel83_OnOff 0 "Pixel On" 1 "Pixel Off" ;
VAL_ 1362 ICC_LISD_Pixel84_OnOff 0 "Pixel On" 1 "Pixel Off" ;
VAL_ 1362 ICC_LISD_Pixel85_OnOff 0 "Pixel On" 1 "Pixel Off" ;
VAL_ 1362 ICC_LISD_Pixel86_OnOff 0 "Pixel On" 1 "Pixel Off" ;
VAL_ 1362 ICC_LISD_Pixel87_OnOff 0 "Pixel On" 1 "Pixel Off" ;
VAL_ 1362 ICC_LISD_Pixel88_OnOff 0 "Pixel On" 1 "Pixel Off" ;
VAL_ 1362 ICC_LISD_Pixel89_OnOff 0 "Pixel On" 1 "Pixel Off" ;
VAL_ 1362 ICC_LISD_Pixel90_OnOff 0 "Pixel On" 1 "Pixel Off" ;
VAL_ 1362 ICC_LISD_Pixel91_OnOff 0 "Pixel On" 1 "Pixel Off" ;
VAL_ 1362 ICC_LISD_Pixel92_OnOff 0 "Pixel On" 1 "Pixel Off" ;
VAL_ 1362 ICC_LISD_Pixel93_OnOff 0 "Pixel On" 1 "Pixel Off" ;
VAL_ 1362 ICC_LISD_Pixel94_OnOff 0 "Pixel On" 1 "Pixel Off" ;
VAL_ 1362 ICC_LISD_Pixel95_OnOff 0 "Pixel On" 1 "Pixel Off" ;
VAL_ 1362 ICC_LISD_Pixel96_OnOff 0 "Pixel On" 1 "Pixel Off" ;
VAL_ 1362 ICC_LISD_Pixel97_OnOff 0 "Pixel On" 1 "Pixel Off" ;
VAL_ 1362 ICC_LISD_Pixel98_OnOff 0 "Pixel On" 1 "Pixel Off" ;
VAL_ 1362 ICC_LISD_Pixel99_OnOff 0 "Pixel On" 1 "Pixel Off" ;
VAL_ 1362 ICC_LISD_Pixel100_OnOff 0 "Pixel On" 1 "Pixel Off" ;
VAL_ 1362 ICC_LISD_Pixel101_OnOff 0 "Pixel On" 1 "Pixel Off" ;
VAL_ 1362 ICC_LISD_Pixel102_OnOff 0 "Pixel On" 1 "Pixel Off" ;
VAL_ 1362 ICC_LISD_Pixel103_OnOff 0 "Pixel On" 1 "Pixel Off" ;
VAL_ 1362 ICC_LISD_Pixel104_OnOff 0 "Pixel On" 1 "Pixel Off" ;
VAL_ 1362 ICC_LISD_Pixel105_OnOff 0 "Pixel On" 1 "Pixel Off" ;
VAL_ 1362 ICC_LISD_Pixel106_OnOff 0 "Pixel On" 1 "Pixel Off" ;
VAL_ 1362 ICC_LISD_Pixel107_OnOff 0 "Pixel On" 1 "Pixel Off" ;
VAL_ 1362 ICC_LISD_Pixel108_OnOff 0 "Pixel On" 1 "Pixel Off" ;
VAL_ 1362 ICC_LISD_Pixel109_OnOff 0 "Pixel On" 1 "Pixel Off" ;
VAL_ 1362 ICC_LISD_Pixel110_OnOff 0 "Pixel On" 1 "Pixel Off" ;
VAL_ 1362 ICC_LISD_Pixel111_OnOff 0 "Pixel On" 1 "Pixel Off" ;
VAL_ 1362 ICC_LISD_Pixel112_OnOff 0 "Pixel On" 1 "Pixel Off" ;
VAL_ 1362 ICC_LISD_Pixel113_OnOff 0 "Pixel On" 1 "Pixel Off" ;
VAL_ 1362 ICC_LISD_Pixel114_OnOff 0 "Pixel On" 1 "Pixel Off" ;
VAL_ 1362 ICC_LISD_Pixel115_OnOff 0 "Pixel On" 1 "Pixel Off" ;
VAL_ 1362 ICC_LISD_Pixel116_OnOff 0 "Pixel On" 1 "Pixel Off" ;
VAL_ 1362 ICC_LISD_Pixel117_OnOff 0 "Pixel On" 1 "Pixel Off" ;
VAL_ 1362 ICC_LISD_Pixel118_OnOff 0 "Pixel On" 1 "Pixel Off" ;
VAL_ 1362 ICC_LISD_Pixel119_OnOff 0 "Pixel On" 1 "Pixel Off" ;
VAL_ 1362 ICC_LISD_Pixel120_OnOff 0 "Pixel On" 1 "Pixel Off" ;
VAL_ 1362 ICC_LISD_Pixel121_OnOff 0 "Pixel On" 1 "Pixel Off" ;
VAL_ 1362 ICC_LISD_Pixel122_OnOff 0 "Pixel On" 1 "Pixel Off" ;
VAL_ 1362 ICC_LISD_Pixel123_OnOff 0 "Pixel On" 1 "Pixel Off" ;
VAL_ 1362 ICC_LISD_Pixel124_OnOff 0 "Pixel On" 1 "Pixel Off" ;
VAL_ 1362 ICC_LISD_Pixel125_OnOff 0 "Pixel On" 1 "Pixel Off" ;
VAL_ 1362 ICC_LISD_Pixel126_OnOff 0 "Pixel On" 1 "Pixel Off" ;
VAL_ 1362 ICC_LISD_Pixel127_OnOff 0 "Pixel On" 1 "Pixel Off" ;
VAL_ 1362 ICC_LISD_Pixel128_OnOff 0 "Pixel On" 1 "Pixel Off" ;
VAL_ 1362 ICC_LISD_Pixel129_OnOff 0 "Pixel On" 1 "Pixel Off" ;
VAL_ 1362 ICC_LISD_Pixel130_OnOff 0 "Pixel On" 1 "Pixel Off" ;
VAL_ 1362 ICC_LISD_Pixel131_OnOff 0 "Pixel On" 1 "Pixel Off" ;
VAL_ 1362 ICC_LISD_Pixel132_OnOff 0 "Pixel On" 1 "Pixel Off" ;
VAL_ 1362 ICC_LISD_Pixel133_OnOff 0 "Pixel On" 1 "Pixel Off" ;
VAL_ 1362 ICC_LISD_Pixel134_OnOff 0 "Pixel On" 1 "Pixel Off" ;
VAL_ 1362 ICC_LISD_Pixel135_OnOff 0 "Pixel On" 1 "Pixel Off" ;
VAL_ 1362 ICC_LISD_Pixel136_OnOff 0 "Pixel On" 1 "Pixel Off" ;
VAL_ 1362 ICC_LISD_Pixel137_OnOff 0 "Pixel On" 1 "Pixel Off" ;
VAL_ 1362 ICC_LISD_Pixel138_OnOff 0 "Pixel On" 1 "Pixel Off" ;
VAL_ 1362 ICC_LISD_Pixel139_OnOff 0 "Pixel On" 1 "Pixel Off" ;
VAL_ 1362 ICC_LISD_Pixel140_OnOff 0 "Pixel On" 1 "Pixel Off" ;
VAL_ 1362 ICC_LISD_Pixel141_OnOff 0 "Pixel On" 1 "Pixel Off" ;
VAL_ 1362 ICC_LISD_Pixel142_OnOff 0 "Pixel On" 1 "Pixel Off" ;
VAL_ 1362 ICC_LISD_Pixel143_OnOff 0 "Pixel On" 1 "Pixel Off" ;
VAL_ 1362 ICC_LISD_Pixel144_OnOff 0 "Pixel On" 1 "Pixel Off" ;
VAL_ 1362 ICC_LISD_Pixel145_OnOff 0 "Pixel On" 1 "Pixel Off" ;
VAL_ 1362 ICC_LISD_Pixel146_OnOff 0 "Pixel On" 1 "Pixel Off" ;
VAL_ 1362 ICC_LISD_Pixel147_OnOff 0 "Pixel On" 1 "Pixel Off" ;
VAL_ 1362 ICC_LISD_Pixel148_OnOff 0 "Pixel On" 1 "Pixel Off" ;
VAL_ 1362 ICC_LISD_Pixel149_OnOff 0 "Pixel On" 1 "Pixel Off" ;
VAL_ 1362 ICC_LISD_Pixel150_OnOff 0 "Pixel On" 1 "Pixel Off" ;
VAL_ 1362 ICC_LISD_Pixel151_OnOff 0 "Pixel On" 1 "Pixel Off" ;
VAL_ 1362 ICC_LISD_Pixel152_OnOff 0 "Pixel On" 1 "Pixel Off" ;
VAL_ 1362 ICC_LISD_Pixel153_OnOff 0 "Pixel On" 1 "Pixel Off" ;
VAL_ 1362 ICC_LISD_Pixel154_OnOff 0 "Pixel On" 1 "Pixel Off" ;
VAL_ 1362 ICC_LISD_Pixel155_OnOff 0 "Pixel On" 1 "Pixel Off" ;
VAL_ 1362 ICC_LISD_Pixel156_OnOff 0 "Pixel On" 1 "Pixel Off" ;
VAL_ 1362 ICC_LISD_Pixel157_OnOff 0 "Pixel On" 1 "Pixel Off" ;
VAL_ 1362 ICC_LISD_Pixel158_OnOff 0 "Pixel On" 1 "Pixel Off" ;
VAL_ 1362 ICC_LISD_Pixel159_OnOff 0 "Pixel On" 1 "Pixel Off" ;
VAL_ 1362 ICC_LISD_Pixel160_OnOff 0 "Pixel On" 1 "Pixel Off" ;
VAL_ 1362 ICC_LISD_Pixel161_OnOff 0 "Pixel On" 1 "Pixel Off" ;
VAL_ 1362 ICC_LISD_Pixel162_OnOff 0 "Pixel On" 1 "Pixel Off" ;
VAL_ 1362 ICC_LISD_Pixel163_OnOff 0 "Pixel On" 1 "Pixel Off" ;
VAL_ 1362 ICC_LISD_Pixel164_OnOff 0 "Pixel On" 1 "Pixel Off" ;
VAL_ 1362 ICC_LISD_Pixel165_OnOff 0 "Pixel On" 1 "Pixel Off" ;
VAL_ 1362 ICC_LISD_Pixel166_OnOff 0 "Pixel On" 1 "Pixel Off" ;
VAL_ 1362 ICC_LISD_Pixel167_OnOff 0 "Pixel On" 1 "Pixel Off" ;
VAL_ 1362 ICC_LISD_Pixel168_OnOff 0 "Pixel On" 1 "Pixel Off" ;
VAL_ 1362 ICC_LISD_Pixel169_OnOff 0 "Pixel On" 1 "Pixel Off" ;
VAL_ 1362 ICC_LISD_Pixel170_OnOff 0 "Pixel On" 1 "Pixel Off" ;
VAL_ 1362 ICC_LISD_Pixel171_OnOff 0 "Pixel On" 1 "Pixel Off" ;
VAL_ 1362 ICC_LISD_Pixel172_OnOff 0 "Pixel On" 1 "Pixel Off" ;
VAL_ 1362 ICC_LISD_Pixel173_OnOff 0 "Pixel On" 1 "Pixel Off" ;
VAL_ 1362 ICC_LISD_Pixel174_OnOff 0 "Pixel On" 1 "Pixel Off" ;
VAL_ 1362 ICC_LISD_Pixel175_OnOff 0 "Pixel On" 1 "Pixel Off" ;
VAL_ 1362 ICC_LISD_Pixel176_OnOff 0 "Pixel On" 1 "Pixel Off" ;
VAL_ 1362 ICC_LISD_Pixel177_OnOff 0 "Pixel On" 1 "Pixel Off" ;
VAL_ 1362 ICC_LISD_Pixel178_OnOff 0 "Pixel On" 1 "Pixel Off" ;
VAL_ 1362 ICC_LISD_Pixel179_OnOff 0 "Pixel On" 1 "Pixel Off" ;
VAL_ 1362 ICC_LISD_Pixel180_OnOff 0 "Pixel On" 1 "Pixel Off" ;
VAL_ 1362 ICC_LISD_Pixel181_OnOff 0 "Pixel On" 1 "Pixel Off" ;
VAL_ 1362 ICC_LISD_Pixel182_OnOff 0 "Pixel On" 1 "Pixel Off" ;
VAL_ 1362 ICC_LISD_Pixel183_OnOff 0 "Pixel On" 1 "Pixel Off" ;
VAL_ 1362 ICC_LISD_Pixel184_OnOff 0 "Pixel On" 1 "Pixel Off" ;
VAL_ 1362 ICC_LISD_Pixel185_OnOff 0 "Pixel On" 1 "Pixel Off" ;
VAL_ 1362 ICC_LISD_Pixel186_OnOff 0 "Pixel On" 1 "Pixel Off" ;
VAL_ 1362 ICC_LISD_Pixel187_OnOff 0 "Pixel On" 1 "Pixel Off" ;
VAL_ 1362 ICC_LISD_Pixel188_OnOff 0 "Pixel On" 1 "Pixel Off" ;
VAL_ 1362 ICC_LISD_Pixel189_OnOff 0 "Pixel On" 1 "Pixel Off" ;
VAL_ 1362 ICC_LISD_Pixel190_OnOff 0 "Pixel On" 1 "Pixel Off" ;
VAL_ 1362 ICC_LISD_Pixel191_OnOff 0 "Pixel On" 1 "Pixel Off" ;
VAL_ 1362 ICC_LISD_Pixel192_OnOff 0 "Pixel On" 1 "Pixel Off" ;
VAL_ 1362 ICC_LISD_Pixel193_OnOff 0 "Pixel On" 1 "Pixel Off" ;
VAL_ 1362 ICC_LISD_Pixel194_OnOff 0 "Pixel On" 1 "Pixel Off" ;
VAL_ 1362 ICC_LISD_Pixel195_OnOff 0 "Pixel On" 1 "Pixel Off" ;
VAL_ 1362 ICC_LISD_Pixel196_OnOff 0 "Pixel On" 1 "Pixel Off" ;
VAL_ 1362 ICC_LISD_Pixel197_OnOff 0 "Pixel On" 1 "Pixel Off" ;
VAL_ 1362 ICC_LISD_Pixel198_OnOff 0 "Pixel On" 1 "Pixel Off" ;
VAL_ 1362 ICC_LISD_Pixel199_OnOff 0 "Pixel On" 1 "Pixel Off" ;
VAL_ 1362 ICC_LISD_Pixel200_OnOff 0 "Pixel On" 1 "Pixel Off" ;
VAL_ 1362 ICC_LISD_Pixel201_OnOff 0 "Pixel On" 1 "Pixel Off" ;
VAL_ 1362 ICC_LISD_Pixel202_OnOff 0 "Pixel On" 1 "Pixel Off" ;
VAL_ 1362 ICC_LISD_Pixel203_OnOff 0 "Pixel On" 1 "Pixel Off" ;
VAL_ 1362 ICC_LISD_Pixel204_OnOff 0 "Pixel On" 1 "Pixel Off" ;
VAL_ 1362 ICC_LISD_Pixel205_OnOff 0 "Pixel On" 1 "Pixel Off" ;
VAL_ 1362 ICC_LISD_Pixel206_OnOff 0 "Pixel On" 1 "Pixel Off" ;
VAL_ 1362 ICC_LISD_Pixel207_OnOff 0 "Pixel On" 1 "Pixel Off" ;
VAL_ 1362 ICC_LISD_Pixel208_OnOff 0 "Pixel On" 1 "Pixel Off" ;
VAL_ 1362 ICC_LISD_Pixel209_OnOff 0 "Pixel On" 1 "Pixel Off" ;
VAL_ 1362 ICC_LISD_Pixel210_OnOff 0 "Pixel On" 1 "Pixel Off" ;
VAL_ 1362 ICC_LISD_Pixel211_OnOff 0 "Pixel On" 1 "Pixel Off" ;
VAL_ 1362 ICC_LISD_Pixel212_OnOff 0 "Pixel On" 1 "Pixel Off" ;
VAL_ 1362 ICC_LISD_Pixel213_OnOff 0 "Pixel On" 1 "Pixel Off" ;
VAL_ 1362 ICC_LISD_Pixel214_OnOff 0 "Pixel On" 1 "Pixel Off" ;
VAL_ 1362 ICC_LISD_Pixel215_OnOff 0 "Pixel On" 1 "Pixel Off" ;
VAL_ 1362 ICC_LISD_Pixel216_OnOff 0 "Pixel On" 1 "Pixel Off" ;
VAL_ 1362 ICC_LISD_Pixel217_OnOff 0 "Pixel On" 1 "Pixel Off" ;
VAL_ 1362 ICC_LISD_Pixel218_OnOff 0 "Pixel On" 1 "Pixel Off" ;
VAL_ 1362 ICC_LISD_Pixel219_OnOff 0 "Pixel On" 1 "Pixel Off" ;
VAL_ 1362 ICC_LISD_Pixel220_OnOff 0 "Pixel On" 1 "Pixel Off" ;
VAL_ 1362 ICC_LISD_Pixel221_OnOff 0 "Pixel On" 1 "Pixel Off" ;
VAL_ 1362 ICC_LISD_Pixel222_OnOff 0 "Pixel On" 1 "Pixel Off" ;
VAL_ 1362 ICC_LISD_Pixel223_OnOff 0 "Pixel On" 1 "Pixel Off" ;
VAL_ 1362 ICC_LISD_Pixel224_OnOff 0 "Pixel On" 1 "Pixel Off" ;
VAL_ 1362 ICC_LISD_Pixel225_OnOff 0 "Pixel On" 1 "Pixel Off" ;
VAL_ 1362 ICC_LISD_Pixel226_OnOff 0 "Pixel On" 1 "Pixel Off" ;
VAL_ 1362 ICC_LISD_Pixel227_OnOff 0 "Pixel On" 1 "Pixel Off" ;
VAL_ 1362 ICC_LISD_Pixel228_OnOff 0 "Pixel On" 1 "Pixel Off" ;
VAL_ 1362 ICC_LISD_Pixel229_OnOff 0 "Pixel On" 1 "Pixel Off" ;
VAL_ 1362 ICC_LISD_Pixel230_OnOff 0 "Pixel On" 1 "Pixel Off" ;
VAL_ 1362 ICC_LISD_Pixel231_OnOff 0 "Pixel On" 1 "Pixel Off" ;
VAL_ 1362 ICC_LISD_Pixel232_OnOff 0 "Pixel On" 1 "Pixel Off" ;
VAL_ 1362 ICC_LISD_Pixel233_OnOff 0 "Pixel On" 1 "Pixel Off" ;
VAL_ 1362 ICC_LISD_Pixel234_OnOff 0 "Pixel On" 1 "Pixel Off" ;
VAL_ 1362 ICC_LISD_Pixel235_OnOff 0 "Pixel On" 1 "Pixel Off" ;
VAL_ 1362 ICC_LISD_Pixel236_OnOff 0 "Pixel On" 1 "Pixel Off" ;
VAL_ 1362 ICC_LISD_Pixel237_OnOff 0 "Pixel On" 1 "Pixel Off" ;
VAL_ 1362 ICC_LISD_Pixel238_OnOff 0 "Pixel On" 1 "Pixel Off" ;
VAL_ 1362 ICC_LISD_Pixel239_OnOff 0 "Pixel On" 1 "Pixel Off" ;
VAL_ 1362 ICC_LISD_Pixel240_OnOff 0 "Pixel On" 1 "Pixel Off" ;
VAL_ 1362 ICC_LISD_Pixel241_OnOff 0 "Pixel On" 1 "Pixel Off" ;
VAL_ 1362 ICC_LISD_Pixel242_OnOff 0 "Pixel On" 1 "Pixel Off" ;
VAL_ 1362 ICC_LISD_Pixel243_OnOff 0 "Pixel On" 1 "Pixel Off" ;
VAL_ 1362 ICC_LISD_Pixel244_OnOff 0 "Pixel On" 1 "Pixel Off" ;
VAL_ 1362 ICC_LISD_Pixel245_OnOff 0 "Pixel On" 1 "Pixel Off" ;
VAL_ 1362 ICC_LISD_Pixel246_OnOff 0 "Pixel On" 1 "Pixel Off" ;
VAL_ 1362 ICC_LISD_Pixel247_OnOff 0 "Pixel On" 1 "Pixel Off" ;
VAL_ 1362 ICC_LISD_Pixel248_OnOff 0 "Pixel On" 1 "Pixel Off" ;
VAL_ 1362 ICC_LISD_Pixel249_OnOff 0 "Pixel On" 1 "Pixel Off" ;
VAL_ 1362 ICC_LISD_Pixel250_OnOff 0 "Pixel On" 1 "Pixel Off" ;
VAL_ 1362 ICC_LISD_Pixel251_OnOff 0 "Pixel On" 1 "Pixel Off" ;
VAL_ 1362 ICC_LISD_Pixel252_OnOff 0 "Pixel On" 1 "Pixel Off" ;
VAL_ 1362 ICC_LISD_Pixel253_OnOff 0 "Pixel On" 1 "Pixel Off" ;
VAL_ 1362 ICC_LISD_Pixel254_OnOff 0 "Pixel On" 1 "Pixel Off" ;
VAL_ 1362 ICC_LISD_Pixel255_OnOff 0 "Pixel On" 1 "Pixel Off" ;
VAL_ 1362 ICC_LISD_Pixel256_OnOff 0 "Pixel On" 1 "Pixel Off" ;
VAL_ 1362 ICC_LISD_Pixel257_OnOff 0 "Pixel On" 1 "Pixel Off" ;
VAL_ 1362 ICC_LISD_Pixel258_OnOff 0 "Pixel On" 1 "Pixel Off" ;
VAL_ 1362 ICC_LISD_Pixel259_OnOff 0 "Pixel On" 1 "Pixel Off" ;
VAL_ 1362 ICC_LISD_Pixel260_OnOff 0 "Pixel On" 1 "Pixel Off" ;
VAL_ 1362 ICC_LISD_Pixel261_OnOff 0 "Pixel On" 1 "Pixel Off" ;
VAL_ 1362 ICC_LISD_Pixel262_OnOff 0 "Pixel On" 1 "Pixel Off" ;
VAL_ 1362 ICC_LISD_Pixel263_OnOff 0 "Pixel On" 1 "Pixel Off" ;
VAL_ 1362 ICC_LISD_Pixel264_OnOff 0 "Pixel On" 1 "Pixel Off" ;
VAL_ 1362 ICC_LISD_Pixel265_OnOff 0 "Pixel On" 1 "Pixel Off" ;
VAL_ 1362 ICC_LISD_Pixel266_OnOff 0 "Pixel On" 1 "Pixel Off" ;
VAL_ 1362 ICC_LISD_Pixel267_OnOff 0 "Pixel On" 1 "Pixel Off" ;
VAL_ 1362 ICC_LISD_Pixel268_OnOff 0 "Pixel On" 1 "Pixel Off" ;
VAL_ 1362 ICC_LISD_Pixel269_OnOff 0 "Pixel On" 1 "Pixel Off" ;
VAL_ 1362 ICC_LISD_Pixel270_OnOff 0 "Pixel On" 1 "Pixel Off" ;
VAL_ 1362 ICC_LISD_Pixel271_OnOff 0 "Pixel On" 1 "Pixel Off" ;
VAL_ 1362 ICC_LISD_Pixel272_OnOff 0 "Pixel On" 1 "Pixel Off" ;
VAL_ 1362 ICC_LISD_Pixel273_OnOff 0 "Pixel On" 1 "Pixel Off" ;
VAL_ 1362 ICC_LISD_Pixel274_OnOff 0 "Pixel On" 1 "Pixel Off" ;
VAL_ 1362 ICC_LISD_Pixel275_OnOff 0 "Pixel On" 1 "Pixel Off" ;
VAL_ 1362 ICC_LISD_Pixel276_OnOff 0 "Pixel On" 1 "Pixel Off" ;
VAL_ 1362 ICC_LISD_Pixel277_OnOff 0 "Pixel On" 1 "Pixel Off" ;
VAL_ 1362 ICC_LISD_Pixel278_OnOff 0 "Pixel On" 1 "Pixel Off" ;
VAL_ 1362 ICC_LISD_Pixel279_OnOff 0 "Pixel On" 1 "Pixel Off" ;
VAL_ 1362 ICC_LISD_Pixel280_OnOff 0 "Pixel On" 1 "Pixel Off" ;
VAL_ 1362 ICC_LISD_Pixel281_OnOff 0 "Pixel On" 1 "Pixel Off" ;
VAL_ 1362 ICC_LISD_Pixel282_OnOff 0 "Pixel On" 1 "Pixel Off" ;
VAL_ 1362 ICC_LISD_Pixel283_OnOff 0 "Pixel On" 1 "Pixel Off" ;
VAL_ 1362 ICC_LISD_Pixel284_OnOff 0 "Pixel On" 1 "Pixel Off" ;
VAL_ 1362 ICC_LISD_Pixel285_OnOff 0 "Pixel On" 1 "Pixel Off" ;
VAL_ 1362 ICC_LISD_Pixel286_OnOff 0 "Pixel On" 1 "Pixel Off" ;
VAL_ 1362 ICC_LISD_Pixel287_OnOff 0 "Pixel On" 1 "Pixel Off" ;
VAL_ 1362 ICC_LISD_Pixel288_OnOff 0 "Pixel On" 1 "Pixel Off" ;
VAL_ 1362 ICC_LISD_Pixel289_OnOff 0 "Pixel On" 1 "Pixel Off" ;
VAL_ 1362 ICC_LISD_Pixel290_OnOff 0 "Pixel On" 1 "Pixel Off" ;
VAL_ 1362 ICC_LISD_Pixel291_OnOff 0 "Pixel On" 1 "Pixel Off" ;
VAL_ 1362 ICC_LISD_Pixel292_OnOff 0 "Pixel On" 1 "Pixel Off" ;
VAL_ 1362 ICC_LISD_Pixel293_OnOff 0 "Pixel On" 1 "Pixel Off" ;
VAL_ 1362 ICC_LISD_Pixel294_OnOff 0 "Pixel On" 1 "Pixel Off" ;
VAL_ 1362 ICC_LISD_Pixel295_OnOff 0 "Pixel On" 1 "Pixel Off" ;
VAL_ 1362 ICC_LISD_Pixel296_OnOff 0 "Pixel On" 1 "Pixel Off" ;
VAL_ 1362 ICC_LISD_Pixel297_OnOff 0 "Pixel On" 1 "Pixel Off" ;
VAL_ 1362 ICC_LISD_Pixel298_OnOff 0 "Pixel On" 1 "Pixel Off" ;
VAL_ 1362 ICC_LISD_Pixel299_OnOff 0 "Pixel On" 1 "Pixel Off" ;
VAL_ 1362 ICC_LISD_Pixel300_OnOff 0 "Pixel On" 1 "Pixel Off" ;
VAL_ 1362 ICC_LISD_Pixel301_OnOff 0 "Pixel On" 1 "Pixel Off" ;
VAL_ 1362 ICC_LISD_Pixel302_OnOff 0 "Pixel On" 1 "Pixel Off" ;
VAL_ 1362 ICC_LISD_Pixel303_OnOff 0 "Pixel On" 1 "Pixel Off" ;
VAL_ 1362 ICC_LISD_Pixel304_OnOff 0 "Pixel On" 1 "Pixel Off" ;
VAL_ 1362 ICC_LISD_Pixel305_OnOff 0 "Pixel On" 1 "Pixel Off" ;
VAL_ 1362 ICC_LISD_Pixel306_OnOff 0 "Pixel On" 1 "Pixel Off" ;
VAL_ 1362 ICC_LISD_Pixel307_OnOff 0 "Pixel On" 1 "Pixel Off" ;
VAL_ 1362 ICC_LISD_Pixel308_OnOff 0 "Pixel On" 1 "Pixel Off" ;
VAL_ 1362 ICC_LISD_Pixel309_OnOff 0 "Pixel On" 1 "Pixel Off" ;
VAL_ 1362 ICC_LISD_Pixel310_OnOff 0 "Pixel On" 1 "Pixel Off" ;
VAL_ 1362 ICC_LISD_Pixel311_OnOff 0 "Pixel On" 1 "Pixel Off" ;
VAL_ 1362 ICC_LISD_Pixel312_OnOff 0 "Pixel On" 1 "Pixel Off" ;
VAL_ 1362 ICC_LISD_Pixel313_OnOff 0 "Pixel On" 1 "Pixel Off" ;
VAL_ 1362 ICC_LISD_Pixel314_OnOff 0 "Pixel On" 1 "Pixel Off" ;
VAL_ 1362 ICC_LISD_Pixel315_OnOff 0 "Pixel On" 1 "Pixel Off" ;
VAL_ 1362 ICC_LISD_Pixel316_OnOff 0 "Pixel On" 1 "Pixel Off" ;
VAL_ 1362 ICC_LISD_Pixel317_OnOff 0 "Pixel On" 1 "Pixel Off" ;
VAL_ 1362 ICC_LISD_Pixel318_OnOff 0 "Pixel On" 1 "Pixel Off" ;
VAL_ 1362 ICC_LISD_Pixel319_OnOff 0 "Pixel On" 1 "Pixel Off" ;
VAL_ 1362 ICC_LISD_Pixel320_OnOff 0 "Pixel On" 1 "Pixel Off" ;
VAL_ 1362 ICC_LISD_Pixel321_OnOff 0 "Pixel On" 1 "Pixel Off" ;
VAL_ 1362 ICC_LISD_Pixel322_OnOff 0 "Pixel On" 1 "Pixel Off" ;
VAL_ 1362 ICC_LISD_Pixel323_OnOff 0 "Pixel On" 1 "Pixel Off" ;
VAL_ 1362 ICC_LISD_Pixel324_OnOff 0 "Pixel On" 1 "Pixel Off" ;
VAL_ 1362 ICC_LISD_Pixel325_OnOff 0 "Pixel On" 1 "Pixel Off" ;
VAL_ 1362 ICC_LISD_Pixel326_OnOff 0 "Pixel On" 1 "Pixel Off" ;
VAL_ 1362 ICC_LISD_Pixel327_OnOff 0 "Pixel On" 1 "Pixel Off" ;
VAL_ 1362 ICC_LISD_Pixel328_OnOff 0 "Pixel On" 1 "Pixel Off" ;
VAL_ 1362 ICC_LISD_Pixel329_OnOff 0 "Pixel On" 1 "Pixel Off" ;
VAL_ 1362 ICC_LISD_Pixel330_OnOff 0 "Pixel On" 1 "Pixel Off" ;
VAL_ 1362 ICC_LISD_Pixel331_OnOff 0 "Pixel On" 1 "Pixel Off" ;
VAL_ 1362 ICC_LISD_Pixel332_OnOff 0 "Pixel On" 1 "Pixel Off" ;
VAL_ 1362 ICC_LISD_Pixel333_OnOff 0 "Pixel On" 1 "Pixel Off" ;
VAL_ 1362 ICC_LISD_Pixel334_OnOff 0 "Pixel On" 1 "Pixel Off" ;
VAL_ 1362 ICC_LISD_Pixel335_OnOff 0 "Pixel On" 1 "Pixel Off" ;
VAL_ 1362 ICC_LISD_Pixel336_OnOff 0 "Pixel On" 1 "Pixel Off" ;
VAL_ 1362 ICC_LISD_Pixel337_OnOff 0 "Pixel On" 1 "Pixel Off" ;
VAL_ 1362 ICC_LISD_Pixel338_OnOff 0 "Pixel On" 1 "Pixel Off" ;
VAL_ 1362 ICC_LISD_Pixel339_OnOff 0 "Pixel On" 1 "Pixel Off" ;
VAL_ 1362 ICC_LISD_Pixel340_OnOff 0 "Pixel On" 1 "Pixel Off" ;
VAL_ 1362 ICC_LISD_Pixel341_OnOff 0 "Pixel On" 1 "Pixel Off" ;
VAL_ 1362 ICC_LISD_Pixel342_OnOff 0 "Pixel On" 1 "Pixel Off" ;
VAL_ 1362 ICC_LISD_Pixel343_OnOff 0 "Pixel On" 1 "Pixel Off" ;
VAL_ 1362 ICC_LISD_Pixel344_OnOff 0 "Pixel On" 1 "Pixel Off" ;
VAL_ 1362 ICC_LISD_Pixel345_OnOff 0 "Pixel On" 1 "Pixel Off" ;
VAL_ 1362 ICC_LISD_Pixel346_OnOff 0 "Pixel On" 1 "Pixel Off" ;
VAL_ 1362 ICC_LISD_Pixel347_OnOff 0 "Pixel On" 1 "Pixel Off" ;
VAL_ 1362 ICC_LISD_Pixel348_OnOff 0 "Pixel On" 1 "Pixel Off" ;
VAL_ 1362 ICC_LISD_Pixel349_OnOff 0 "Pixel On" 1 "Pixel Off" ;
VAL_ 1362 ICC_LISD_Pixel350_OnOff 0 "Pixel On" 1 "Pixel Off" ;
VAL_ 1362 ICC_LISD_Pixel351_OnOff 0 "Pixel On" 1 "Pixel Off" ;
VAL_ 1362 ICC_LISD_Pixel352_OnOff 0 "Pixel On" 1 "Pixel Off" ;
VAL_ 1362 ICC_LISD_Pixel353_OnOff 0 "Pixel On" 1 "Pixel Off" ;
VAL_ 1362 ICC_LISD_Pixel354_OnOff 0 "Pixel On" 1 "Pixel Off" ;
VAL_ 1362 ICC_LISD_Pixel355_OnOff 0 "Pixel On" 1 "Pixel Off" ;
VAL_ 1362 ICC_LISD_Pixel356_OnOff 0 "Pixel On" 1 "Pixel Off" ;
VAL_ 1362 ICC_LISD_Pixel357_OnOff 0 "Pixel On" 1 "Pixel Off" ;
VAL_ 1362 ICC_LISD_Pixel358_OnOff 0 "Pixel On" 1 "Pixel Off" ;
VAL_ 1362 ICC_LISD_Pixel359_OnOff 0 "Pixel On" 1 "Pixel Off" ;
VAL_ 1362 ICC_LISD_Pixel360_OnOff 0 "Pixel On" 1 "Pixel Off" ;
VAL_ 1362 ICC_LISD_Pixel361_OnOff 0 "Pixel On" 1 "Pixel Off" ;
VAL_ 1362 ICC_LISD_Pixel362_OnOff 0 "Pixel On" 1 "Pixel Off" ;
VAL_ 1362 ICC_LISD_Pixel363_OnOff 0 "Pixel On" 1 "Pixel Off" ;
VAL_ 1362 ICC_LISD_Pixel364_OnOff 0 "Pixel On" 1 "Pixel Off" ;
VAL_ 1362 ICC_LISD_Pixel365_OnOff 0 "Pixel On" 1 "Pixel Off" ;
VAL_ 1362 ICC_LISD_Pixel366_OnOff 0 "Pixel On" 1 "Pixel Off" ;
VAL_ 1362 ICC_LISD_Pixel367_OnOff 0 "Pixel On" 1 "Pixel Off" ;
VAL_ 1362 ICC_LISD_Pixel368_OnOff 0 "Pixel On" 1 "Pixel Off" ;
VAL_ 1362 ICC_LISD_Pixel369_OnOff 0 "Pixel On" 1 "Pixel Off" ;
VAL_ 1362 ICC_LISD_Pixel370_OnOff 0 "Pixel On" 1 "Pixel Off" ;
VAL_ 1362 ICC_LISD_Pixel371_OnOff 0 "Pixel On" 1 "Pixel Off" ;
VAL_ 1362 ICC_LISD_Pixel372_OnOff 0 "Pixel On" 1 "Pixel Off" ;
VAL_ 1362 ICC_LISD_Pixel373_OnOff 0 "Pixel On" 1 "Pixel Off" ;
VAL_ 1362 ICC_LISD_Pixel374_OnOff 0 "Pixel On" 1 "Pixel Off" ;
VAL_ 1362 ICC_LISD_Pixel375_OnOff 0 "Pixel On" 1 "Pixel Off" ;
VAL_ 1362 ICC_LISD_Pixel376_OnOff 0 "Pixel On" 1 "Pixel Off" ;
VAL_ 1362 ICC_LISD_Pixel377_OnOff 0 "Pixel On" 1 "Pixel Off" ;
VAL_ 1362 ICC_LISD_Pixel378_OnOff 0 "Pixel On" 1 "Pixel Off" ;
VAL_ 1362 ICC_LISD_Pixel379_OnOff 0 "Pixel On" 1 "Pixel Off" ;
VAL_ 1362 ICC_LISD_Pixel380_OnOff 0 "Pixel On" 1 "Pixel Off" ;
VAL_ 1362 ICC_LISD_Pixel381_OnOff 0 "Pixel On" 1 "Pixel Off" ;
VAL_ 1362 ICC_LISD_Pixel382_OnOff 0 "Pixel On" 1 "Pixel Off" ;
VAL_ 1362 ICC_LISD_Pixel383_OnOff 0 "Pixel On" 1 "Pixel Off" ;
VAL_ 1362 ICC_LISD_Pixel384_OnOff 0 "Pixel On" 1 "Pixel Off" ;
VAL_ 1362 ICC_LISD_Pixel385_OnOff 0 "Pixel On" 1 "Pixel Off" ;
VAL_ 1362 ICC_LISD_Pixel386_OnOff 0 "Pixel On" 1 "Pixel Off" ;
VAL_ 1362 ICC_LISD_Pixel387_OnOff 0 "Pixel On" 1 "Pixel Off" ;
VAL_ 1362 ICC_LISD_Pixel388_OnOff 0 "Pixel On" 1 "Pixel Off" ;
VAL_ 1362 ICC_LISD_Pixel389_OnOff 0 "Pixel On" 1 "Pixel Off" ;
VAL_ 1362 ICC_LISD_Pixel390_OnOff 0 "Pixel On" 1 "Pixel Off" ;
VAL_ 1362 ICC_LISD_Pixel391_OnOff 0 "Pixel On" 1 "Pixel Off" ;
VAL_ 1362 ICC_LISD_Pixel392_OnOff 0 "Pixel On" 1 "Pixel Off" ;
VAL_ 1362 ICC_LISD_Pixel393_OnOff 0 "Pixel On" 1 "Pixel Off" ;
VAL_ 1362 ICC_LISD_Pixel394_OnOff 0 "Pixel On" 1 "Pixel Off" ;
VAL_ 1362 ICC_LISD_Pixel395_OnOff 0 "Pixel On" 1 "Pixel Off" ;
VAL_ 1362 ICC_LISD_Pixel396_OnOff 0 "Pixel On" 1 "Pixel Off" ;
VAL_ 1362 ICC_LISD_Pixel397_OnOff 0 "Pixel On" 1 "Pixel Off" ;
VAL_ 1362 ICC_LISD_Pixel398_OnOff 0 "Pixel On" 1 "Pixel Off" ;
VAL_ 1362 ICC_LISD_Pixel399_OnOff 0 "Pixel On" 1 "Pixel Off" ;
VAL_ 1362 ICC_LISD_Pixel400_OnOff 0 "Pixel On" 1 "Pixel Off" ;
VAL_ 1362 ICC_LISD_Pixel401_OnOff 0 "Pixel On" 1 "Pixel Off" ;
VAL_ 1362 ICC_LISD_Pixel402_OnOff 0 "Pixel On" 1 "Pixel Off" ;
VAL_ 1362 ICC_LISD_Pixel403_OnOff 0 "Pixel On" 1 "Pixel Off" ;
VAL_ 1362 ICC_LISD_Pixel404_OnOff 0 "Pixel On" 1 "Pixel Off" ;
VAL_ 1362 ICC_LISD_Pixel405_OnOff 0 "Pixel On" 1 "Pixel Off" ;
VAL_ 1362 ICC_LISD_Pixel406_OnOff 0 "Pixel On" 1 "Pixel Off" ;
VAL_ 1362 ICC_LISD_Pixel407_OnOff 0 "Pixel On" 1 "Pixel Off" ;
VAL_ 1362 ICC_LISD_Pixel408_OnOff 0 "Pixel On" 1 "Pixel Off" ;
VAL_ 1362 ICC_LISD_Pixel409_OnOff 0 "Pixel On" 1 "Pixel Off" ;
VAL_ 1362 ICC_LISD_Pixel410_OnOff 0 "Pixel On" 1 "Pixel Off" ;
VAL_ 1362 ICC_LISD_Pixel411_OnOff 0 "Pixel On" 1 "Pixel Off" ;
VAL_ 1362 ICC_LISD_Pixel412_OnOff 0 "Pixel On" 1 "Pixel Off" ;
VAL_ 1362 ICC_LISD_Pixel413_OnOff 0 "Pixel On" 1 "Pixel Off" ;
VAL_ 1362 ICC_LISD_Pixel414_OnOff 0 "Pixel On" 1 "Pixel Off" ;
VAL_ 1362 ICC_LISD_Pixel415_OnOff 0 "Pixel On" 1 "Pixel Off" ;
VAL_ 1362 ICC_LISD_Pixel416_OnOff 0 "Pixel On" 1 "Pixel Off" ;
VAL_ 1362 ICC_LISD_Pixel417_OnOff 0 "Pixel On" 1 "Pixel Off" ;
VAL_ 1362 ICC_LISD_Pixel418_OnOff 0 "Pixel On" 1 "Pixel Off" ;
VAL_ 1362 ICC_LISD_Pixel419_OnOff 0 "Pixel On" 1 "Pixel Off" ;
VAL_ 1362 ICC_LISD_Pixel420_OnOff 0 "Pixel On" 1 "Pixel Off" ;
VAL_ 1362 ICC_LISD_Pixel421_OnOff 0 "Pixel On" 1 "Pixel Off" ;
VAL_ 1362 ICC_LISD_Pixel422_OnOff 0 "Pixel On" 1 "Pixel Off" ;
VAL_ 1362 ICC_LISD_Pixel423_OnOff 0 "Pixel On" 1 "Pixel Off" ;
VAL_ 1362 ICC_LISD_Pixel424_OnOff 0 "Pixel On" 1 "Pixel Off" ;
VAL_ 1362 ICC_LISD_Pixel425_OnOff 0 "Pixel On" 1 "Pixel Off" ;
VAL_ 1362 ICC_LISD_Pixel426_OnOff 0 "Pixel On" 1 "Pixel Off" ;
VAL_ 1362 ICC_LISD_Pixel427_OnOff 0 "Pixel On" 1 "Pixel Off" ;
VAL_ 1362 ICC_LISD_Pixel428_OnOff 0 "Pixel On" 1 "Pixel Off" ;
VAL_ 1362 ICC_LISD_Pixel429_OnOff 0 "Pixel On" 1 "Pixel Off" ;
VAL_ 1362 ICC_LISD_Pixel430_OnOff 0 "Pixel On" 1 "Pixel Off" ;
VAL_ 1362 ICC_LISD_Pixel431_OnOff 0 "Pixel On" 1 "Pixel Off" ;
VAL_ 1362 ICC_LISD_Pixel432_OnOff 0 "Pixel On" 1 "Pixel Off" ;
VAL_ 1362 ICC_LISD_Pixel433_OnOff 0 "Pixel On" 1 "Pixel Off" ;
VAL_ 1362 ICC_LISD_Pixel434_OnOff 0 "Pixel On" 1 "Pixel Off" ;
VAL_ 1362 ICC_LISD_Pixel435_OnOff 0 "Pixel On" 1 "Pixel Off" ;
VAL_ 1362 ICC_LISD_Pixel436_OnOff 0 "Pixel On" 1 "Pixel Off" ;
VAL_ 1362 ICC_LISD_Pixel437_OnOff 0 "Pixel On" 1 "Pixel Off" ;
VAL_ 1362 ICC_LISD_Pixel438_OnOff 0 "Pixel On" 1 "Pixel Off" ;
VAL_ 1362 ICC_LISD_Pixel439_OnOff 0 "Pixel On" 1 "Pixel Off" ;
VAL_ 1362 ICC_LISD_Pixel440_OnOff 0 "Pixel On" 1 "Pixel Off" ;
VAL_ 1362 ICC_LISD_Pixel441_OnOff 0 "Pixel On" 1 "Pixel Off" ;
VAL_ 1362 ICC_LISD_Pixel442_OnOff 0 "Pixel On" 1 "Pixel Off" ;
VAL_ 1362 ICC_LISD_Pixel443_OnOff 0 "Pixel On" 1 "Pixel Off" ;
VAL_ 1362 ICC_LISD_Pixel444_OnOff 0 "Pixel On" 1 "Pixel Off" ;
VAL_ 1362 ICC_LISD_Pixel445_OnOff 0 "Pixel On" 1 "Pixel Off" ;
VAL_ 1362 ICC_LISD_Pixel446_OnOff 0 "Pixel On" 1 "Pixel Off" ;
VAL_ 1362 ICC_LISD_Pixel447_OnOff 0 "Pixel On" 1 "Pixel Off" ;
VAL_ 1362 ICC_LISD_Pixel448_OnOff 0 "Pixel On" 1 "Pixel Off" ;
VAL_ 1362 ICC_LISD_Pixel449_OnOff 0 "Pixel On" 1 "Pixel Off" ;
VAL_ 1362 ICC_LISD_Pixel450_OnOff 0 "Pixel On" 1 "Pixel Off" ;
VAL_ 1362 ICC_LISD_Pixel451_OnOff 0 "Pixel On" 1 "Pixel Off" ;
VAL_ 1362 ICC_LISD_Pixel452_OnOff 0 "Pixel On" 1 "Pixel Off" ;
VAL_ 1362 ICC_LISD_Pixel453_OnOff 0 "Pixel On" 1 "Pixel Off" ;
VAL_ 1362 ICC_LISD_Pixel454_OnOff 0 "Pixel On" 1 "Pixel Off" ;
VAL_ 1362 ICC_LISD_Pixel455_OnOff 0 "Pixel On" 1 "Pixel Off" ;
VAL_ 1362 ICC_LISD_Pixel456_OnOff 0 "Pixel On" 1 "Pixel Off" ;
VAL_ 1362 ICC_LISD_Pixel457_OnOff 0 "Pixel On" 1 "Pixel Off" ;
VAL_ 1362 ICC_LISD_Pixel458_OnOff 0 "Pixel On" 1 "Pixel Off" ;
VAL_ 1362 ICC_LISD_Pixel459_OnOff 0 "Pixel On" 1 "Pixel Off" ;
VAL_ 1362 ICC_LISD_Pixel460_OnOff 0 "Pixel On" 1 "Pixel Off" ;
VAL_ 1362 ICC_LISD_Pixel461_OnOff 0 "Pixel On" 1 "Pixel Off" ;
VAL_ 1362 ICC_LISD_Pixel462_OnOff 0 "Pixel On" 1 "Pixel Off" ;
VAL_ 1362 ICC_LISD_Pixel463_OnOff 0 "Pixel On" 1 "Pixel Off" ;
VAL_ 1362 ICC_LISD_Pixel464_OnOff 0 "Pixel On" 1 "Pixel Off" ;
VAL_ 1362 ICC_LISD_Pixel465_OnOff 0 "Pixel On" 1 "Pixel Off" ;
VAL_ 1362 ICC_LISD_Pixel466_OnOff 0 "Pixel On" 1 "Pixel Off" ;
VAL_ 1362 ICC_LISD_Pixel467_OnOff 0 "Pixel On" 1 "Pixel Off" ;
VAL_ 1362 ICC_LISD_Pixel468_OnOff 0 "Pixel On" 1 "Pixel Off" ;
VAL_ 1362 ICC_LISD_Pixel469_OnOff 0 "Pixel On" 1 "Pixel Off" ;
VAL_ 1362 ICC_LISD_Pixel470_OnOff 0 "Pixel On" 1 "Pixel Off" ;
VAL_ 1362 ICC_LISD_Pixel471_OnOff 0 "Pixel On" 1 "Pixel Off" ;
VAL_ 1362 ICC_LISD_Pixel472_OnOff 0 "Pixel On" 1 "Pixel Off" ;
VAL_ 1362 ICC_LISD_Pixel473_OnOff 0 "Pixel On" 1 "Pixel Off" ;
VAL_ 1362 ICC_LISD_Pixel474_OnOff 0 "Pixel On" 1 "Pixel Off" ;
VAL_ 1362 ICC_LISD_Pixel475_OnOff 0 "Pixel On" 1 "Pixel Off" ;
VAL_ 1362 ICC_LISD_Pixel476_OnOff 0 "Pixel On" 1 "Pixel Off" ;
VAL_ 1362 ICC_LISD_Pixel477_OnOff 0 "Pixel On" 1 "Pixel Off" ;
VAL_ 1362 ICC_LISD_Pixel478_OnOff 0 "Pixel On" 1 "Pixel Off" ;
VAL_ 1362 ICC_LISD_Pixel479_OnOff 0 "Pixel On" 1 "Pixel Off" ;
VAL_ 1362 ICC_LISD_Pixel480_OnOff 0 "Pixel On" 1 "Pixel Off" ;
VAL_ 1362 ICC_LISD_Pixel481_OnOff 0 "Pixel On" 1 "Pixel Off" ;
VAL_ 1362 ICC_LISD_Pixel482_OnOff 0 "Pixel On" 1 "Pixel Off" ;
VAL_ 1362 ICC_LISD_Pixel483_OnOff 0 "Pixel On" 1 "Pixel Off" ;
VAL_ 1362 ICC_LISD_Pixel484_OnOff 0 "Pixel On" 1 "Pixel Off" ;
VAL_ 1362 ICC_LISD_Pixel485_OnOff 0 "Pixel On" 1 "Pixel Off" ;
VAL_ 1362 ICC_LISD_Pixel486_OnOff 0 "Pixel On" 1 "Pixel Off" ;
VAL_ 1362 ICC_LISD_Pixel487_OnOff 0 "Pixel On" 1 "Pixel Off" ;
VAL_ 1362 ICC_LISD_Pixel488_OnOff 0 "Pixel On" 1 "Pixel Off" ;
VAL_ 1362 ICC_LISD_Pixel489_OnOff 0 "Pixel On" 1 "Pixel Off" ;
VAL_ 1362 ICC_LISD_Pixel490_OnOff 0 "Pixel On" 1 "Pixel Off" ;
VAL_ 1362 ICC_LISD_Pixel491_OnOff 0 "Pixel On" 1 "Pixel Off" ;
VAL_ 1362 ICC_LISD_Pixel492_OnOff 0 "Pixel On" 1 "Pixel Off" ;
VAL_ 1362 ICC_LISD_Pixel493_OnOff 0 "Pixel On" 1 "Pixel Off" ;
VAL_ 1362 ICC_LISD_Pixel494_OnOff 0 "Pixel On" 1 "Pixel Off" ;
VAL_ 1362 ICC_LISD_Pixel495_OnOff 0 "Pixel On" 1 "Pixel Off" ;
VAL_ 1362 ICC_LISD_Pixel496_OnOff 0 "Pixel On" 1 "Pixel Off" ;
VAL_ 1362 ICC_LISD_Pixel497_OnOff 0 "Pixel On" 1 "Pixel Off" ;
VAL_ 1362 ICC_LISD_Pixel498_OnOff 0 "Pixel On" 1 "Pixel Off" ;
VAL_ 1362 ICC_LISD_Pixel499_OnOff 0 "Pixel On" 1 "Pixel Off" ;
VAL_ 1362 ICC_LISD_Pixel500_OnOff 0 "Pixel On" 1 "Pixel Off" ;
VAL_ 1362 ICC_LISD_Pixel501_OnOff 0 "Pixel On" 1 "Pixel Off" ;
VAL_ 1362 ICC_LISD_Pixel502_OnOff 0 "Pixel On" 1 "Pixel Off" ;
VAL_ 1362 ICC_LISD_Pixel503_OnOff 0 "Pixel On" 1 "Pixel Off" ;
VAL_ 1362 ICC_LISD_Pixel504_OnOff 0 "Pixel On" 1 "Pixel Off" ;
